VERSION ""

NS_ :

BS_:

BU_: ECM

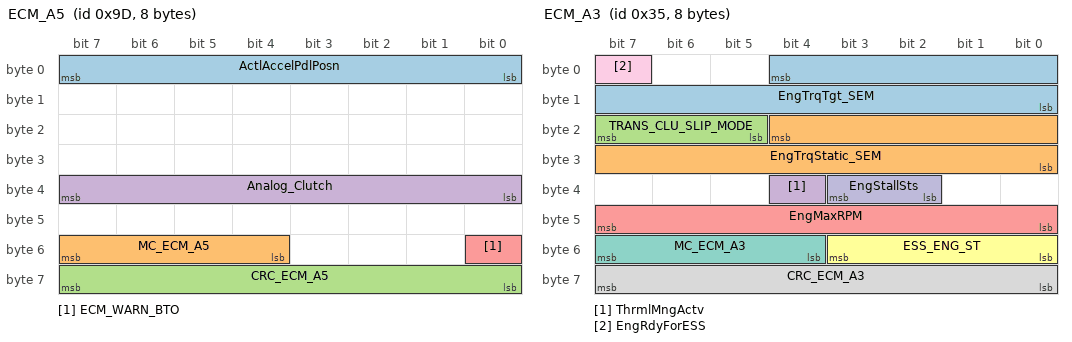
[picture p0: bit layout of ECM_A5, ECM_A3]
BO_ 157 ECM_A5: 8 ECM
 SG_ ActlAccelPdlPosn : 0|8@1+ (0.4,0) [0|100] "%"  Vector__XXX
 SG_ MC_ECM_A5 : 52|4@1+ (1,0) [0|15] "" Vector__XXX
 SG_ CRC_ECM_A5 : 56|8@1+ (1,0) [0|0] "" Vector__XXX
 SG_ Analog_Clutch : 32|8@1+ (0.4,0) [0|100] "%"  Vector__XXX
 SG_ ECM_WARN_BTO : 48|1@1+ (1,0) [0|0] "" Vector__XXX

BO_ 53 ECM_A3: 8 ECM
 SG_ EngTrqTgt_SEM : 4|13@0+ (0.25,-500) [-500|1547.5] "Nm"  Vector__XXX
 SG_ EngTrqStatic_SEM : 20|13@0+ (0.25,-500) [-500|1547.5] "Nm"  Vector__XXX
 SG_ TRANS_CLU_SLIP_MODE : 21|3@1+ (1,0) [0|0] "" Vector__XXX
 SG_ ThrmlMngActv : 36|1@1+ (1,0) [0|0] "" Vector__XXX
 SG_ EngMaxRPM : 40|8@1+ (50,0) [0|12700] "rpm"  Vector__XXX
 SG_ ESS_ENG_ST : 48|4@1+ (1,0) [0|0] "" Vector__XXX
 SG_ MC_ECM_A3 : 52|4@1+ (1,0) [0|15] "" Vector__XXX
 SG_ CRC_ECM_A3 : 56|8@1+ (1,0) [0|0] "" Vector__XXX
 SG_ EngRdyForESS : 7|1@1+ (1,0) [0|0] "" Vector__XXX
 SG_ EngStallSts : 34|2@1+ (1,0) [0|0] "" Vector__XXX

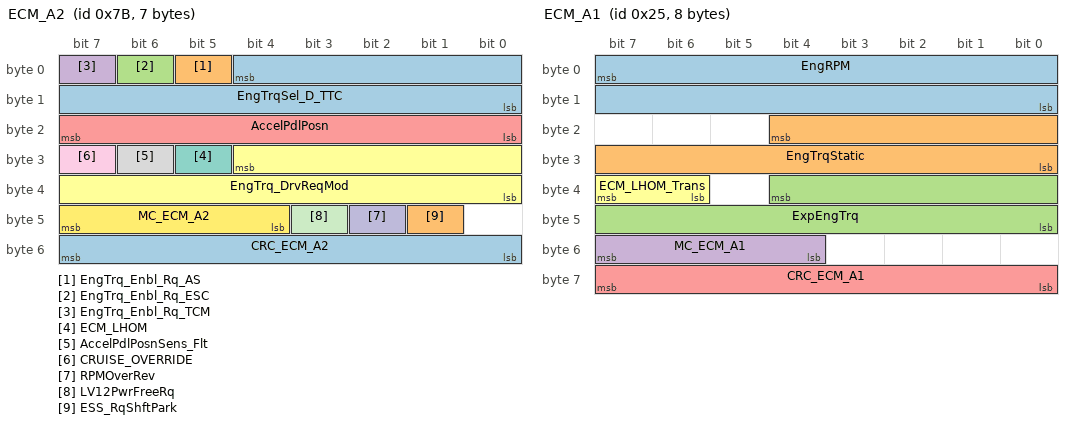
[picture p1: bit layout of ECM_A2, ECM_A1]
BO_ 123 ECM_A2: 7 ECM
 SG_ EngTrqSel_D_TTC : 4|13@0+ (0.25,-500) [-500|1547.5] "Nm"  Vector__XXX
 SG_ EngTrq_Enbl_Rq_AS : 5|1@1+ (1,0) [0|0] "" Vector__XXX
 SG_ EngTrq_Enbl_Rq_ESC : 6|1@1+ (1,0) [0|0] "" Vector__XXX
 SG_ EngTrq_Enbl_Rq_TCM : 7|1@1+ (1,0) [0|0] "" Vector__XXX
 SG_ AccelPdlPosn : 16|8@1+ (0.4,0) [0|100] "%"  Vector__XXX
 SG_ EngTrq_DrvReqMod : 28|13@0+ (0.25,-500) [-500|1547.5] "Nm"  Vector__XXX
 SG_ ECM_LHOM : 29|1@1+ (1,0) [0|0] "" Vector__XXX
 SG_ AccelPdlPosnSens_Flt : 30|1@1+ (1,0) [0|0] "" Vector__XXX
 SG_ CRUISE_OVERRIDE : 31|1@1+ (1,0) [0|0] "" Vector__XXX
 SG_ RPMOverRev : 42|1@1+ (1,0) [0|0] "" Vector__XXX
 SG_ LV12PwrFreeRq : 43|1@1+ (1,0) [0|0] "" Vector__XXX
 SG_ MC_ECM_A2 : 44|4@1+ (1,0) [0|15] "" Vector__XXX
 SG_ CRC_ECM_A2 : 48|8@1+ (1,0) [0|0] "" Vector__XXX
 SG_ ESS_RqShftPark : 41|1@1+ (1,0) [0|0] "" Vector__XXX

BO_ 37 ECM_A1: 8 ECM
 SG_ EngRPM : 7|16@0+ (1,0) [0|65534] "rpm"  Vector__XXX
 SG_ EngTrqStatic : 20|13@0+ (0.25,-500) [-500|1547.5] "Nm"  Vector__XXX
 SG_ ExpEngTrq : 36|13@0+ (0.25,-500) [-500|1547.5] "Nm"  Vector__XXX
 SG_ MC_ECM_A1 : 52|4@1+ (1,0) [0|15] "" Vector__XXX
 SG_ CRC_ECM_A1 : 56|8@1+ (1,0) [0|0] "" Vector__XXX
 SG_ ECM_LHOM_Trans : 38|2@1+ (1,0) [0|0] "" Vector__XXX

BO_ 631 DTCM_B1: 8 Vector__XXX
 SG_ TCASE_FAIL : 0|1@1+ (1,0) [0|0] "" ECM

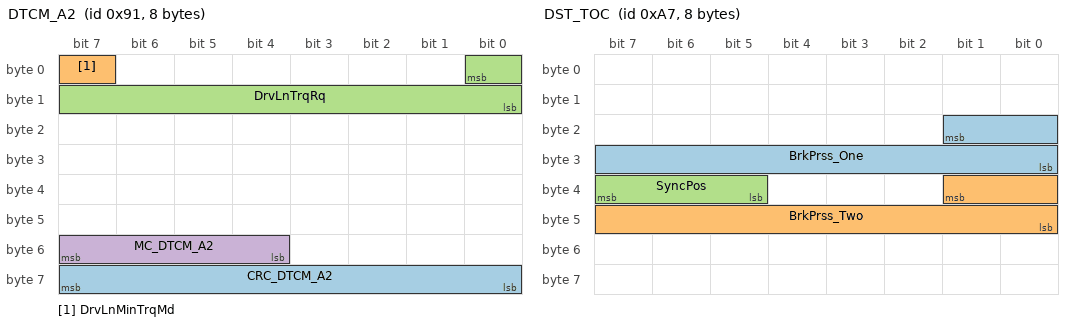
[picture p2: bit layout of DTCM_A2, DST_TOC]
BO_ 145 DTCM_A2: 8 Vector__XXX
 SG_ CRC_DTCM_A2 : 56|8@1+ (1,0) [0|0] "" ECM
 SG_ DrvLnMinTrqMd : 7|1@1+ (1,0) [0|0] "" ECM
 SG_ DrvLnTrqRq : 0|9@0+ (2,0) [0|1020] "Nm"  ECM
 SG_ MC_DTCM_A2 : 52|4@1+ (1,0) [0|15] "" ECM

BO_ 141 DTCM_A1: 8 Vector__XXX
 SG_ TCASE_STAT : 1|3@1+ (1,0) [0|0] "" ECM
 SG_ TCASERANGESTATUS : 12|2@1+ (1,0) [0|0] "" ECM

BO_ 167 DST_TOC: 8 Vector__XXX
 SG_ BrkPrss_One : 17|10@0+ (0.0048828125,0) [0|4.9951171875] "Volts"  ECM
 SG_ BrkPrss_Two : 33|10@0+ (0.0048828125,0) [0|4.9951171875] "Volts"  ECM
 SG_ SyncPos : 37|3@1+ (1,0) [0|0] "" ECM

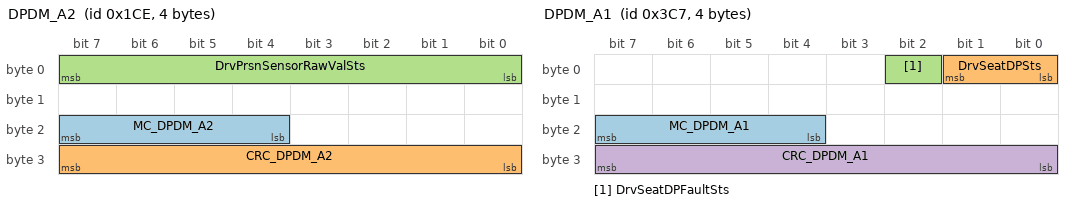
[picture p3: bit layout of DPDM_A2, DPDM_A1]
BO_ 462 DPDM_A2: 4 Vector__XXX
 SG_ MC_DPDM_A2 : 20|4@1+ (1,0) [0|15] "" ECM
 SG_ CRC_DPDM_A2 : 24|8@1+ (1,0) [0|0] "" ECM
 SG_ DrvPrsnSensorRawValSts : 0|8@1+ (1,0) [0|255] "" ECM

BO_ 967 DPDM_A1: 4 Vector__XXX
 SG_ MC_DPDM_A1 : 20|4@1+ (1,0) [0|15] "" ECM
 SG_ DrvSeatDPSts : 0|2@1+ (1,0) [0|0] "" ECM
 SG_ DrvSeatDPFaultSts : 2|1@1+ (1,0) [0|0] "" ECM
 SG_ CRC_DPDM_A1 : 24|8@1+ (1,0) [0|0] "" ECM

BO_ 163 DAS_A5: 8 Vector__XXX
 SG_ DsrSpeed_KPH : 24|8@1+ (1,0) [0|250] "km/h"  ECM

BO_ 232 DAS_A4: 8 Vector__XXX
 SG_ SetSpeed_KPH : 8|8@1+ (1,0) [0|250] "km/h"  ECM
 SG_ ACCOnOff : 36|3@1+ (1,0) [0|0] "" ECM

BO_ 153 DAS_A3: 8 Vector__XXX
 SG_ DAS_ACCEL_Rq : 19|12@0+ (0.004885,-16) [-16|4] "m/s²"  ECM

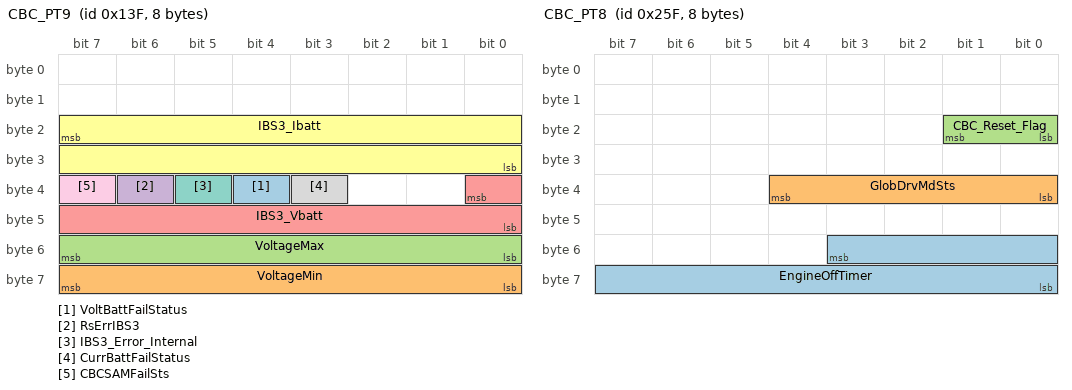
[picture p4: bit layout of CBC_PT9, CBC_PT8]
BO_ 319 CBC_PT9: 8 Vector__XXX
 SG_ VoltBattFailStatus : 36|1@1+ (1,0) [0|0] "" ECM
 SG_ VoltageMin : 56|8@1+ (0.025,10.6) [10.6|16.975] "Volts"  ECM
 SG_ VoltageMax : 48|8@1+ (0.025,10.6) [10.6|16.975] "Volts"  ECM
 SG_ RsErrIBS3 : 38|1@1+ (1,0) [0|0] "" ECM
 SG_ IBS3_Vbatt : 32|9@0+ (0.025,5) [5|17.75] "V"  ECM
 SG_ IBS3_Ibatt : 23|16@0+ (0.02,-1000) [-1000|310.68] "A"  ECM
 SG_ IBS3_Error_Internal : 37|1@1+ (1,0) [0|0] "" ECM
 SG_ CurrBattFailStatus : 35|1@1+ (1,0) [0|0] "" ECM
 SG_ CBCSAMFailSts : 39|1@1+ (1,0) [0|0] "" ECM

BO_ 607 CBC_PT8: 8 Vector__XXX
 SG_ EngineOffTimer : 51|12@0+ (1,0) [0|4080] "min"  ECM
 SG_ GlobDrvMdSts : 32|5@1+ (1,0) [0|0] "" ECM
 SG_ CBC_Reset_Flag : 16|2@1+ (1,0) [0|0] "" ECM

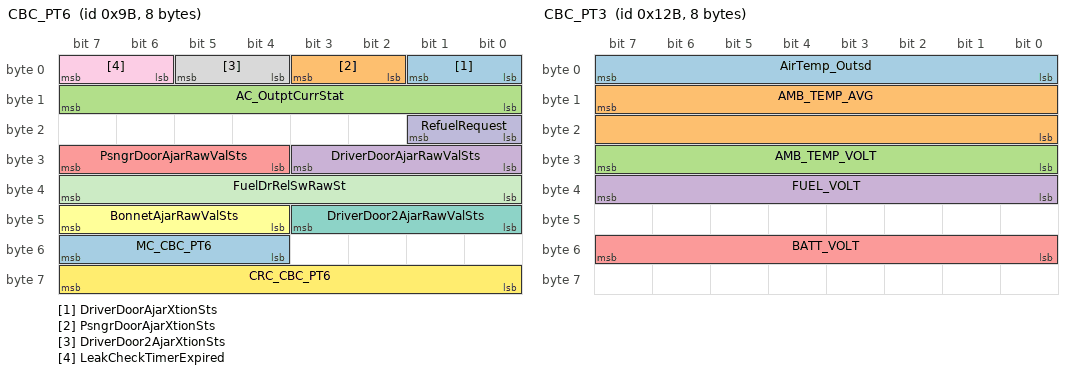
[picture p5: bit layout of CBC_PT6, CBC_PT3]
BO_ 155 CBC_PT6: 8 Vector__XXX
 SG_ DriverDoorAjarXtionSts : 0|2@1+ (1,0) [0|0] "" ECM
 SG_ PsngrDoorAjarXtionSts : 2|2@1+ (1,0) [0|0] "" ECM
 SG_ AC_OutptCurrStat : 8|8@1+ (0.008,0) [0|2] "Amp"  ECM
 SG_ DriverDoorAjarRawValSts : 24|4@1+ (1,0) [0|0] "" ECM
 SG_ PsngrDoorAjarRawValSts : 28|4@1+ (1,0) [0|0] "" ECM
 SG_ BonnetAjarRawValSts : 44|4@1+ (1,0) [0|0] "" ECM
 SG_ DriverDoor2AjarRawValSts : 40|4@1+ (1,0) [0|0] "" ECM
 SG_ DriverDoor2AjarXtionSts : 4|2@1+ (1,0) [0|0] "" ECM
 SG_ LeakCheckTimerExpired : 6|2@1+ (1,0) [0|0] "" ECM
 SG_ RefuelRequest : 16|2@1+ (1,0) [0|0] "" ECM
 SG_ FuelDrRelSwRawSt : 32|8@1+ (0.019607843,0) [0|4.98] "Volts"  ECM
 SG_ CRC_CBC_PT6 : 56|8@1+ (1,0) [0|0] "" ECM
 SG_ MC_CBC_PT6 : 52|4@1+ (1,0) [0|15] "" ECM

BO_ 299 CBC_PT3: 8 Vector__XXX
 SG_ AirTemp_Outsd : 0|8@1+ (0.5,-40) [-40|85] "°C"  ECM
 SG_ AMB_TEMP_AVG : 15|16@0+ (0.01,-40) [-40|85] "°C"  ECM
 SG_ AMB_TEMP_VOLT : 24|8@1+ (0.019607843,0) [0|4.98] "Volts"  ECM
 SG_ FUEL_VOLT : 32|8@1+ (0.019607843,0) [0|4.98] "Volts"  ECM
 SG_ BATT_VOLT : 48|8@1+ (0.1,0) [5|18] "Volts"  ECM

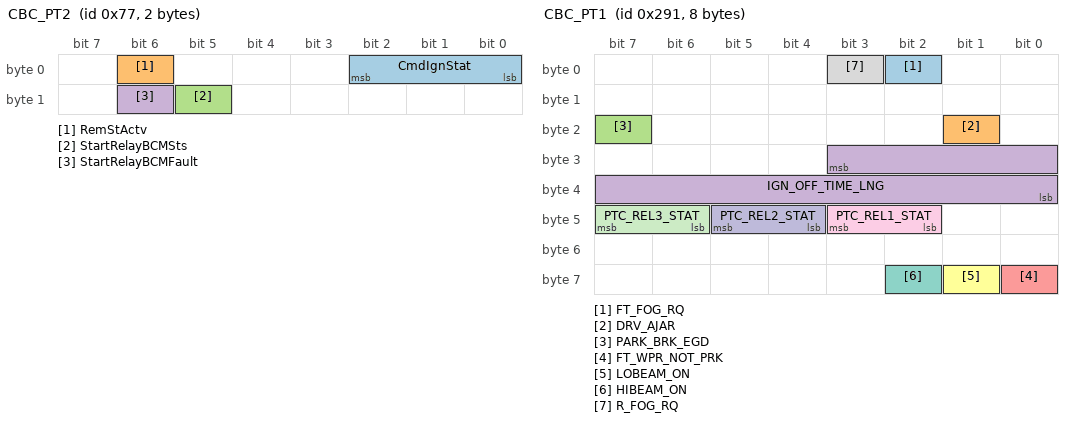
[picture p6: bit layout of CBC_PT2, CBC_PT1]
BO_ 119 CBC_PT2: 2 Vector__XXX
 SG_ CmdIgnStat : 0|3@1+ (1,0) [0|0] "" ECM
 SG_ RemStActv : 6|1@1+ (1,0) [0|0] "" ECM
 SG_ StartRelayBCMSts : 13|1@1+ (1,0) [0|0] "" ECM
 SG_ StartRelayBCMFault : 14|1@1+ (1,0) [0|0] "" ECM

BO_ 657 CBC_PT1: 8 Vector__XXX
 SG_ FT_FOG_RQ : 2|1@1+ (1,0) [0|0] "" ECM
 SG_ DRV_AJAR : 17|1@1+ (1,0) [0|0] "" ECM
 SG_ PARK_BRK_EGD : 23|1@1+ (1,0) [0|0] "" ECM
 SG_ IGN_OFF_TIME_LNG : 27|12@0+ (1,0) [0|4080] "min"  ECM
 SG_ FT_WPR_NOT_PRK : 56|1@1+ (1,0) [0|0] "" ECM
 SG_ LOBEAM_ON : 57|1@1+ (1,0) [0|0] "" ECM
 SG_ HIBEAM_ON : 58|1@1+ (1,0) [0|0] "" ECM
 SG_ R_FOG_RQ : 3|1@1+ (1,0) [0|0] "" ECM
 SG_ PTC_REL1_STAT : 42|2@1+ (1,0) [0|0] "" ECM
 SG_ PTC_REL2_STAT : 44|2@1+ (1,0) [0|0] "" ECM
 SG_ PTC_REL3_STAT : 46|2@1+ (1,0) [0|0] "" ECM

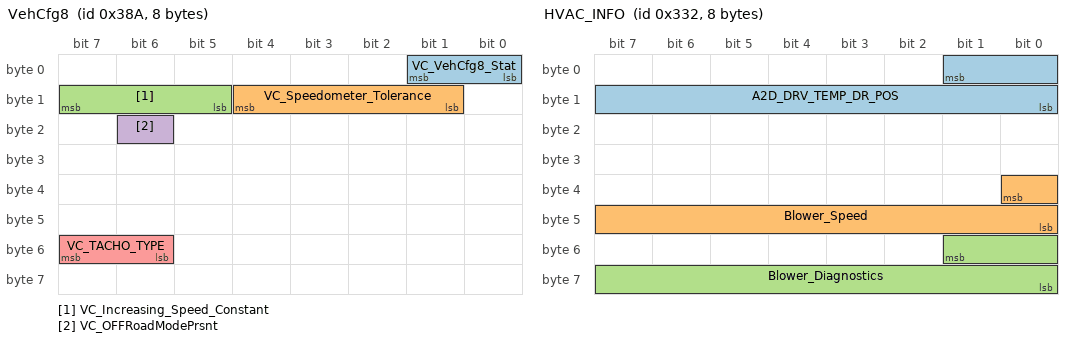
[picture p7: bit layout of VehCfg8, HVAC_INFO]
BO_ 906 VehCfg8: 8 Vector__XXX
 SG_ VC_VehCfg8_Stat : 0|2@1+ (1,0) [0|0] "" ECM
 SG_ VC_Speedometer_Tolerance : 9|4@1+ (1,0) [0|0] "" ECM
 SG_ VC_Increasing_Speed_Constant : 13|3@1+ (1,0) [0|0] "" ECM
 SG_ VC_OFFRoadModePrsnt : 22|1@1+ (1,0) [0|0] "" ECM
 SG_ VC_TACHO_TYPE : 54|2@1+ (1,0) [0|0] "" ECM

BO_ 738 ESP_B4: 8 Vector__XXX
 SG_ REPRGD_PFC_CLR_ESC : 22|1@1+ (1,0) [0|0] "" ECM

BO_ 818 HVAC_INFO: 8 Vector__XXX
 SG_ A2D_DRV_TEMP_DR_POS : 1|10@0+ (0.00489237,0) [0|5] "V"  ECM
 SG_ Blower_Speed : 32|9@0+ (1,0) [0|350] "Hz"  ECM
 SG_ Blower_Diagnostics : 49|10@0+ (0.1,0) [0|100] "%"  ECM

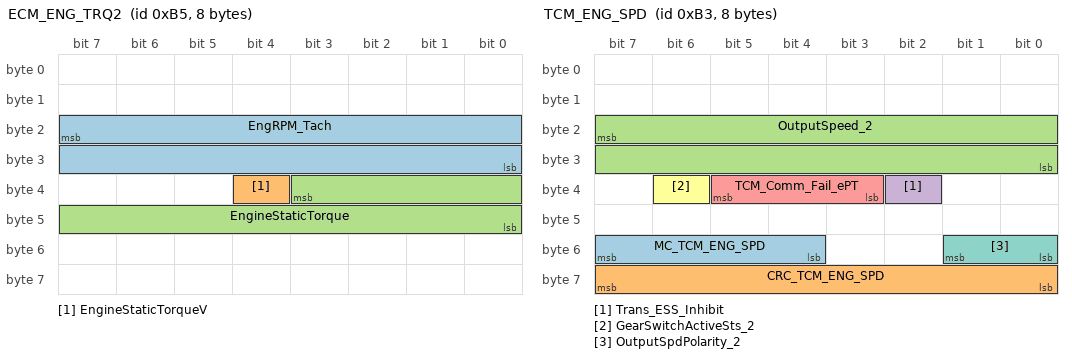
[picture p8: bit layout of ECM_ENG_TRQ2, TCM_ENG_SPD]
BO_ 181 ECM_ENG_TRQ2: 8 ECM
 SG_ EngRPM_Tach : 23|16@0+ (1,0) [0|65534] "RPM"  Vector__XXX
 SG_ EngineStaticTorqueV : 36|1@1+ (1,0) [0|0] "" Vector__XXX
 SG_ EngineStaticTorque : 35|12@0+ (0.32,-300.16) [-300.16|1008] "Nm"  Vector__XXX

BO_ 833 GPF_DATA_1: 8 Vector__XXX
 SG_ GPF_T1_Status : 48|5@1+ (1,0) [0|0] "" ECM
 SG_ GPF_T1_TEMP : 7|16@0+ (0.03125,-273) [-273|1774.97] "deg"  ECM

BO_ 179 TCM_ENG_SPD: 8 Vector__XXX
 SG_ MC_TCM_ENG_SPD : 52|4@1+ (1,0) [0|15] "" ECM
 SG_ CRC_TCM_ENG_SPD : 56|8@1+ (1,0) [0|0] "" ECM
 SG_ OutputSpeed_2 : 23|16@0+ (1,0) [0|65534] "rpm"  ECM
 SG_ Trans_ESS_Inhibit : 34|1@1+ (1,0) [0|0] "" ECM
 SG_ TCM_Comm_Fail_ePT : 35|3@1+ (1,0) [0|0] "" ECM
 SG_ GearSwitchActiveSts_2 : 38|1@1+ (1,0) [0|0] "" ECM
 SG_ OutputSpdPolarity_2 : 48|2@1+ (1,0) [0|0] "" ECM

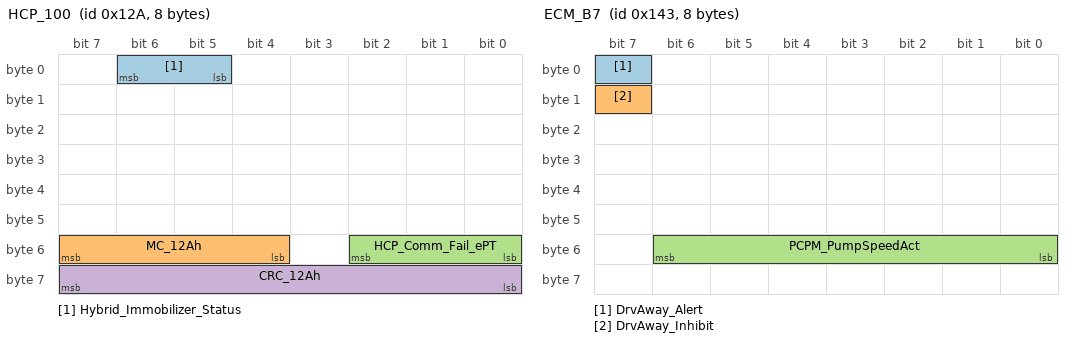
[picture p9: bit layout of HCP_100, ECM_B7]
BO_ 298 HCP_100: 8 Vector__XXX
 SG_ Hybrid_Immobilizer_Status : 5|2@1+ (1,0) [0|0] "" ECM
 SG_ MC_12Ah : 52|4@1+ (1,0) [0|15] "" ECM
 SG_ HCP_Comm_Fail_ePT : 48|3@1+ (1,0) [0|0] "" ECM
 SG_ CRC_12Ah : 56|8@1+ (1,0) [0|0] "" ECM

BO_ 307 CBC_PT7: 8 Vector__XXX
 SG_ AM_ECM_Trace : 22|2@1+ (1,0) [0|0] "" ECM

BO_ 323 ECM_B7: 8 ECM
 SG_ DrvAway_Alert : 7|1@1+ (1,0) [0|0] "" Vector__XXX
 SG_ DrvAway_Inhibit : 15|1@1+ (1,0) [0|0] "" Vector__XXX
 SG_ PCPM_PumpSpeedAct : 48|7@1+ (1,0) [0|100] "%"  Vector__XXX

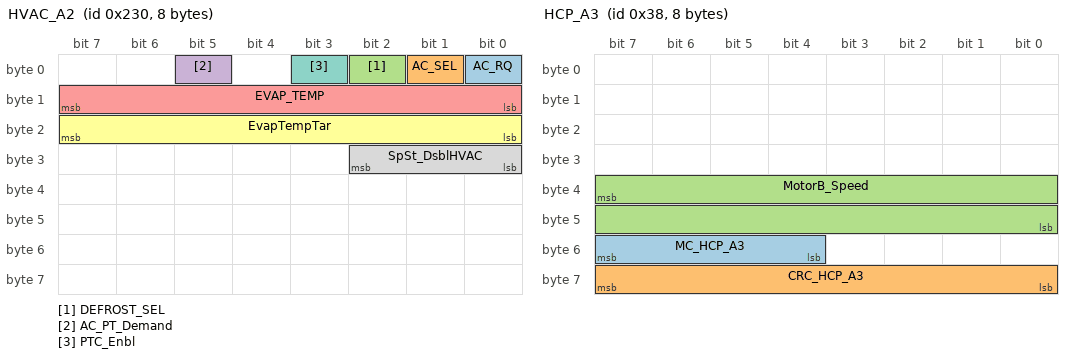
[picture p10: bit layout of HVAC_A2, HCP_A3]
BO_ 560 HVAC_A2: 8 Vector__XXX
 SG_ AC_RQ : 0|1@1+ (1,0) [0|0] "" ECM
 SG_ AC_SEL : 1|1@1+ (1,0) [0|0] "" ECM
 SG_ DEFROST_SEL : 2|1@1+ (1,0) [0|0] "" ECM
 SG_ AC_PT_Demand : 5|1@1+ (1,0) [0|0] "" ECM
 SG_ EVAP_TEMP : 8|8@1+ (0.5,-20) [-20|107] "°C"  ECM
 SG_ EvapTempTar : 16|8@1+ (0.5,-20) [-20|107] "°C"  ECM
 SG_ PTC_Enbl : 3|1@1+ (1,0) [0|0] "" ECM
 SG_ SpSt_DsblHVAC : 24|3@1+ (1,0) [0|0] "" ECM

BO_ 56 HCP_A3: 8 Vector__XXX
 SG_ MC_HCP_A3 : 52|4@1+ (1,0) [0|15] "" ECM
 SG_ CRC_HCP_A3 : 56|8@1+ (1,0) [0|0] "" ECM
 SG_ MotorB_Speed : 39|16@0+ (1,-16382) [-16382|49151] "rpm"  ECM

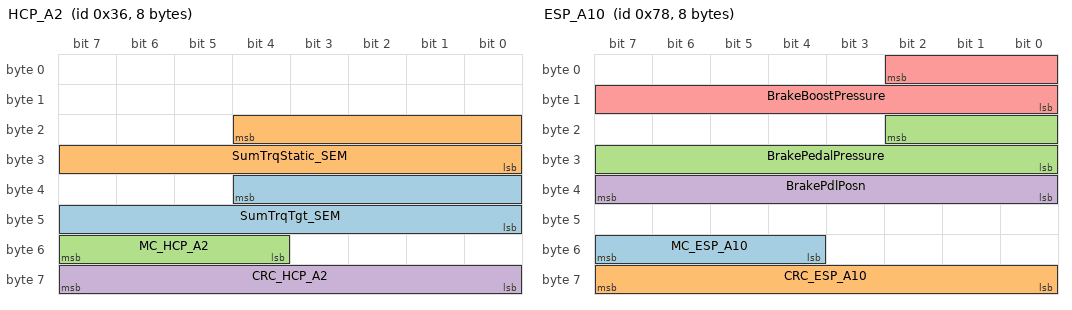
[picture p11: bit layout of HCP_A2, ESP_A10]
BO_ 54 HCP_A2: 8 Vector__XXX
 SG_ SumTrqTgt_SEM : 36|13@0+ (0.25,-500) [-500|1547.5] "Nm"  ECM
 SG_ SumTrqStatic_SEM : 20|13@0+ (0.25,-500) [-500|1547.5] "Nm"  ECM
 SG_ MC_HCP_A2 : 52|4@1+ (1,0) [0|15] "" ECM
 SG_ CRC_HCP_A2 : 56|8@1+ (1,0) [0|0] "" ECM

BO_ 40 HCP_A1: 8 Vector__XXX
 SG_ MC_HCP_A1 : 52|4@1+ (1,0) [0|15] "" ECM
 SG_ CRC_HCP_A1 : 56|8@1+ (1,0) [0|0] "" ECM

BO_ 120 ESP_A10: 8 Vector__XXX
 SG_ MC_ESP_A10 : 52|4@1+ (1,0) [0|15] "" ECM
 SG_ CRC_ESP_A10 : 56|8@1+ (1,0) [0|0] "" ECM
 SG_ BrakePedalPressure : 18|11@0+ (0.1,0) [0|200] "bar"  ECM
 SG_ BrakePdlPosn : 32|8@1+ (0.4,0) [0|100] "%"  ECM
 SG_ BrakeBoostPressure : 2|11@0+ (0.1,0) [0|200] "bar"  ECM

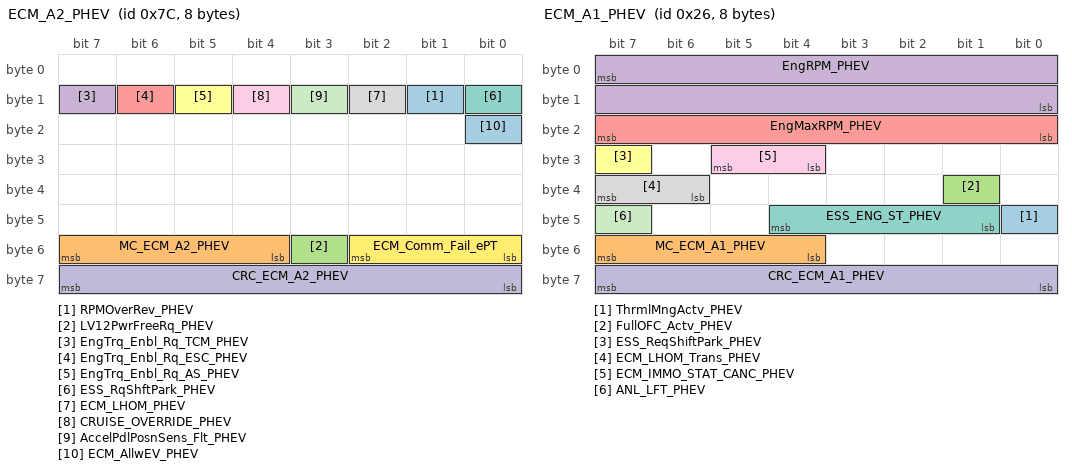
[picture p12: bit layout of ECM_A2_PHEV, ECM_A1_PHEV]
BO_ 124 ECM_A2_PHEV: 8 ECM
 SG_ RPMOverRev_PHEV : 9|1@1+ (1,0) [0|0] "" Vector__XXX
 SG_ MC_ECM_A2_PHEV : 52|4@1+ (1,0) [0|15] "" Vector__XXX
 SG_ LV12PwrFreeRq_PHEV : 51|1@1+ (1,0) [0|0] "" Vector__XXX
 SG_ EngTrq_Enbl_Rq_TCM_PHEV : 15|1@1+ (1,0) [0|0] "" Vector__XXX
 SG_ EngTrq_Enbl_Rq_ESC_PHEV : 14|1@1+ (1,0) [0|0] "" Vector__XXX
 SG_ EngTrq_Enbl_Rq_AS_PHEV : 13|1@1+ (1,0) [0|0] "" Vector__XXX
 SG_ ESS_RqShftPark_PHEV : 8|1@1+ (1,0) [0|0] "" Vector__XXX
 SG_ ECM_LHOM_PHEV : 10|1@1+ (1,0) [0|0] "" Vector__XXX
 SG_ CRUISE_OVERRIDE_PHEV : 12|1@1+ (1,0) [0|0] "" Vector__XXX
 SG_ CRC_ECM_A2_PHEV : 56|8@1+ (1,0) [0|0] "" Vector__XXX
 SG_ AccelPdlPosnSens_Flt_PHEV : 11|1@1+ (1,0) [0|0] "" Vector__XXX
 SG_ ECM_Comm_Fail_ePT : 48|3@1+ (1,0) [0|0] "" Vector__XXX
 SG_ ECM_AllwEV_PHEV : 16|1@1+ (1,0) [0|0] "" Vector__XXX

BO_ 38 ECM_A1_PHEV: 8 ECM
 SG_ ThrmlMngActv_PHEV : 40|1@1+ (1,0) [0|0] "" Vector__XXX
 SG_ MC_ECM_A1_PHEV : 52|4@1+ (1,0) [0|15] "" Vector__XXX
 SG_ FullOFC_Actv_PHEV : 33|1@1+ (1,0) [0|0] "" Vector__XXX
 SG_ EngRPM_PHEV : 7|16@0+ (1,0) [0|65534] "rpm"  Vector__XXX
 SG_ EngMaxRPM_PHEV : 16|8@1+ (50,0) [0|12700] "rpm"  Vector__XXX
 SG_ ESS_ReqShiftPark_PHEV : 31|1@1+ (1,0) [0|0] "" Vector__XXX
 SG_ ESS_ENG_ST_PHEV : 41|4@1+ (1,0) [0|0] "" Vector__XXX
 SG_ ECM_LHOM_Trans_PHEV : 38|2@1+ (1,0) [0|0] "" Vector__XXX
 SG_ ECM_IMMO_STAT_CANC_PHEV : 28|2@1+ (1,0) [0|0] "" Vector__XXX
 SG_ CRC_ECM_A1_PHEV : 56|8@1+ (1,0) [0|0] "" Vector__XXX
 SG_ ANL_LFT_PHEV : 47|1@1+ (1,0) [0|0] "" Vector__XXX

BO_ 117 ESP_A9: 8 Vector__XXX
 SG_ MC_10Eh : 52|4@1+ (1,0) [0|15] "" ECM
 SG_ CRC_10Eh : 56|8@1+ (1,0) [0|255] "" ECM

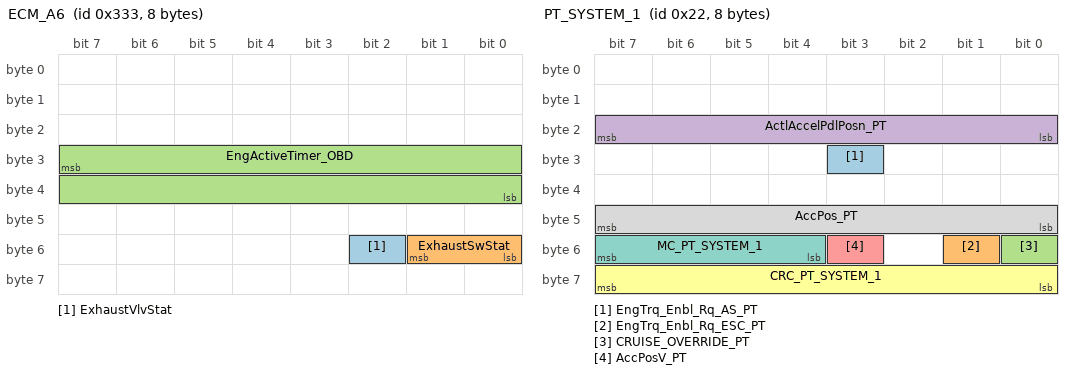
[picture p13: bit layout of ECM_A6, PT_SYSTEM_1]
BO_ 819 ECM_A6: 8 ECM
 SG_ ExhaustVlvStat : 50|1@1+ (1,0) [0|0] "" Vector__XXX
 SG_ ExhaustSwStat : 48|2@1+ (1,0) [0|0] "" Vector__XXX
 SG_ EngActiveTimer_OBD : 31|16@0+ (1,0) [0|0] "seconds"  Vector__XXX

BO_ 834 GLIWA_T1_TX: 8 ECM
 SG_ N_PDU_342 : 7|64@0+ (1,0) [0|0] "" Vector__XXX

BO_ 835 GLIWA_T1_RX: 8 Vector__XXX
 SG_ N_PDU_343 : 7|64@0+ (1,0) [0|0] "" ECM

BO_ 34 PT_SYSTEM_1: 8 Vector__XXX
 SG_ EngTrq_Enbl_Rq_AS_PT : 27|1@1+ (1,0) [0|0] "" ECM
 SG_ EngTrq_Enbl_Rq_ESC_PT : 49|1@1+ (1,0) [0|0] "" ECM
 SG_ CRUISE_OVERRIDE_PT : 48|1@1+ (1,0) [0|0] "" ECM
 SG_ ActlAccelPdlPosn_PT : 16|8@1+ (0.4,0) [0|102] "%"  ECM
 SG_ AccPosV_PT : 51|1@1+ (1,0) [0|0] "" ECM
 SG_ CRC_PT_SYSTEM_1 : 56|8@1+ (1,0) [0|0] "" ECM
 SG_ MC_PT_SYSTEM_1 : 52|4@1+ (1,0) [0|15] "" ECM
 SG_ AccPos_PT : 40|8@1+ (0.392157,0) [0|99.607878] "%"  ECM

CM_ SG_ 967 CRC_DPDM_A1 "CRC-checksum byte 1 to 5 according to SAE J1850";
CM_ SG_ 967 DrvSeatDPFaultSts "Driver Detection Fault Status";
CM_ SG_ 967 DrvSeatDPSts "Driver Presence Status";
CM_ SG_ 967 MC_DPDM_A1 "Message counter";
CM_ SG_ 906 VC_TACHO_TYPE "CBC VC Config of Tachometer Type";
CM_ SG_ 906 VC_OFFRoadModePrsnt "OFF ROAD MODE Present, Present = 1";
CM_ SG_ 906 VC_Increasing_Speed_Constant "Increasing Speed Constant (Offset for Speedometer Biasing)";
CM_ SG_ 906 VC_Speedometer_Tolerance "Speedometer Tolerance Percentage (Gain for Speedometer Biasing)";
CM_ SG_ 906 VC_VehCfg8_Stat "Configuration messages status 8";
CM_ SG_ 835 N_PDU_343 "N_PDU";
CM_ SG_ 833 GPF_T1_TEMP "PRE GPF Temperature Sensor";
CM_ SG_ 833 GPF_T1_Status "PRE GPF Temperature Sensor Status";
CM_ SG_ 818 Blower_Diagnostics "Duty cycle Feedback received from the Blower";
CM_ SG_ 818 Blower_Speed "Frequency Feedback received from the Blower";
CM_ SG_ 818 A2D_DRV_TEMP_DR_POS "Transmit raw A/D driver temp door position to ECM to make OBD model more robust";
CM_ SG_ 738 REPRGD_PFC_CLR_ESC "Set readiness to 'incomplete'; 0 = Do nothing; 1= Set incomplete";
CM_ SG_ 657 PTC_REL1_STAT "PTC Relay # 1 Status";
CM_ SG_ 657 R_FOG_RQ "Rear fog request; [0] = off, [1] = on";
CM_ SG_ 657 HIBEAM_ON "High beam is on; off=[0], on=[1]";
CM_ SG_ 657 PTC_REL3_STAT "PTC Relay # 3 Status";
CM_ SG_ 657 PTC_REL2_STAT "PTC Relay # 2 Status";
CM_ SG_ 657 LOBEAM_ON "Low beam is on; off=[0], on=[1]";
CM_ SG_ 657 FT_WPR_NOT_PRK "Front wiper outside park position";
CM_ SG_ 657 IGN_OFF_TIME_LNG "Time since last ignition on (long)";
CM_ SG_ 657 PARK_BRK_EGD "Park brake switch engaged";
CM_ SG_ 657 DRV_AJAR "Driver door ajar (1 = Door Ajar)";
CM_ SG_ 657 FT_FOG_RQ "Front fog request; off=[0], on=[1]";
CM_ SG_ 631 TCASE_FAIL "T Case System Fault (Limp in)";
CM_ SG_ 607 GlobDrvMdSts "Global drive mode status";
CM_ SG_ 607 CBC_Reset_Flag "CBC reset flag";
CM_ SG_ 607 EngineOffTimer "Engine off timer - engine off ignition NOT lock.";
CM_ SG_ 560 SpSt_DsblHVAC "Stop start disable from HVAC";
CM_ SG_ 560 PTC_Enbl "PTC heater enable; [1] = enable";
CM_ SG_ 560 EvapTempTar "Evaporator temperature target";
CM_ SG_ 560 EVAP_TEMP "AC evaporator temperature";
CM_ SG_ 560 AC_PT_Demand "Maximum A/C demand to powertrain";
CM_ SG_ 560 DEFROST_SEL "Defrost select switch";
CM_ SG_ 560 AC_SEL "Customer has selected A/C; [1] = A/C selected; 0 = A/C not selected";
CM_ SG_ 560 AC_RQ "A/C clutch request; [1] = A/C Clutch requested; 0 = A/C Clutch not requested";
CM_ SG_ 462 DrvPrsnSensorRawValSts "Pressure sensor raw value status";
CM_ SG_ 462 CRC_DPDM_A2 "CRC-checksum byte 1 to 5 according to SAE J1850";
CM_ SG_ 462 MC_DPDM_A2 "Message counter";
CM_ SG_ 319 CBCSAMFailSts "Fault present in BCM related to the SAM strategy";
CM_ SG_ 319 CurrBattFailStatus "Failure Status of Current meas. (internal defect)";
CM_ SG_ 319 IBS3_Error_Internal "Error in IBS calibration data; No Error = [0], Error = [1]";
CM_ SG_ 319 IBS3_Ibatt "Battery current";
CM_ SG_ 319 IBS3_Vbatt "Battery voltage measured at the terminals";
CM_ SG_ 319 RsErrIBS3 "Response Error IBS; Error=[1]";
CM_ SG_ 319 VoltageMax "Maximum regulation voltage permitted by CBC in the SAM strategy";
CM_ SG_ 319 VoltageMin "Minimum regulation voltage permitted by CBC in the SAM strategy";
CM_ SG_ 319 VoltBattFailStatus "Failure Status of Voltage meas. (internal defect)";
CM_ SG_ 307 AM_ECM_Trace "Aftermarket ECM trace";
CM_ SG_ 299 BATT_VOLT "System voltage";
CM_ SG_ 299 FUEL_VOLT "Fuel level A/D Voltage (Single tank OR Primary on Saddle/Dual Tank)";
CM_ SG_ 299 AMB_TEMP_VOLT "Ambient Temp Sensor A/D Voltage";
CM_ SG_ 299 AMB_TEMP_AVG "Averaged ambient temperature";
CM_ SG_ 299 AirTemp_Outsd "Outside air temperature";
CM_ SG_ 298 CRC_12Ah "CRC-checksum byte 1 to 7 according to SAE J1850";
CM_ SG_ 298 HCP_Comm_Fail_ePT "HCP_Comm_Fail_ePT";
CM_ SG_ 298 MC_12Ah "Message counter";
CM_ SG_ 298 Hybrid_Immobilizer_Status "System shutdown command from HCP";
CM_ SG_ 232 ACCOnOff "ACC on off status";
CM_ SG_ 232 SetSpeed_KPH "Desired set speed in kilometers per hour";
CM_ SG_ 179 Trans_ESS_Inhibit "Trans_ESS_Inhibit";
CM_ SG_ 179 OutputSpeed_2 "Output Shaft Speed from 0 - 65534 RPM with 1 RPM resolution.";
CM_ SG_ 179 CRC_TCM_ENG_SPD "CRC-checksum byte 1 to 7 according to SAE J1850";
CM_ SG_ 179 MC_TCM_ENG_SPD "Message counter   TCM_ENG_SPD";
CM_ SG_ 179 OutputSpdPolarity_2 "Transmission output speed polarity Direction not determined Direction forward Direction backward Signal not available";
CM_ SG_ 179 GearSwitchActiveSts_2 "Transmission shift in progress; Inactive=0, Active =1";
CM_ SG_ 179 TCM_Comm_Fail_ePT "TCM_Comm_Fail_ePT";
CM_ SG_ 167 SyncPos "Signal P2 sync position";
CM_ SG_ 167 BrkPrss_Two "Brake Pressure Two (P2 if supported)";
CM_ SG_ 167 BrkPrss_One "Brake Pressure One (P1)";
CM_ SG_ 163 DsrSpeed_KPH "Desired speed in kilometers per hour";
CM_ SG_ 155 RefuelRequest "Driver has initiated a refueling event";
CM_ SG_ 155 LeakCheckTimerExpired "Status of leak test timer";
CM_ SG_ 155 DriverDoor2AjarXtionSts "Drivers door switch - 2 ajar transition status";
CM_ SG_ 155 DriverDoor2AjarRawValSts "Drivers door switch - 2 ajar status";
CM_ SG_ 155 MC_CBC_PT6 "Message Counter";
CM_ SG_ 155 CRC_CBC_PT6 "CRC-Checksum Byte 1 - 7 according to SAE J1850";
CM_ SG_ 155 FuelDrRelSwRawSt "Raw voltage of fuel door release switch in the cabin";
CM_ SG_ 155 BonnetAjarRawValSts "Hood ajar status";
CM_ SG_ 155 PsngrDoorAjarRawValSts "Passengers door ajar status";
CM_ SG_ 155 DriverDoorAjarRawValSts "Drivers door ajar status";
CM_ SG_ 155 AC_OutptCurrStat "AC output current status";
CM_ SG_ 155 PsngrDoorAjarXtionSts "Front passenger door ajar transition status";
CM_ SG_ 155 DriverDoorAjarXtionSts "Drivers door ajar transition status";
CM_ SG_ 153 DAS_ACCEL_Rq "DASM acceleration request";
CM_ SG_ 145 MC_DTCM_A2 "Message counter";
CM_ SG_ 145 DrvLnTrqRq "Drive line requested engine torque";
CM_ SG_ 145 DrvLnMinTrqMd "Drive line engine torque request: min.-mode";
CM_ SG_ 145 CRC_DTCM_A2 "CRC-checksum byte 1 to 7 according to SAE J1850";
CM_ SG_ 141 TCASERANGESTATUS "This signal is used for update the Transfer case Range status";
CM_ SG_ 141 TCASE_STAT "Transfer Case Status";
CM_ SG_ 120 BrakeBoostPressure "Pressure Information from Brake Booster Pedal Pressure Sensor";
CM_ SG_ 120 BrakePdlPosn "Brake pedal travel sensor 0-100% (0 = upstop)";
CM_ SG_ 120 BrakePedalPressure "Pressure Information from Brake Pedal Simulator Pressure Sensor";
CM_ SG_ 120 CRC_ESP_A10 "CRC-checksum byte 1 to 7 according to SAE J1850";
CM_ SG_ 120 MC_ESP_A10 "Message counter";
CM_ SG_ 119 StartRelayBCMFault "CBC starter relay fault detected";
CM_ SG_ 119 StartRelayBCMSts "CBC starter relay status; [1] = ON";
CM_ SG_ 119 RemStActv "Ignition run active for remote start (0=not active, 1=active)";
CM_ SG_ 119 CmdIgnStat "Commanded ignition switch status";
CM_ SG_ 117 CRC_10Eh "CRC-checksum byte 1 to 7 according to SAE J1850";
CM_ SG_ 117 MC_10Eh "Message counter";
CM_ SG_ 56 MotorB_Speed "Electric Motor Revolutions Per Minute, Initialization = 0xFFFE";
CM_ SG_ 56 CRC_HCP_A3 "CRC-checksum byte 1 to 6 according to SAE J1850";
CM_ SG_ 56 MC_HCP_A3 "Message counter";
CM_ SG_ 54 CRC_HCP_A2 "CRC-checksum byte 1 to 7 according to SAE J1850";
CM_ SG_ 54 MC_HCP_A2 "Message counter";
CM_ SG_ 54 SumTrqStatic_SEM "Static Sum Torque - Transmission Torque Request";
CM_ SG_ 54 SumTrqTgt_SEM "Target Torque  - Transmission Torque Request";
CM_ SG_ 40 CRC_HCP_A1 "CRC-checksum byte 1 to 7 according to SAE J1850";
CM_ SG_ 40 MC_HCP_A1 "Message counter";
CM_ SG_ 34 AccPos_PT "Accelerator Effective Position";
CM_ SG_ 34 MC_PT_SYSTEM_1 "Message counter";
CM_ SG_ 34 CRC_PT_SYSTEM_1 "CRC-checksum byte 1 to 7 according to SAE J1850";
CM_ SG_ 34 AccPosV_PT "Accelerator effective position validity";
CM_ SG_ 34 ActlAccelPdlPosn_PT "Accelerator Pedal Position (actual)";
CM_ SG_ 34 CRUISE_OVERRIDE_PT "Driver is over-riding cruise set speed";
CM_ SG_ 34 EngTrq_Enbl_Rq_ESC_PT "Allow ESC torque request";
CM_ SG_ 34 EngTrq_Enbl_Rq_AS_PT "Allow LCM torque requests";
CM_ SG_ 834 N_PDU_342 "N_PDU";
CM_ SG_ 819 ExhaustVlvStat "Exhaust Vlv Stat; [0] = Closed  [1] = Open";
CM_ SG_ 819 EngActiveTimer_OBD "Time since Engine start for OBD functionality";
CM_ SG_ 819 ExhaustSwStat "Exhaust switch status for button LED";
CM_ SG_ 38 ECM_LHOM_Trans_PHEV "Torque Accuracy Information for Transmission";
CM_ SG_ 38 ESS_ENG_ST_PHEV "ESS Engine State";
CM_ SG_ 38 ESS_ReqShiftPark_PHEV "ESS Request shift to Park.  1 = True, 0 = False";
CM_ SG_ 38 EngMaxRPM_PHEV "Engine maximum RPM";
CM_ SG_ 38 EngRPM_PHEV "Engine revolutions per minute";
CM_ SG_ 38 FullOFC_Actv_PHEV "Cylinder cut-out";
CM_ SG_ 38 ANL_LFT_PHEV "Starter motor running (Cranking)";
CM_ SG_ 38 CRC_ECM_A1_PHEV "CRC-checksum byte 1 to 7 according to SAE J1850";
CM_ SG_ 38 ECM_IMMO_STAT_CANC_PHEV "ECM immobilizer status";
CM_ SG_ 38 MC_ECM_A1_PHEV "Message counter";
CM_ SG_ 38 ThrmlMngActv_PHEV "Indicates ECM RPM Limitation Status, Active = 1";
CM_ SG_ 124 AccelPdlPosnSens_Flt_PHEV "Accelerator pedal position sensor fault";
CM_ SG_ 124 CRC_ECM_A2_PHEV "CRC-checksum byte 1 to 6 according to SAE J1850";
CM_ SG_ 124 CRUISE_OVERRIDE_PHEV "Driver is over-riding cruise set speed";
CM_ SG_ 124 ECM_LHOM_PHEV "Engine in limp home mode";
CM_ SG_ 124 ESS_RqShftPark_PHEV "ESS Request shift to Park.  1 = True, 0 = False";
CM_ SG_ 124 ECM_AllwEV_PHEV "ECM allow EV mode; 0 EV_not_allowed 1 EV_allowed";
CM_ SG_ 124 ECM_Comm_Fail_ePT "ECM_Comm_Fail_ePT";
CM_ SG_ 124 EngTrq_Enbl_Rq_AS_PHEV "Allow LCM torque requests";
CM_ SG_ 124 EngTrq_Enbl_Rq_ESC_PHEV "Allow ESC torque request";
CM_ SG_ 124 EngTrq_Enbl_Rq_TCM_PHEV "Allow TRANS torque request";
CM_ SG_ 124 LV12PwrFreeRq_PHEV "Level 1 or 2 power free request - engine controller has depowered the throttle body";
CM_ SG_ 124 MC_ECM_A2_PHEV "Message counter";
CM_ SG_ 124 RPMOverRev_PHEV "RPM Overrev condition has occurred";
CM_ SG_ 323 PCPM_PumpSpeedAct "Primary Coolant pump actual speed  in percentage";
CM_ SG_ 323 DrvAway_Inhibit "Drive Away Inhibit; True = [1]";
CM_ SG_ 323 DrvAway_Alert "Drive Away Alert; True = [1]";
CM_ SG_ 181 EngRPM_Tach "Engine revolutions per minute for indication";
CM_ SG_ 181 EngineStaticTorque "Engine Actual Steady State Torque";
CM_ SG_ 181 EngineStaticTorqueV "Engine Actual Steady State Torque Validity";
CM_ SG_ 37 ECM_LHOM_Trans "Torque Accuracy Information for Transmission";
CM_ SG_ 37 CRC_ECM_A1 "CRC-checksum byte 1 to 7 according to SAE J1850";
CM_ SG_ 37 MC_ECM_A1 "Message counter";
CM_ SG_ 37 ExpEngTrq "Expected Engine Torque based on target engine speed";
CM_ SG_ 37 EngTrqStatic "Static engine torque / Effective engine torque";
CM_ SG_ 37 EngRPM "Engine revolutions per minute";
CM_ SG_ 123 MC_ECM_A2 "Message counter";
CM_ SG_ 123 LV12PwrFreeRq "Level 1 or 2 power free request - engine controller has depowered the throttle body";
CM_ SG_ 123 RPMOverRev "RPM Overrev condition has occurred";
CM_ SG_ 123 CRUISE_OVERRIDE "Driver is over-riding cruise set speed";
CM_ SG_ 123 AccelPdlPosnSens_Flt "Accelerator pedal position sensor fault";
CM_ SG_ 123 ECM_LHOM "Engine in limp home mode";
CM_ SG_ 123 ESS_RqShftPark "ESS Request shift to Park.  1 = True, 0 = False";
CM_ SG_ 123 CRC_ECM_A2 "CRC-checksum byte 1 to 6 according to SAE J1850";
CM_ SG_ 123 EngTrq_DrvReqMod "Driver requested engine torque modifed";
CM_ SG_ 123 AccelPdlPosn "Throttle Pedal Position (Calculated)";
CM_ SG_ 123 EngTrq_Enbl_Rq_TCM "Allow TRANS torque request";
CM_ SG_ 123 EngTrq_Enbl_Rq_ESC "Allow ESC torque request";
CM_ SG_ 123 EngTrq_Enbl_Rq_AS "Allow LCM torque requests";
CM_ SG_ 123 EngTrqSel_D_TTC "Corrected (substitute) driver torque demand";
CM_ SG_ 53 EngRdyForESS "Engine is ready for ESS action (1 = ready)";
CM_ SG_ 53 EngStallSts "Engine stall status message";
CM_ SG_ 53 CRC_ECM_A3 "CRC-checksum byte 1 to 7 according to SAE J1850";
CM_ SG_ 53 MC_ECM_A3 "Message counter";
CM_ SG_ 53 ESS_ENG_ST "ESS Engine State";
CM_ SG_ 53 EngMaxRPM "Engine maximum RPM";
CM_ SG_ 53 ThrmlMngActv "Indicates ECM RPM Limitation Status, Active = 1";
CM_ SG_ 53 TRANS_CLU_SLIP_MODE "Clutch Slip Request Mode";
CM_ SG_ 53 EngTrqStatic_SEM "Static engine torque - trans trq request";
CM_ SG_ 53 EngTrqTgt_SEM "Target Torque  - trans trq. request";
CM_ SG_ 157 ECM_WARN_BTO "Status of the BTO failure is transmitted from ECM to cluster, appropriate EVIC message will be displayed by cluster";
CM_ SG_ 157 Analog_Clutch "Analog clutch pedal signal";
CM_ SG_ 157 CRC_ECM_A5 "CRC-checksum byte 1 to 7 according to SAE J1850";
CM_ SG_ 157 MC_ECM_A5 "Message counter";
CM_ SG_ 157 ActlAccelPdlPosn "Throttle Pedal Position (actual)";
BA_DEF_ SG_ "RID" STRING ;
BA_DEF_ SG_ "GenSigTimeout_TCM" INT 0 65535;
BA_DEF_ SG_ "GenSigTimeout_TBM" INT 0 65535;
BA_DEF_ SG_ "GenSigTimeout_SCCM" INT 0 65535;
BA_DEF_ SG_ "GenSigTimeout_RF_HUB" INT 0 65535;
BA_DEF_ SG_ "GenSigTimeout_PTS" INT 0 65535;
BA_DEF_ SG_ "GenSigTimeout_ORC" INT 0 65535;
BA_DEF_ SG_ "GenSigTimeout_OCM" INT 0 65535;
BA_DEF_ SG_ "GenSigTimeout_IC" INT 0 65535;
BA_DEF_ SG_ "GenSigTimeout_ETM" INT 0 65535;
BA_DEF_ SG_ "GenSigTimeout_ESM" INT 0 65535;
BA_DEF_ SG_ "GenSigTimeout_ESL" INT 0 65535;
BA_DEF_ SG_ "GenSigTimeout_ESC" INT 0 65535;
BA_DEF_ SG_ "GenSigTimeout_EHPS" INT 0 65535;
BA_DEF_ SG_ "GenSigTimeout_DTCM" INT 0 65535;
BA_DEF_ SG_ "GenSigTimeout_DPDM" INT 0 65535;
BA_DEF_ SG_ "GenSigTimeout_CBC" INT 0 65535;
BA_DEF_ SG_ "GenSigTimeout_ASBS" INT 0 65535;
BA_DEF_ SG_ "GenSigTimeout_AHLM" INT 0 65535;
BA_DEF_ SG_ "GenSigStartValue" HEX 0 2147483648;
BA_DEF_ SG_ "GenSigSNA" STRING ;
BA_DEF_ SG_ "GenSigSendType" ENUM "cyclicX","spontanX","cyclicIfActiveX","spontanWithDelay","cyclicAndSpontanX","cyclicAndSpontanWithDelay","spontanWithRepitition","cyclicIfActiveAndSpontanWD","cyclicIfActiveFast","cyclicWithRepeatOnDemand","none";
BA_DEF_ SG_ "GenSigCycleTimeActive" INT 0 65535;
BA_DEF_ SG_ "GenSigCycleTime" INT 0 65535;
BA_DEF_ SG_ "FlexKomSigStartValue" STRING ;
BA_DEF_ SG_ "FlexKomSigStartPos" INT 0 63;
BA_DEF_ SG_ "FlexKomSigName" STRING ;
BA_DEF_ SG_ "FlexKomSigLaenge" INT 0 64;
BA_DEF_ SG_ "FlexKomSID" INT 0 2147483647;
BA_DEF_ SG_ "FlexKomIsMotorola" ENUM "nein","ja";
BA_DEF_ SG_ "FlexKomComment" STRING ;
BA_DEF_ BO_ "TpTxIndex" INT 0 99;
BA_DEF_ BO_ "NWM-Botschaft" ENUM "nein","ja";
BA_DEF_ BO_ "GenMsgStartValue" STRING ;
BA_DEF_ BO_ "GenMsgStartDelayTime" INT 0 65535;
BA_DEF_ BO_ "GenMsgSendType" ENUM "cyclicX","spontanX","cyclicIfActiveX","spontanWithDelay","cyclicAndSpontanX","cyclicAndSpontanWithDelay","spontanWithRepitition","cyclicIfActiveAndSpontanWD","cyclicIfActiveFast","cyclicWithRepeatOnDemand","none";
BA_DEF_ BO_ "GenMsgNrOfRepetitions" INT 0 65535;
BA_DEF_ BO_ "GenMsgDelayTime" INT 0 65535;
BA_DEF_ BO_ "GenMsgCycleTimeActive" INT 0 65535;
BA_DEF_ BO_ "GenMsgCycleTime" INT 0 65535;
BA_DEF_ BO_ "DiagState" ENUM "nein","ja";
BA_DEF_ BO_ "DiagResponse" ENUM "nein","ja";
BA_DEF_ BO_ "DiagRequest" ENUM "nein","ja";
BA_DEF_ BO_ "CanMsgMinLen" INT 0 8;
BA_DEF_ BO_ "App-Botschaft" ENUM "nein","ja";
BA_DEF_DEF_ "RID" "";
BA_DEF_DEF_ "GenSigTimeout_TCM" 0;
BA_DEF_DEF_ "GenSigTimeout_TBM" 0;
BA_DEF_DEF_ "GenSigTimeout_SCCM" 0;
BA_DEF_DEF_ "GenSigTimeout_RF_HUB" 0;
BA_DEF_DEF_ "GenSigTimeout_PTS" 0;
BA_DEF_DEF_ "GenSigTimeout_ORC" 0;
BA_DEF_DEF_ "GenSigTimeout_OCM" 0;
BA_DEF_DEF_ "GenSigTimeout_IC" 0;
BA_DEF_DEF_ "GenSigTimeout_ETM" 0;
BA_DEF_DEF_ "GenSigTimeout_ESM" 0;
BA_DEF_DEF_ "GenSigTimeout_ESL" 0;
BA_DEF_DEF_ "GenSigTimeout_ESC" 0;
BA_DEF_DEF_ "GenSigTimeout_EHPS" 0;
BA_DEF_DEF_ "GenSigTimeout_DTCM" 0;
BA_DEF_DEF_ "GenSigTimeout_DPDM" 0;
BA_DEF_DEF_ "GenSigTimeout_CBC" 0;
BA_DEF_DEF_ "GenSigTimeout_ASBS" 0;
BA_DEF_DEF_ "GenSigTimeout_AHLM" 0;
BA_DEF_DEF_ "GenSigStartValue" 0;
BA_DEF_DEF_ "GenSigSNA" "";
BA_DEF_DEF_ "GenSigSendType" "cyclicX";
BA_DEF_DEF_ "GenSigCycleTimeActive" 0;
BA_DEF_DEF_ "GenSigCycleTime" 0;
BA_DEF_DEF_ "FlexKomSigStartValue" "";
BA_DEF_DEF_ "FlexKomSigStartPos" 0;
BA_DEF_DEF_ "FlexKomSigName" "";
BA_DEF_DEF_ "FlexKomSigLaenge" 0;
BA_DEF_DEF_ "FlexKomSID" 0;
BA_DEF_DEF_ "FlexKomIsMotorola" "nein";
BA_DEF_DEF_ "FlexKomComment" "";
BA_DEF_DEF_ "TpTxIndex" 0;
BA_DEF_DEF_ "NWM-Botschaft" "nein";
BA_DEF_DEF_ "GenMsgStartValue" "";
BA_DEF_DEF_ "GenMsgStartDelayTime" 0;
BA_DEF_DEF_ "GenMsgSendType" "cyclicX";
BA_DEF_DEF_ "GenMsgNrOfRepetitions" 0;
BA_DEF_DEF_ "GenMsgDelayTime" 0;
BA_DEF_DEF_ "GenMsgCycleTimeActive" 0;
BA_DEF_DEF_ "GenMsgCycleTime" 0;
BA_DEF_DEF_ "DiagState" "nein";
BA_DEF_DEF_ "DiagResponse" "nein";
BA_DEF_DEF_ "DiagRequest" "nein";
BA_DEF_DEF_ "CanMsgMinLen" 0;
BA_DEF_DEF_ "App-Botschaft" "nein";
BA_ "GenMsgNrOfRepetitions" BO_ 157 2;
BA_ "GenMsgDelayTime" BO_ 157 20;
BA_ "GenMsgCycleTime" BO_ 157 20;
BA_ "GenMsgStartValue" BO_ 157 "FFFFFFFF00000CFFh";
BA_ "GenMsgStartValue" BO_ 53 "5FFF1FFF00FF0FFFh";
BA_ "GenMsgNrOfRepetitions" BO_ 53 2;
BA_ "GenMsgDelayTime" BO_ 53 20;
BA_ "GenMsgCycleTime" BO_ 53 10;
BA_ "GenMsgNrOfRepetitions" BO_ 123 2;
BA_ "GenMsgDelayTime" BO_ 123 20;
BA_ "GenMsgCycleTime" BO_ 123 20;
BA_ "GenMsgStartValue" BO_ 123 "1FFFFF1FFF00FFh";
BA_ "GenMsgStartValue" BO_ 37 "FFFF1FFF1FFF00FFh";
BA_ "GenMsgNrOfRepetitions" BO_ 37 2;
BA_ "GenMsgDelayTime" BO_ 37 20;
BA_ "GenMsgCycleTime" BO_ 37 10;
BA_ "GenMsgSendType" BO_ 631 5;
BA_ "GenMsgNrOfRepetitions" BO_ 631 2;
BA_ "GenMsgDelayTime" BO_ 631 20;
BA_ "GenMsgCycleTime" BO_ 631 1000;
BA_ "GenMsgStartValue" BO_ 631 "0000000000000000h";
BA_ "GenMsgCycleTime" BO_ 145 20;
BA_ "GenMsgStartValue" BO_ 145 "01FF7F00000000FFh";
BA_ "GenMsgNrOfRepetitions" BO_ 145 2;
BA_ "GenMsgDelayTime" BO_ 145 20;
BA_ "GenMsgStartValue" BO_ 141 "CEC0FFFFFFFFFFFFh";
BA_ "GenMsgNrOfRepetitions" BO_ 141 2;
BA_ "GenMsgDelayTime" BO_ 141 20;
BA_ "GenMsgCycleTime" BO_ 141 20;
BA_ "GenMsgStartValue" BO_ 167 "04000000C00000FFh";
BA_ "GenMsgNrOfRepetitions" BO_ 167 2;
BA_ "GenMsgDelayTime" BO_ 167 20;
BA_ "GenMsgCycleTime" BO_ 167 20;
BA_ "GenMsgStartValue" BO_ 462 "FF0000FFh";
BA_ "GenMsgNrOfRepetitions" BO_ 462 2;
BA_ "GenMsgDelayTime" BO_ 462 20;
BA_ "GenMsgCycleTime" BO_ 462 50;
BA_ "GenMsgDelayTime" BO_ 967 20;
BA_ "GenMsgCycleTime" BO_ 967 200;
BA_ "GenMsgStartValue" BO_ 967 "000000FFh";
BA_ "GenMsgSendType" BO_ 967 5;
BA_ "GenMsgNrOfRepetitions" BO_ 967 2;
BA_ "GenMsgStartValue" BO_ 163 "000000FF000000FFh";
BA_ "GenMsgNrOfRepetitions" BO_ 163 2;
BA_ "GenMsgDelayTime" BO_ 163 20;
BA_ "GenMsgCycleTime" BO_ 163 20;
BA_ "GenMsgStartValue" BO_ 232 "00FFFF00000000FFh";
BA_ "GenMsgNrOfRepetitions" BO_ 232 2;
BA_ "GenMsgDelayTime" BO_ 232 20;
BA_ "GenMsgCycleTime" BO_ 232 60;
BA_ "GenMsgStartValue" BO_ 153 "1FFF0CCB000000FFh";
BA_ "GenMsgNrOfRepetitions" BO_ 153 2;
BA_ "GenMsgDelayTime" BO_ 153 20;
BA_ "GenMsgCycleTime" BO_ 153 20;
BA_ "GenMsgStartValue" BO_ 319 "5A5AFFFF01FF0000h";
BA_ "GenMsgStartDelayTime" BO_ 319 30;
BA_ "GenMsgNrOfRepetitions" BO_ 319 2;
BA_ "GenMsgDelayTime" BO_ 319 20;
BA_ "GenMsgCycleTime" BO_ 319 100;
BA_ "GenMsgSendType" BO_ 607 5;
BA_ "GenMsgNrOfRepetitions" BO_ 607 2;
BA_ "GenMsgDelayTime" BO_ 607 20;
BA_ "GenMsgCycleTime" BO_ 607 1000;
BA_ "GenMsgStartValue" BO_ 607 "0000000000000FFFh";
BA_ "GenMsgStartDelayTime" BO_ 607 40;
BA_ "GenMsgDelayTime" BO_ 155 20;
BA_ "GenMsgCycleTime" BO_ 155 20;
BA_ "GenMsgStartValue" BO_ 155 "3FFF0C00000000FFh";
BA_ "GenMsgStartDelayTime" BO_ 155 10;
BA_ "GenMsgNrOfRepetitions" BO_ 155 2;
BA_ "GenMsgDelayTime" BO_ 299 20;
BA_ "GenMsgCycleTime" BO_ 299 100;
BA_ "GenMsgStartValue" BO_ 299 "FFFFFFFFFFFFFFFFh";
BA_ "GenMsgNrOfRepetitions" BO_ 299 2;
BA_ "GenMsgStartValue" BO_ 119 "0000h";
BA_ "GenMsgNrOfRepetitions" BO_ 119 2;
BA_ "GenMsgDelayTime" BO_ 119 20;
BA_ "GenMsgCycleTime" BO_ 119 20;
BA_ "GenMsgSendType" BO_ 657 5;
BA_ "GenMsgNrOfRepetitions" BO_ 657 2;
BA_ "GenMsgDelayTime" BO_ 657 20;
BA_ "GenMsgCycleTime" BO_ 657 1000;
BA_ "GenMsgStartValue" BO_ 657 "6000003FFFFC0000h";
BA_ "GenMsgStartDelayTime" BO_ 657 20;
BA_ "GenMsgSendType" BO_ 906 5;
BA_ "GenMsgNrOfRepetitions" BO_ 906 2;
BA_ "GenMsgDelayTime" BO_ 906 20;
BA_ "GenMsgCycleTime" BO_ 906 2000;
BA_ "GenMsgStartValue" BO_ 906 "0300000000000000h";
BA_ "GenMsgStartValue" BO_ 738 "00000000000000FFh";
BA_ "GenMsgNrOfRepetitions" BO_ 738 2;
BA_ "GenMsgDelayTime" BO_ 738 20;
BA_ "GenMsgCycleTime" BO_ 738 100;
BA_ "GenMsgSendType" BO_ 818 5;
BA_ "GenMsgNrOfRepetitions" BO_ 818 2;
BA_ "GenMsgDelayTime" BO_ 818 20;
BA_ "GenMsgCycleTime" BO_ 818 1000;
BA_ "GenMsgStartValue" BO_ 818 "03FF03FF00000000h";
BA_ "GenMsgDelayTime" BO_ 181 20;
BA_ "GenMsgCycleTime" BO_ 181 20;
BA_ "GenMsgStartValue" BO_ 181 "0000FFFF03AA00FFh";
BA_ "GenMsgNrOfRepetitions" BO_ 181 2;
BA_ "GenMsgNrOfRepetitions" BO_ 833 2;
BA_ "GenMsgDelayTime" BO_ 833 20;
BA_ "GenMsgCycleTime" BO_ 833 500;
BA_ "GenMsgStartValue" BO_ 833 "0019001900000000h";
BA_ "GenMsgCycleTime" BO_ 179 20;
BA_ "GenMsgStartValue" BO_ 179 "0000FFFF000000FFh";
BA_ "GenMsgNrOfRepetitions" BO_ 179 2;
BA_ "GenMsgDelayTime" BO_ 179 20;
BA_ "GenMsgSendType" BO_ 298 5;
BA_ "GenMsgNrOfRepetitions" BO_ 298 2;
BA_ "GenMsgDelayTime" BO_ 298 20;
BA_ "GenMsgCycleTime" BO_ 298 100;
BA_ "GenMsgStartValue" BO_ 298 "01FF0000000000FFh";
BA_ "GenMsgStartValue" BO_ 307 "FF030CFFh";
BA_ "GenMsgStartDelayTime" BO_ 307 10;
BA_ "GenMsgNrOfRepetitions" BO_ 307 2;
BA_ "GenMsgDelayTime" BO_ 307 20;
BA_ "GenMsgCycleTime" BO_ 307 100;
BA_ "GenMsgStartValue" BO_ 323 "7F0FFF0000000000h";
BA_ "GenMsgNrOfRepetitions" BO_ 323 2;
BA_ "GenMsgDelayTime" BO_ 323 20;
BA_ "GenMsgCycleTime" BO_ 323 100;
BA_ "GenMsgSendType" BO_ 560 5;
BA_ "GenMsgNrOfRepetitions" BO_ 560 2;
BA_ "GenMsgDelayTime" BO_ 560 20;
BA_ "GenMsgCycleTime" BO_ 560 500;
BA_ "GenMsgStartValue" BO_ 560 "0800000000000000h";
BA_ "GenMsgStartValue" BO_ 56 "1FFF1FFFFFFE00FFh";
BA_ "GenMsgNrOfRepetitions" BO_ 56 2;
BA_ "GenMsgDelayTime" BO_ 56 20;
BA_ "GenMsgCycleTime" BO_ 56 10;
BA_ "GenMsgStartValue" BO_ 54 "1FFF1FFF1FFF00FFh";
BA_ "GenMsgNrOfRepetitions" BO_ 54 2;
BA_ "GenMsgDelayTime" BO_ 54 20;
BA_ "GenMsgCycleTime" BO_ 54 10;
BA_ "GenMsgStartValue" BO_ 40 "1FFF1FFF1FFF00FFh";
BA_ "GenMsgNrOfRepetitions" BO_ 40 2;
BA_ "GenMsgDelayTime" BO_ 40 20;
BA_ "GenMsgCycleTime" BO_ 40 10;
BA_ "GenMsgStartValue" BO_ 120 "00000000000000FFh";
BA_ "GenMsgNrOfRepetitions" BO_ 120 2;
BA_ "GenMsgDelayTime" BO_ 120 20;
BA_ "GenMsgCycleTime" BO_ 120 20;
BA_ "GenMsgStartValue" BO_ 124 "FF0000001FFF00FFh";
BA_ "GenMsgNrOfRepetitions" BO_ 124 2;
BA_ "GenMsgDelayTime" BO_ 124 20;
BA_ "GenMsgCycleTime" BO_ 124 20;
BA_ "GenMsgDelayTime" BO_ 38 20;
BA_ "GenMsgCycleTime" BO_ 38 10;
BA_ "GenMsgStartValue" BO_ 38 "FFFFFF00201E00FFh";
BA_ "GenMsgNrOfRepetitions" BO_ 38 2;
BA_ "GenMsgNrOfRepetitions" BO_ 117 2;
BA_ "GenMsgDelayTime" BO_ 117 20;
BA_ "GenMsgCycleTime" BO_ 117 20;
BA_ "GenMsgStartValue" BO_ 117 "00000000000000FFh";
BA_ "GenMsgSendType" BO_ 819 5;
BA_ "GenMsgNrOfRepetitions" BO_ 819 2;
BA_ "GenMsgDelayTime" BO_ 819 20;
BA_ "GenMsgCycleTime" BO_ 819 1000;
BA_ "GenMsgStartValue" BO_ 819 "00000000000000FFh";
BA_ "GenMsgStartValue" BO_ 834 "0000000000000000h";
BA_ "GenMsgSendType" BO_ 834 1;
BA_ "GenMsgNrOfRepetitions" BO_ 834 2;
BA_ "GenMsgDelayTime" BO_ 834 20;
BA_ "GenMsgDelayTime" BO_ 835 20;
BA_ "GenMsgStartValue" BO_ 835 "0000000000000000h";
BA_ "GenMsgSendType" BO_ 835 1;
BA_ "GenMsgNrOfRepetitions" BO_ 835 2;
BA_ "GenMsgStartValue" BO_ 34 "00000001F40000FFh";
BA_ "GenMsgNrOfRepetitions" BO_ 34 2;
BA_ "GenMsgDelayTime" BO_ 34 20;
BA_ "GenMsgCycleTime" BO_ 34 10;
BA_ "FlexKomSigName" SG_ 818 A2D_DRV_TEMP_DR_POS "A2D_DRV_TEMP_DR_POS";
BA_ "FlexKomSigLaenge" SG_ 818 A2D_DRV_TEMP_DR_POS 16;
BA_ "FlexKomSID" SG_ 818 A2D_DRV_TEMP_DR_POS 2695;
BA_ "GenSigSNA" SG_ 124 EngTrq_Enbl_Rq_TCM_PHEV "0h";
BA_ "GenSigSNA" SG_ 319 VoltageMax "0h";
BA_ "GenSigCycleTime" SG_ 319 VoltageMax 100;
BA_ "FlexKomSigStartValue" SG_ 319 VoltageMax "0000h";
BA_ "FlexKomSigStartPos" SG_ 319 VoltageMax 55;
BA_ "FlexKomSigName" SG_ 319 VoltageMax "VoltageRange";
BA_ "FlexKomSigLaenge" SG_ 319 VoltageMax 16;
BA_ "FlexKomSID" SG_ 319 VoltageMax 2647;
BA_ "FlexKomIsMotorola" SG_ 319 VoltageMax 1;
BA_ "FlexKomComment" SG_ 319 VoltageMax "Voltage range packet related to SAM strategy";
BA_ "FlexKomIsMotorola" SG_ 818 A2D_DRV_TEMP_DR_POS 1;
BA_ "FlexKomComment" SG_ 818 A2D_DRV_TEMP_DR_POS "Transmit raw A/D driver temp door position to ECM ";
BA_ "RID" SG_ 319 IBS3_Vbatt "5106";
BA_ "GenSigStartValue" SG_ 319 IBS3_Vbatt 511;
BA_ "GenSigSNA" SG_ 319 IBS3_Vbatt "1FFh";
BA_ "GenSigCycleTime" SG_ 319 IBS3_Vbatt 100;
BA_ "FlexKomSigStartValue" SG_ 319 IBS3_Vbatt "01FFh";
BA_ "FlexKomSigStartPos" SG_ 319 IBS3_Vbatt 39;
BA_ "FlexKomSigName" SG_ 319 IBS3_Vbatt "IBS3_Vbatt";
BA_ "FlexKomSigLaenge" SG_ 319 IBS3_Vbatt 16;
BA_ "FlexKomSID" SG_ 319 IBS3_Vbatt 2651;
BA_ "FlexKomIsMotorola" SG_ 319 IBS3_Vbatt 1;
BA_ "FlexKomComment" SG_ 319 IBS3_Vbatt "Battery voltage measured at the terminals";
BA_ "GenSigSNA" SG_ 319 VoltageMin "0h";
BA_ "GenSigCycleTime" SG_ 319 VoltageMin 100;
BA_ "FlexKomSigStartValue" SG_ 319 VoltageMin "0000h";
BA_ "FlexKomSigStartPos" SG_ 319 VoltageMin 55;
BA_ "FlexKomSigName" SG_ 319 VoltageMin "VoltageRange";
BA_ "FlexKomSigLaenge" SG_ 319 VoltageMin 16;
BA_ "FlexKomSID" SG_ 319 VoltageMin 2647;
BA_ "FlexKomIsMotorola" SG_ 319 VoltageMin 1;
BA_ "FlexKomComment" SG_ 319 VoltageMin "Voltage range packet related to SAM strategy";
BA_ "GenSigTimeout_TBM" SG_ 607 EngineOffTimer 10500;
BA_ "GenSigStartValue" SG_ 607 EngineOffTimer 4095;
BA_ "GenSigSNA" SG_ 607 EngineOffTimer "FFFh";
BA_ "GenSigCycleTime" SG_ 607 EngineOffTimer 1000;
BA_ "FlexKomSigStartValue" SG_ 607 EngineOffTimer "0FFFh";
BA_ "FlexKomSigStartPos" SG_ 607 EngineOffTimer 55;
BA_ "FlexKomSigName" SG_ 607 EngineOffTimer "EngineOffTimer";
BA_ "FlexKomSigLaenge" SG_ 607 EngineOffTimer 16;
BA_ "FlexKomSID" SG_ 607 EngineOffTimer 1906;
BA_ "FlexKomIsMotorola" SG_ 607 EngineOffTimer 1;
BA_ "FlexKomComment" SG_ 607 EngineOffTimer "Engine off timer - engine off ignition NOT lock.";
BA_ "FlexKomIsMotorola" SG_ 34 MC_PT_SYSTEM_1 1;
BA_ "FlexKomComment" SG_ 34 MC_PT_SYSTEM_1 "PT_SYSTEM_1_PKT Packet";
BA_ "GenSigSNA" SG_ 34 EngTrq_Enbl_Rq_ESC_PT "0h";
BA_ "GenSigCycleTime" SG_ 34 EngTrq_Enbl_Rq_ESC_PT 10;
BA_ "FlexKomSigStartValue" SG_ 34 EngTrq_Enbl_Rq_ESC_PT "FFFFFF01F40000FFh";
BA_ "FlexKomSigStartPos" SG_ 34 EngTrq_Enbl_Rq_ESC_PT 7;
BA_ "FlexKomSigName" SG_ 34 EngTrq_Enbl_Rq_ESC_PT "PT_SYSTEM_1_PKT";
BA_ "FlexKomSigLaenge" SG_ 34 EngTrq_Enbl_Rq_ESC_PT 64;
BA_ "FlexKomSID" SG_ 34 EngTrq_Enbl_Rq_ESC_PT 3370;
BA_ "FlexKomIsMotorola" SG_ 34 EngTrq_Enbl_Rq_ESC_PT 1;
BA_ "FlexKomComment" SG_ 34 EngTrq_Enbl_Rq_ESC_PT "PT_SYSTEM_1_PKT Packet";
BA_ "GenSigSNA" SG_ 120 MC_ESP_A10 "0h";
BA_ "GenSigCycleTime" SG_ 120 MC_ESP_A10 20;
BA_ "FlexKomSigStartValue" SG_ 120 MC_ESP_A10 "00000000000000FFh";
BA_ "FlexKomSigStartPos" SG_ 120 MC_ESP_A10 7;
BA_ "FlexKomSigName" SG_ 120 MC_ESP_A10 "ESP_A10_Pkt";
BA_ "FlexKomSigLaenge" SG_ 120 MC_ESP_A10 64;
BA_ "FlexKomSID" SG_ 120 MC_ESP_A10 2964;
BA_ "FlexKomIsMotorola" SG_ 120 MC_ESP_A10 1;
BA_ "FlexKomComment" SG_ 120 MC_ESP_A10 "ESP_A10_Pkt";
BA_ "GenSigSNA" SG_ 120 BrakePdlPosn "FFh";
BA_ "GenSigCycleTime" SG_ 120 BrakePdlPosn 20;
BA_ "FlexKomSigStartValue" SG_ 120 BrakePdlPosn "00000000000000FFh";
BA_ "FlexKomSigStartPos" SG_ 120 BrakePdlPosn 7;
BA_ "FlexKomSigName" SG_ 120 BrakePdlPosn "ESP_A10_Pkt";
BA_ "FlexKomSigLaenge" SG_ 120 BrakePdlPosn 64;
BA_ "FlexKomSID" SG_ 120 BrakePdlPosn 2964;
BA_ "FlexKomIsMotorola" SG_ 120 BrakePdlPosn 1;
BA_ "FlexKomComment" SG_ 120 BrakePdlPosn "ESP_A10_Pkt";
BA_ "GenSigSNA" SG_ 124 ECM_Comm_Fail_ePT "0h";
BA_ "GenSigCycleTime" SG_ 124 ECM_Comm_Fail_ePT 20;
BA_ "FlexKomSigStartValue" SG_ 124 ECM_Comm_Fail_ePT "FF0000001FFF00FFh";
BA_ "FlexKomSigStartPos" SG_ 124 ECM_Comm_Fail_ePT 7;
BA_ "FlexKomSigName" SG_ 124 ECM_Comm_Fail_ePT "ECM_A2_PHEV_PKT";
BA_ "FlexKomSigLaenge" SG_ 124 ECM_Comm_Fail_ePT 64;
BA_ "FlexKomSID" SG_ 124 ECM_Comm_Fail_ePT 2991;
BA_ "FlexKomIsMotorola" SG_ 124 ECM_Comm_Fail_ePT 1;
BA_ "FlexKomComment" SG_ 124 ECM_Comm_Fail_ePT "ECM_A2_PHEV_PKT";
BA_ "GenSigSNA" SG_ 124 MC_ECM_A2_PHEV "0h";
BA_ "GenSigCycleTime" SG_ 124 MC_ECM_A2_PHEV 20;
BA_ "FlexKomSigStartValue" SG_ 124 MC_ECM_A2_PHEV "FF0000001FFF00FFh";
BA_ "FlexKomSigStartPos" SG_ 124 MC_ECM_A2_PHEV 7;
BA_ "FlexKomSigName" SG_ 124 MC_ECM_A2_PHEV "ECM_A2_PHEV_PKT";
BA_ "FlexKomSigLaenge" SG_ 124 MC_ECM_A2_PHEV 64;
BA_ "FlexKomSID" SG_ 124 MC_ECM_A2_PHEV 2991;
BA_ "FlexKomIsMotorola" SG_ 124 MC_ECM_A2_PHEV 1;
BA_ "FlexKomComment" SG_ 124 MC_ECM_A2_PHEV "ECM_A2_PHEV_PKT";
BA_ "RID" SG_ 124 AccelPdlPosnSens_Flt_PHEV "6416";
BA_ "GenSigTimeout_DTCM" SG_ 124 AccelPdlPosnSens_Flt_PHEV 210;
BA_ "GenSigSNA" SG_ 124 AccelPdlPosnSens_Flt_PHEV "0h";
BA_ "GenSigCycleTime" SG_ 124 AccelPdlPosnSens_Flt_PHEV 20;
BA_ "FlexKomSigStartValue" SG_ 124 AccelPdlPosnSens_Flt_PHEV "FF0000001FFF00FFh";
BA_ "FlexKomSigStartPos" SG_ 124 AccelPdlPosnSens_Flt_PHEV 7;
BA_ "FlexKomSigName" SG_ 124 AccelPdlPosnSens_Flt_PHEV "ECM_A2_PHEV_PKT";
BA_ "FlexKomSigLaenge" SG_ 124 AccelPdlPosnSens_Flt_PHEV 64;
BA_ "FlexKomSID" SG_ 124 AccelPdlPosnSens_Flt_PHEV 2991;
BA_ "FlexKomIsMotorola" SG_ 124 AccelPdlPosnSens_Flt_PHEV 1;
BA_ "FlexKomComment" SG_ 124 AccelPdlPosnSens_Flt_PHEV "ECM_A2_PHEV_PKT";
BA_ "GenSigSNA" SG_ 38 ECM_IMMO_STAT_CANC_PHEV "3h";
BA_ "GenSigCycleTime" SG_ 38 ECM_IMMO_STAT_CANC_PHEV 10;
BA_ "FlexKomSigStartValue" SG_ 38 ECM_IMMO_STAT_CANC_PHEV "FFFFFF00201E00FFh";
BA_ "FlexKomSigStartPos" SG_ 38 ECM_IMMO_STAT_CANC_PHEV 7;
BA_ "FlexKomSigName" SG_ 38 ECM_IMMO_STAT_CANC_PHEV "ECM_A1_PHEV_PKT";
BA_ "FlexKomSigLaenge" SG_ 38 ECM_IMMO_STAT_CANC_PHEV 64;
BA_ "FlexKomSID" SG_ 38 ECM_IMMO_STAT_CANC_PHEV 2992;
BA_ "FlexKomIsMotorola" SG_ 38 ECM_IMMO_STAT_CANC_PHEV 1;
BA_ "FlexKomComment" SG_ 38 ECM_IMMO_STAT_CANC_PHEV "ECM_A1_PHEV_PKT";
BA_ "RID" SG_ 38 ThrmlMngActv_PHEV "1613";
BA_ "GenSigSNA" SG_ 38 ThrmlMngActv_PHEV "0h";
BA_ "GenSigCycleTime" SG_ 38 ThrmlMngActv_PHEV 10;
BA_ "FlexKomSigStartValue" SG_ 38 ThrmlMngActv_PHEV "FFFFFF00201E00FFh";
BA_ "FlexKomSigStartPos" SG_ 38 ThrmlMngActv_PHEV 7;
BA_ "FlexKomSigName" SG_ 38 ThrmlMngActv_PHEV "ECM_A1_PHEV_PKT";
BA_ "FlexKomSigLaenge" SG_ 38 ThrmlMngActv_PHEV 64;
BA_ "FlexKomSID" SG_ 38 ThrmlMngActv_PHEV 2992;
BA_ "FlexKomIsMotorola" SG_ 38 ThrmlMngActv_PHEV 1;
BA_ "FlexKomComment" SG_ 38 ThrmlMngActv_PHEV "ECM_A1_PHEV_PKT";
BA_ "RID" SG_ 38 EngRPM_PHEV "2185";
BA_ "GenSigTimeout_TCM" SG_ 38 EngRPM_PHEV 105;
BA_ "GenSigTimeout_ORC" SG_ 38 EngRPM_PHEV 35;
BA_ "GenSigTimeout_IC" SG_ 38 EngRPM_PHEV 105;
BA_ "GenSigTimeout_ESM" SG_ 38 EngRPM_PHEV 105;
BA_ "GenSigTimeout_EHPS" SG_ 38 EngRPM_PHEV 105;
BA_ "GenSigTimeout_DTCM" SG_ 38 EngRPM_PHEV 105;
BA_ "GenSigTimeout_CBC" SG_ 38 EngRPM_PHEV 105;
BA_ "GenSigStartValue" SG_ 38 EngRPM_PHEV 65535;
BA_ "GenSigSNA" SG_ 38 EngRPM_PHEV "FFFFh";
BA_ "GenSigCycleTime" SG_ 38 EngRPM_PHEV 10;
BA_ "FlexKomSigStartValue" SG_ 38 EngRPM_PHEV "FFFFFF00201E00FFh";
BA_ "FlexKomSigStartPos" SG_ 38 EngRPM_PHEV 7;
BA_ "FlexKomSigName" SG_ 38 EngRPM_PHEV "ECM_A1_PHEV_PKT";
BA_ "FlexKomSigLaenge" SG_ 38 EngRPM_PHEV 64;
BA_ "FlexKomSID" SG_ 38 EngRPM_PHEV 2992;
BA_ "FlexKomIsMotorola" SG_ 38 EngRPM_PHEV 1;
BA_ "FlexKomComment" SG_ 38 EngRPM_PHEV "ECM_A1_PHEV_PKT";
BA_ "FlexKomSigName" SG_ 298 CRC_12Ah "HCP_100";
BA_ "FlexKomSigLaenge" SG_ 298 CRC_12Ah 64;
BA_ "FlexKomSID" SG_ 298 CRC_12Ah 2820;
BA_ "FlexKomIsMotorola" SG_ 298 CRC_12Ah 1;
BA_ "FlexKomComment" SG_ 298 CRC_12Ah "HCP_100 message packet";
BA_ "GenSigSNA" SG_ 323 PCPM_PumpSpeedAct "7Fh";
BA_ "GenSigCycleTime" SG_ 323 PCPM_PumpSpeedAct 100;
BA_ "FlexKomSigStartValue" SG_ 323 PCPM_PumpSpeedAct "00h";
BA_ "FlexKomSigStartPos" SG_ 323 PCPM_PumpSpeedAct 54;
BA_ "FlexKomSigName" SG_ 323 PCPM_PumpSpeedAct "PCPM_PumpSpeedAct_PKT";
BA_ "FlexKomSigLaenge" SG_ 323 PCPM_PumpSpeedAct 7;
BA_ "FlexKomSID" SG_ 323 PCPM_PumpSpeedAct 3468;
BA_ "FlexKomIsMotorola" SG_ 323 PCPM_PumpSpeedAct 1;
BA_ "FlexKomComment" SG_ 323 PCPM_PumpSpeedAct "PCPM_PumpSpeedAct_PKT";
BA_ "RID" SG_ 560 AC_RQ "1237";
BA_ "GenSigSNA" SG_ 560 AC_RQ "0h";
BA_ "GenSigSendType" SG_ 560 AC_RQ 5;
BA_ "GenSigCycleTime" SG_ 560 AC_RQ 500;
BA_ "FlexKomSigStartValue" SG_ 560 AC_RQ "00h";
BA_ "FlexKomSigName" SG_ 560 AC_RQ "AC_RQ";
BA_ "FlexKomSigLaenge" SG_ 560 AC_RQ 1;
BA_ "FlexKomSID" SG_ 560 AC_RQ 27;
BA_ "FlexKomIsMotorola" SG_ 560 AC_RQ 1;
BA_ "FlexKomComment" SG_ 560 AC_RQ "A/C clutch request; [1] = A/C Clutch requested; 0 ";
BA_ "RID" SG_ 560 AC_PT_Demand "1916";
BA_ "GenSigSNA" SG_ 560 AC_PT_Demand "0h";
BA_ "GenSigSendType" SG_ 560 AC_PT_Demand 5;
BA_ "GenSigCycleTime" SG_ 560 AC_PT_Demand 500;
BA_ "FlexKomSigStartValue" SG_ 560 AC_PT_Demand "00h";
BA_ "FlexKomSigStartPos" SG_ 560 AC_PT_Demand 5;
BA_ "FlexKomSigName" SG_ 560 AC_PT_Demand "AC_PT_Demand";
BA_ "FlexKomSigLaenge" SG_ 560 AC_PT_Demand 1;
BA_ "FlexKomSID" SG_ 560 AC_PT_Demand 1945;
BA_ "FlexKomIsMotorola" SG_ 560 AC_PT_Demand 1;
BA_ "FlexKomComment" SG_ 560 AC_PT_Demand "Maximum A/C demand to powertrain";
BA_ "RID" SG_ 560 SpSt_DsblHVAC "1127";
BA_ "GenSigSNA" SG_ 560 SpSt_DsblHVAC "7h";
BA_ "GenSigSendType" SG_ 560 SpSt_DsblHVAC 5;
BA_ "GenSigCycleTime" SG_ 560 SpSt_DsblHVAC 500;
BA_ "FlexKomSigStartValue" SG_ 560 SpSt_DsblHVAC "00h";
BA_ "FlexKomSigStartPos" SG_ 560 SpSt_DsblHVAC 26;
BA_ "FlexKomSigName" SG_ 560 SpSt_DsblHVAC "SpSt_DsblHVAC";
BA_ "FlexKomSigLaenge" SG_ 560 SpSt_DsblHVAC 3;
BA_ "FlexKomSID" SG_ 560 SpSt_DsblHVAC 1555;
BA_ "FlexKomIsMotorola" SG_ 560 SpSt_DsblHVAC 1;
BA_ "FlexKomComment" SG_ 560 SpSt_DsblHVAC "Stop start disable from HVAC";
BA_ "GenSigTimeout_IC" SG_ 157 ECM_WARN_BTO 210;
BA_ "GenSigSNA" SG_ 157 ECM_WARN_BTO "0h";
BA_ "GenSigCycleTime" SG_ 157 ECM_WARN_BTO 20;
BA_ "FlexKomSigStartValue" SG_ 157 ECM_WARN_BTO "FFFFFFFF00000CFFh";
BA_ "FlexKomSigStartPos" SG_ 157 ECM_WARN_BTO 7;
BA_ "FlexKomSigName" SG_ 157 ECM_WARN_BTO "ECM_A5_PKT";
BA_ "FlexKomSigLaenge" SG_ 157 ECM_WARN_BTO 64;
BA_ "FlexKomSID" SG_ 157 ECM_WARN_BTO 1821;
BA_ "FlexKomIsMotorola" SG_ 157 ECM_WARN_BTO 1;
BA_ "FlexKomComment" SG_ 157 ECM_WARN_BTO "ECM_A5 Packet";
BA_ "GenSigSNA" SG_ 117 MC_10Eh "0h";
BA_ "GenSigCycleTime" SG_ 117 MC_10Eh 20;
BA_ "FlexKomSigStartValue" SG_ 117 MC_10Eh "00000000000000FFh";
BA_ "FlexKomSigStartPos" SG_ 117 MC_10Eh 7;
BA_ "FlexKomSigName" SG_ 117 MC_10Eh "ESP_A9_Pkt";
BA_ "FlexKomSigStartPos" SG_ 53 EngStallSts 7;
BA_ "FlexKomSigName" SG_ 53 EngStallSts "ECM_A3_PKT";
BA_ "FlexKomSigLaenge" SG_ 53 EngStallSts 64;
BA_ "FlexKomSID" SG_ 53 EngStallSts 1369;
BA_ "FlexKomIsMotorola" SG_ 53 EngStallSts 1;
BA_ "FlexKomComment" SG_ 53 EngStallSts "ECM_A3 message packet";
BA_ "GenSigTimeout_TCM" SG_ 123 EngTrqSel_D_TTC 210;
BA_ "GenSigTimeout_DTCM" SG_ 123 EngTrqSel_D_TTC 210;
BA_ "GenSigStartValue" SG_ 123 EngTrqSel_D_TTC 8191;
BA_ "GenSigSNA" SG_ 123 EngTrqSel_D_TTC "1FFFh";
BA_ "GenSigCycleTime" SG_ 123 EngTrqSel_D_TTC 20;
BA_ "FlexKomSigStartValue" SG_ 123 EngTrqSel_D_TTC "1FFFFF1FFF00FFh";
BA_ "FlexKomSigStartPos" SG_ 123 EngTrqSel_D_TTC 7;
BA_ "FlexKomSigName" SG_ 123 EngTrqSel_D_TTC "ECM_A2_PKT";
BA_ "FlexKomSigLaenge" SG_ 123 EngTrqSel_D_TTC 56;
BA_ "FlexKomSID" SG_ 123 EngTrqSel_D_TTC 455;
BA_ "FlexKomIsMotorola" SG_ 123 EngTrqSel_D_TTC 1;
BA_ "FlexKomComment" SG_ 123 EngTrqSel_D_TTC "ECM_A2 Packet";
BA_ "GenSigTimeout_TCM" SG_ 123 EngTrq_Enbl_Rq_TCM 210;
BA_ "GenSigSNA" SG_ 123 EngTrq_Enbl_Rq_TCM "0h";
BA_ "GenSigCycleTime" SG_ 123 EngTrq_Enbl_Rq_TCM 20;
BA_ "FlexKomSigStartValue" SG_ 123 EngTrq_Enbl_Rq_TCM "1FFFFF1FFF00FFh";
BA_ "FlexKomSigStartPos" SG_ 123 EngTrq_Enbl_Rq_TCM 7;
BA_ "FlexKomSigName" SG_ 123 EngTrq_Enbl_Rq_TCM "ECM_A2_PKT";
BA_ "FlexKomSigLaenge" SG_ 123 EngTrq_Enbl_Rq_TCM 56;
BA_ "FlexKomSID" SG_ 123 EngTrq_Enbl_Rq_TCM 455;
BA_ "FlexKomIsMotorola" SG_ 123 EngTrq_Enbl_Rq_TCM 1;
BA_ "FlexKomComment" SG_ 123 EngTrq_Enbl_Rq_TCM "ECM_A2 Packet";
BA_ "GenSigSNA" SG_ 123 ESS_RqShftPark "0h";
BA_ "GenSigCycleTime" SG_ 123 ESS_RqShftPark 20;
BA_ "FlexKomSigStartValue" SG_ 123 ESS_RqShftPark "1FFFFF1FFF00FFh";
BA_ "FlexKomSigStartPos" SG_ 123 ESS_RqShftPark 7;
BA_ "FlexKomSigName" SG_ 123 ESS_RqShftPark "ECM_A2_PKT";
BA_ "FlexKomSigLaenge" SG_ 123 ESS_RqShftPark 56;
BA_ "FlexKomSID" SG_ 123 ESS_RqShftPark 455;
BA_ "FlexKomIsMotorola" SG_ 123 ESS_RqShftPark 1;
BA_ "FlexKomComment" SG_ 123 ESS_RqShftPark "ECM_A2 Packet";
BA_ "RID" SG_ 123 AccelPdlPosnSens_Flt "5031";
BA_ "GenSigTimeout_DTCM" SG_ 123 AccelPdlPosnSens_Flt 210;
BA_ "GenSigSNA" SG_ 123 AccelPdlPosnSens_Flt "0h";
BA_ "GenSigCycleTime" SG_ 123 AccelPdlPosnSens_Flt 20;
BA_ "FlexKomSigStartValue" SG_ 123 AccelPdlPosnSens_Flt "1FFFFF1FFF00FFh";
BA_ "FlexKomSigStartPos" SG_ 123 AccelPdlPosnSens_Flt 7;
BA_ "FlexKomSigName" SG_ 123 AccelPdlPosnSens_Flt "ECM_A2_PKT";
BA_ "FlexKomSigLaenge" SG_ 123 AccelPdlPosnSens_Flt 56;
BA_ "FlexKomSID" SG_ 123 AccelPdlPosnSens_Flt 455;
BA_ "FlexKomIsMotorola" SG_ 123 AccelPdlPosnSens_Flt 1;
BA_ "FlexKomComment" SG_ 123 AccelPdlPosnSens_Flt "ECM_A2 Packet";
BA_ "GenSigSNA" SG_ 123 LV12PwrFreeRq "0h";
BA_ "GenSigCycleTime" SG_ 123 LV12PwrFreeRq 20;
BA_ "FlexKomSigStartValue" SG_ 123 LV12PwrFreeRq "1FFFFF1FFF00FFh";
BA_ "FlexKomSigStartPos" SG_ 123 LV12PwrFreeRq 7;
BA_ "FlexKomSigName" SG_ 123 LV12PwrFreeRq "ECM_A2_PKT";
BA_ "FlexKomSigLaenge" SG_ 123 LV12PwrFreeRq 56;
BA_ "FlexKomSID" SG_ 123 LV12PwrFreeRq 455;
BA_ "FlexKomIsMotorola" SG_ 123 LV12PwrFreeRq 1;
BA_ "FlexKomComment" SG_ 123 LV12PwrFreeRq "ECM_A2 Packet";
BA_ "RID" SG_ 37 EngRPM "2185";
BA_ "GenSigTimeout_TCM" SG_ 37 EngRPM 105;
BA_ "GenSigTimeout_ORC" SG_ 37 EngRPM 35;
BA_ "GenSigTimeout_IC" SG_ 37 EngRPM 105;
BA_ "GenSigTimeout_ESM" SG_ 37 EngRPM 105;
BA_ "GenSigTimeout_EHPS" SG_ 37 EngRPM 105;
BA_ "GenSigTimeout_DTCM" SG_ 37 EngRPM 105;
BA_ "GenSigTimeout_CBC" SG_ 37 EngRPM 105;
BA_ "GenSigStartValue" SG_ 37 EngRPM 65535;
BA_ "GenSigSNA" SG_ 37 EngRPM "FFFFh";
BA_ "GenSigCycleTime" SG_ 37 EngRPM 10;
BA_ "FlexKomSigStartValue" SG_ 37 EngRPM "FFFF1FFF1FFF00FFh";
BA_ "FlexKomSigStartPos" SG_ 37 EngRPM 7;
BA_ "FlexKomSigName" SG_ 37 EngRPM "ECM_A1_PKT";
BA_ "FlexKomSigLaenge" SG_ 37 EngRPM 64;
BA_ "FlexKomSID" SG_ 37 EngRPM 446;
BA_ "FlexKomIsMotorola" SG_ 37 EngRPM 1;
BA_ "FlexKomComment" SG_ 37 EngRPM "ECM_A1 Packet";
BA_ "GenSigSNA" SG_ 37 MC_ECM_A1 "0h";
BA_ "GenSigCycleTime" SG_ 37 MC_ECM_A1 10;
BA_ "FlexKomSigStartValue" SG_ 37 MC_ECM_A1 "FFFF1FFF1FFF00FFh";
BA_ "FlexKomSigStartPos" SG_ 37 MC_ECM_A1 7;
BA_ "FlexKomSigName" SG_ 37 MC_ECM_A1 "ECM_A1_PKT";
BA_ "FlexKomSigLaenge" SG_ 37 MC_ECM_A1 64;
BA_ "FlexKomSID" SG_ 37 MC_ECM_A1 446;
BA_ "FlexKomIsMotorola" SG_ 37 MC_ECM_A1 1;
BA_ "FlexKomComment" SG_ 37 MC_ECM_A1 "ECM_A1 Packet";
BA_ "GenSigTimeout_IC" SG_ 631 TCASE_FAIL 10500;
BA_ "GenSigTimeout_ETM" SG_ 631 TCASE_FAIL 10500;
BA_ "GenSigSNA" SG_ 631 TCASE_FAIL "0h";
BA_ "GenSigSendType" SG_ 631 TCASE_FAIL 5;
BA_ "GenSigCycleTime" SG_ 631 TCASE_FAIL 1000;
BA_ "FlexKomSigStartValue" SG_ 631 TCASE_FAIL "0000000000000000h";
BA_ "FlexKomSigStartPos" SG_ 631 TCASE_FAIL 7;
BA_ "FlexKomSigName" SG_ 631 TCASE_FAIL "DTCM_B1_PKT";
BA_ "FlexKomSigLaenge" SG_ 631 TCASE_FAIL 64;
BA_ "FlexKomSID" SG_ 631 TCASE_FAIL 808;
BA_ "FlexKomIsMotorola" SG_ 631 TCASE_FAIL 1;
BA_ "FlexKomComment" SG_ 631 TCASE_FAIL "DTCM_B1_PKT";
BA_ "GenSigStartValue" SG_ 657 PTC_REL2_STAT 3;
BA_ "GenSigSNA" SG_ 657 PTC_REL2_STAT "3h";
BA_ "GenSigSendType" SG_ 657 PTC_REL2_STAT 5;
BA_ "GenSigCycleTime" SG_ 657 PTC_REL2_STAT 1000;
BA_ "FlexKomSigStartValue" SG_ 657 PTC_REL2_STAT "3Fh";
BA_ "FlexKomSigStartPos" SG_ 657 PTC_REL2_STAT 47;
BA_ "FlexKomSigName" SG_ 657 PTC_REL2_STAT "PTC_REL_STAT";
BA_ "FlexKomSigLaenge" SG_ 657 PTC_REL2_STAT 6;
BA_ "FlexKomSID" SG_ 657 PTC_REL2_STAT 859;
BA_ "FlexKomIsMotorola" SG_ 657 PTC_REL2_STAT 1;
BA_ "FlexKomComment" SG_ 657 PTC_REL2_STAT "PTC relays status";
BA_ "GenSigTimeout_ORC" SG_ 906 VC_VehCfg8_Stat 7000;
BA_ "GenSigTimeout_IC" SG_ 906 VC_VehCfg8_Stat 21000;
BA_ "GenSigStartValue" SG_ 906 VC_VehCfg8_Stat 3;
BA_ "GenSigSNA" SG_ 906 VC_VehCfg8_Stat "3h";
BA_ "GenSigSendType" SG_ 906 VC_VehCfg8_Stat 5;
BA_ "GenSigCycleTime" SG_ 906 VC_VehCfg8_Stat 2000;
BA_ "FlexKomSigStartValue" SG_ 906 VC_VehCfg8_Stat "0300000000000000h";
BA_ "FlexKomSigStartPos" SG_ 906 VC_VehCfg8_Stat 7;
BA_ "FlexKomSigName" SG_ 906 VC_VehCfg8_Stat "VehCfg8_Pkt";
BA_ "FlexKomSigLaenge" SG_ 906 VC_VehCfg8_Stat 64;
BA_ "FlexKomSID" SG_ 906 VC_VehCfg8_Stat 2722;
BA_ "FlexKomIsMotorola" SG_ 906 VC_VehCfg8_Stat 1;
BA_ "FlexKomComment" SG_ 906 VC_VehCfg8_Stat "Vehicle Configuration 8 Packet";
BA_ "GenSigTimeout_IC" SG_ 181 EngRPM_Tach 210;
BA_ "GenSigStartValue" SG_ 181 EngRPM_Tach 65535;
BA_ "GenSigSNA" SG_ 181 EngRPM_Tach "FFFFh";
BA_ "GenSigCycleTime" SG_ 181 EngRPM_Tach 20;
BA_ "FlexKomSigStartValue" SG_ 181 EngRPM_Tach "0000FFFF03AA00FFh";
BA_ "FlexKomSigStartPos" SG_ 181 EngRPM_Tach 7;
BA_ "FlexKomSigName" SG_ 181 EngRPM_Tach "ECM_ENG_TRQ2_PKT";
BA_ "FlexKomSigLaenge" SG_ 181 EngRPM_Tach 64;
BA_ "FlexKomSID" SG_ 181 EngRPM_Tach 2773;
BA_ "FlexKomIsMotorola" SG_ 181 EngRPM_Tach 1;
BA_ "FlexKomComment" SG_ 181 EngRPM_Tach "ECM_ENG_TRQ2_PKT";
BA_ "GenSigSNA" SG_ 179 OutputSpdPolarity_2 "3h";
BA_ "GenSigCycleTime" SG_ 179 OutputSpdPolarity_2 20;
BA_ "FlexKomSigStartValue" SG_ 179 OutputSpdPolarity_2 "0000FFFF000000FFh";
BA_ "FlexKomSigStartPos" SG_ 179 OutputSpdPolarity_2 7;
BA_ "FlexKomSigName" SG_ 179 OutputSpdPolarity_2 "TCM_ENG_SPD_PKT";
BA_ "FlexKomSigLaenge" SG_ 179 OutputSpdPolarity_2 64;
BA_ "FlexKomSID" SG_ 179 OutputSpdPolarity_2 2772;
BA_ "FlexKomIsMotorola" SG_ 179 OutputSpdPolarity_2 1;
BA_ "FlexKomComment" SG_ 179 OutputSpdPolarity_2 "TCM Engine Speed Packet";
BA_ "GenSigSNA" SG_ 179 TCM_Comm_Fail_ePT "0h";
BA_ "GenSigCycleTime" SG_ 179 TCM_Comm_Fail_ePT 20;
BA_ "FlexKomSigStartValue" SG_ 179 TCM_Comm_Fail_ePT "0000FFFF000000FFh";
BA_ "FlexKomSigStartPos" SG_ 179 TCM_Comm_Fail_ePT 7;
BA_ "FlexKomSigName" SG_ 179 TCM_Comm_Fail_ePT "TCM_ENG_SPD_PKT";
BA_ "FlexKomSigLaenge" SG_ 179 TCM_Comm_Fail_ePT 64;
BA_ "FlexKomSID" SG_ 179 TCM_Comm_Fail_ePT 2772;
BA_ "FlexKomIsMotorola" SG_ 179 TCM_Comm_Fail_ePT 1;
BA_ "FlexKomComment" SG_ 179 TCM_Comm_Fail_ePT "TCM Engine Speed Packet";
BA_ "GenSigStartValue" SG_ 179 CRC_TCM_ENG_SPD 255;
BA_ "GenSigSNA" SG_ 179 CRC_TCM_ENG_SPD "FFh";
BA_ "GenSigCycleTime" SG_ 179 CRC_TCM_ENG_SPD 20;
BA_ "FlexKomSigStartValue" SG_ 179 CRC_TCM_ENG_SPD "0000FFFF000000FFh";
BA_ "FlexKomSigStartPos" SG_ 179 CRC_TCM_ENG_SPD 7;
BA_ "FlexKomSigName" SG_ 179 CRC_TCM_ENG_SPD "TCM_ENG_SPD_PKT";
BA_ "FlexKomSigLaenge" SG_ 179 CRC_TCM_ENG_SPD 64;
BA_ "FlexKomSID" SG_ 179 CRC_TCM_ENG_SPD 2772;
BA_ "FlexKomIsMotorola" SG_ 179 CRC_TCM_ENG_SPD 1;
BA_ "FlexKomComment" SG_ 179 CRC_TCM_ENG_SPD "TCM Engine Speed Packet";
BA_ "GenSigSNA" SG_ 657 FT_WPR_NOT_PRK "0h";
BA_ "GenSigSendType" SG_ 657 FT_WPR_NOT_PRK 5;
BA_ "GenSigCycleTime" SG_ 657 FT_WPR_NOT_PRK 1000;
BA_ "FlexKomSigStartValue" SG_ 657 FT_WPR_NOT_PRK "00h";
BA_ "FlexKomSigStartPos" SG_ 657 FT_WPR_NOT_PRK 56;
BA_ "FlexKomSigName" SG_ 657 FT_WPR_NOT_PRK "FT_WPR_NOT_PRK";
BA_ "FlexKomSigLaenge" SG_ 657 FT_WPR_NOT_PRK 1;
BA_ "FlexKomSID" SG_ 657 FT_WPR_NOT_PRK 1046;
BA_ "FlexKomIsMotorola" SG_ 657 FT_WPR_NOT_PRK 1;
BA_ "FlexKomComment" SG_ 657 FT_WPR_NOT_PRK "Front wiper outside park position";
BA_ "GenSigStartValue" SG_ 34 CRC_PT_SYSTEM_1 255;
BA_ "GenSigSNA" SG_ 34 CRC_PT_SYSTEM_1 "FFh";
BA_ "GenSigCycleTime" SG_ 34 CRC_PT_SYSTEM_1 10;
BA_ "FlexKomSigStartValue" SG_ 34 CRC_PT_SYSTEM_1 "FFFFFF01F40000FFh";
BA_ "FlexKomSigStartPos" SG_ 34 CRC_PT_SYSTEM_1 7;
BA_ "FlexKomSigName" SG_ 34 CRC_PT_SYSTEM_1 "PT_SYSTEM_1_PKT";
BA_ "FlexKomSigLaenge" SG_ 34 CRC_PT_SYSTEM_1 64;
BA_ "FlexKomSID" SG_ 34 CRC_PT_SYSTEM_1 3370;
BA_ "FlexKomIsMotorola" SG_ 34 CRC_PT_SYSTEM_1 1;
BA_ "FlexKomComment" SG_ 34 CRC_PT_SYSTEM_1 "PT_SYSTEM_1_PKT Packet";
BA_ "GenSigSNA" SG_ 34 EngTrq_Enbl_Rq_AS_PT "0h";
BA_ "GenSigCycleTime" SG_ 34 EngTrq_Enbl_Rq_AS_PT 10;
BA_ "FlexKomSigStartValue" SG_ 34 EngTrq_Enbl_Rq_AS_PT "FFFFFF01F40000FFh";
BA_ "FlexKomSigStartPos" SG_ 34 EngTrq_Enbl_Rq_AS_PT 7;
BA_ "FlexKomSigName" SG_ 34 EngTrq_Enbl_Rq_AS_PT "PT_SYSTEM_1_PKT";
BA_ "FlexKomSigLaenge" SG_ 34 EngTrq_Enbl_Rq_AS_PT 64;
BA_ "FlexKomSID" SG_ 34 EngTrq_Enbl_Rq_AS_PT 3370;
BA_ "FlexKomIsMotorola" SG_ 34 EngTrq_Enbl_Rq_AS_PT 1;
BA_ "FlexKomComment" SG_ 34 EngTrq_Enbl_Rq_AS_PT "PT_SYSTEM_1_PKT Packet";
BA_ "GenSigSNA" SG_ 120 BrakePedalPressure "7FFh";
BA_ "GenSigCycleTime" SG_ 120 BrakePedalPressure 20;
BA_ "FlexKomSigStartValue" SG_ 120 BrakePedalPressure "00000000000000FFh";
BA_ "FlexKomSigStartPos" SG_ 120 BrakePedalPressure 7;
BA_ "FlexKomSigName" SG_ 120 BrakePedalPressure "ESP_A10_Pkt";
BA_ "FlexKomSigLaenge" SG_ 120 BrakePedalPressure 64;
BA_ "FlexKomSID" SG_ 120 BrakePedalPressure 2964;
BA_ "FlexKomIsMotorola" SG_ 120 BrakePedalPressure 1;
BA_ "FlexKomComment" SG_ 120 BrakePedalPressure "ESP_A10_Pkt";
BA_ "GenSigSNA" SG_ 120 BrakeBoostPressure "7FFh";
BA_ "GenSigCycleTime" SG_ 120 BrakeBoostPressure 20;
BA_ "FlexKomSigStartValue" SG_ 120 BrakeBoostPressure "00000000000000FFh";
BA_ "FlexKomSigStartPos" SG_ 120 BrakeBoostPressure 7;
BA_ "FlexKomSigName" SG_ 120 BrakeBoostPressure "ESP_A10_Pkt";
BA_ "FlexKomSigLaenge" SG_ 120 BrakeBoostPressure 64;
BA_ "FlexKomSID" SG_ 120 BrakeBoostPressure 2964;
BA_ "FlexKomIsMotorola" SG_ 120 BrakeBoostPressure 1;
BA_ "FlexKomComment" SG_ 120 BrakeBoostPressure "ESP_A10_Pkt";
BA_ "GenSigSNA" SG_ 124 RPMOverRev_PHEV "0h";
BA_ "GenSigCycleTime" SG_ 124 RPMOverRev_PHEV 20;
BA_ "FlexKomSigStartValue" SG_ 124 RPMOverRev_PHEV "FF0000001FFF00FFh";
BA_ "FlexKomSigStartPos" SG_ 124 RPMOverRev_PHEV 7;
BA_ "FlexKomSigName" SG_ 124 RPMOverRev_PHEV "ECM_A2_PHEV_PKT";
BA_ "FlexKomSigLaenge" SG_ 124 RPMOverRev_PHEV 64;
BA_ "FlexKomSID" SG_ 124 RPMOverRev_PHEV 2991;
BA_ "FlexKomIsMotorola" SG_ 124 RPMOverRev_PHEV 1;
BA_ "FlexKomComment" SG_ 124 RPMOverRev_PHEV "ECM_A2_PHEV_PKT";
BA_ "GenSigTimeout_TCM" SG_ 124 EngTrq_Enbl_Rq_TCM_PHEV 210;
BA_ "GenSigTimeout_ORC" SG_ 155 PsngrDoorAjarRawValSts 70;
BA_ "GenSigSNA" SG_ 155 PsngrDoorAjarRawValSts "Fh";
BA_ "GenSigCycleTime" SG_ 155 PsngrDoorAjarRawValSts 20;
BA_ "FlexKomSigStartValue" SG_ 155 PsngrDoorAjarRawValSts "3FFF0C00000000FFh";
BA_ "FlexKomSigStartPos" SG_ 155 PsngrDoorAjarRawValSts 7;
BA_ "FlexKomSigName" SG_ 155 PsngrDoorAjarRawValSts "CBC_PT6_Pkt";
BA_ "FlexKomSigLaenge" SG_ 155 PsngrDoorAjarRawValSts 64;
BA_ "FlexKomSID" SG_ 155 PsngrDoorAjarRawValSts 1943;
BA_ "FlexKomIsMotorola" SG_ 155 PsngrDoorAjarRawValSts 1;
BA_ "FlexKomComment" SG_ 155 PsngrDoorAjarRawValSts "CBC_PT6 message packet";
BA_ "GenSigSNA" SG_ 155 LeakCheckTimerExpired "3h";
BA_ "GenSigCycleTime" SG_ 155 LeakCheckTimerExpired 20;
BA_ "FlexKomSigStartValue" SG_ 155 LeakCheckTimerExpired "3FFF0C00000000FFh";
BA_ "FlexKomSigStartPos" SG_ 155 LeakCheckTimerExpired 7;
BA_ "FlexKomSigName" SG_ 155 LeakCheckTimerExpired "CBC_PT6_Pkt";
BA_ "FlexKomSigLaenge" SG_ 155 LeakCheckTimerExpired 64;
BA_ "FlexKomSID" SG_ 155 LeakCheckTimerExpired 1943;
BA_ "FlexKomIsMotorola" SG_ 155 LeakCheckTimerExpired 1;
BA_ "FlexKomComment" SG_ 155 LeakCheckTimerExpired "CBC_PT6 message packet";
BA_ "GenSigTimeout_ORC" SG_ 155 BonnetAjarRawValSts 70;
BA_ "GenSigSNA" SG_ 155 BonnetAjarRawValSts "Fh";
BA_ "GenSigCycleTime" SG_ 155 BonnetAjarRawValSts 20;
BA_ "FlexKomSigStartValue" SG_ 155 BonnetAjarRawValSts "3FFF0C00000000FFh";
BA_ "FlexKomSigStartPos" SG_ 155 BonnetAjarRawValSts 7;
BA_ "FlexKomSigName" SG_ 155 BonnetAjarRawValSts "CBC_PT6_Pkt";
BA_ "FlexKomSigLaenge" SG_ 155 BonnetAjarRawValSts 64;
BA_ "FlexKomSID" SG_ 155 BonnetAjarRawValSts 1943;
BA_ "FlexKomIsMotorola" SG_ 155 BonnetAjarRawValSts 1;
BA_ "FlexKomComment" SG_ 155 BonnetAjarRawValSts "CBC_PT6 message packet";
BA_ "GenSigSNA" SG_ 906 VC_TACHO_TYPE "0h";
BA_ "GenSigSendType" SG_ 906 VC_TACHO_TYPE 5;
BA_ "GenSigCycleTime" SG_ 906 VC_TACHO_TYPE 2000;
BA_ "FlexKomSID" SG_ 117 MC_10Eh 2519;
BA_ "FlexKomIsMotorola" SG_ 117 MC_10Eh 1;
BA_ "FlexKomComment" SG_ 117 MC_10Eh "ESP_A9_Pkt";
BA_ "GenSigTimeout_RF_HUB" SG_ 53 ESS_ENG_ST 105;
BA_ "GenSigTimeout_ORC" SG_ 53 ESS_ENG_ST 35;
BA_ "GenSigTimeout_CBC" SG_ 53 ESS_ENG_ST 105;
BA_ "GenSigStartValue" SG_ 53 ESS_ENG_ST 15;
BA_ "GenSigSNA" SG_ 53 ESS_ENG_ST "Fh";
BA_ "GenSigCycleTime" SG_ 53 ESS_ENG_ST 10;
BA_ "FlexKomSigStartValue" SG_ 53 ESS_ENG_ST "5FFF1FFF00FF0FFFh";
BA_ "FlexKomSigStartPos" SG_ 53 ESS_ENG_ST 7;
BA_ "FlexKomSigName" SG_ 53 ESS_ENG_ST "ECM_A3_PKT";
BA_ "FlexKomSigLaenge" SG_ 53 ESS_ENG_ST 64;
BA_ "FlexKomSID" SG_ 53 ESS_ENG_ST 1369;
BA_ "FlexKomIsMotorola" SG_ 53 ESS_ENG_ST 1;
BA_ "FlexKomComment" SG_ 53 ESS_ENG_ST "ECM_A3 message packet";
BA_ "RID" SG_ 319 CurrBattFailStatus "5107";
BA_ "GenSigSNA" SG_ 319 CurrBattFailStatus "0h";
BA_ "GenSigCycleTime" SG_ 319 CurrBattFailStatus 100;
BA_ "FlexKomSigStartValue" SG_ 319 CurrBattFailStatus "00h";
BA_ "FlexKomSigStartPos" SG_ 319 CurrBattFailStatus 35;
BA_ "FlexKomSigName" SG_ 319 CurrBattFailStatus "CurrBattFailStatus";
BA_ "FlexKomSigLaenge" SG_ 319 CurrBattFailStatus 1;
BA_ "FlexKomSID" SG_ 319 CurrBattFailStatus 2655;
BA_ "FlexKomIsMotorola" SG_ 319 CurrBattFailStatus 1;
BA_ "FlexKomComment" SG_ 319 CurrBattFailStatus "Failure Status of Current meas. (internal defect)";
BA_ "GenSigSNA" SG_ 319 CBCSAMFailSts "0h";
BA_ "GenSigCycleTime" SG_ 319 CBCSAMFailSts 100;
BA_ "FlexKomSigStartValue" SG_ 319 CBCSAMFailSts "00h";
BA_ "FlexKomSigStartPos" SG_ 319 CBCSAMFailSts 39;
BA_ "FlexKomSigName" SG_ 319 CBCSAMFailSts "CBCSAMFailSts";
BA_ "FlexKomSigLaenge" SG_ 319 CBCSAMFailSts 1;
BA_ "FlexKomSID" SG_ 319 CBCSAMFailSts 2648;
BA_ "FlexKomIsMotorola" SG_ 319 CBCSAMFailSts 1;
BA_ "FlexKomComment" SG_ 319 CBCSAMFailSts "Fault present in BCM related to the SAM strategy";
BA_ "GenSigTimeout_RF_HUB" SG_ 657 PARK_BRK_EGD 10500;
BA_ "GenSigTimeout_IC" SG_ 657 PARK_BRK_EGD 10500;
BA_ "GenSigTimeout_DTCM" SG_ 657 PARK_BRK_EGD 10500;
BA_ "GenSigSNA" SG_ 657 PARK_BRK_EGD "0h";
BA_ "GenSigSendType" SG_ 657 PARK_BRK_EGD 5;
BA_ "GenSigCycleTime" SG_ 657 PARK_BRK_EGD 1000;
BA_ "FlexKomSigStartValue" SG_ 657 PARK_BRK_EGD "00h";
BA_ "FlexKomSigStartPos" SG_ 657 PARK_BRK_EGD 23;
BA_ "FlexKomSigName" SG_ 657 PARK_BRK_EGD "PARK_BRK_EGD";
BA_ "FlexKomSigLaenge" SG_ 657 PARK_BRK_EGD 1;
BA_ "FlexKomSID" SG_ 657 PARK_BRK_EGD 805;
BA_ "FlexKomIsMotorola" SG_ 657 PARK_BRK_EGD 1;
BA_ "FlexKomComment" SG_ 657 PARK_BRK_EGD "Park brake switch engaged";
BA_ "GenSigSNA" SG_ 181 EngineStaticTorqueV "0h";
BA_ "GenSigCycleTime" SG_ 181 EngineStaticTorqueV 20;
BA_ "FlexKomSigStartValue" SG_ 181 EngineStaticTorqueV "0000FFFF03AA00FFh";
BA_ "FlexKomSigStartPos" SG_ 181 EngineStaticTorqueV 7;
BA_ "FlexKomSigName" SG_ 181 EngineStaticTorqueV "ECM_ENG_TRQ2_PKT";
BA_ "FlexKomSigLaenge" SG_ 181 EngineStaticTorqueV 64;
BA_ "FlexKomSID" SG_ 181 EngineStaticTorqueV 2773;
BA_ "FlexKomIsMotorola" SG_ 181 EngineStaticTorqueV 1;
BA_ "FlexKomComment" SG_ 181 EngineStaticTorqueV "ECM_ENG_TRQ2_PKT";
BA_ "GenSigStartValue" SG_ 833 GPF_T1_TEMP 25;
BA_ "GenSigSNA" SG_ 833 GPF_T1_TEMP "0h";
BA_ "GenSigCycleTime" SG_ 833 GPF_T1_TEMP 500;
BA_ "FlexKomSigStartValue" SG_ 833 GPF_T1_TEMP "0019001900000000h";
BA_ "FlexKomSigStartPos" SG_ 833 GPF_T1_TEMP 7;
BA_ "FlexKomSigName" SG_ 833 GPF_T1_TEMP "GPF_DATA_1_PKT";
BA_ "FlexKomSigLaenge" SG_ 833 GPF_T1_TEMP 64;
BA_ "FlexKomSID" SG_ 833 GPF_T1_TEMP 2850;
BA_ "FlexKomIsMotorola" SG_ 833 GPF_T1_TEMP 1;
BA_ "FlexKomComment" SG_ 833 GPF_T1_TEMP "GPF_DATA_1 packet";
BA_ "GenSigCycleTime" SG_ 37 CRC_ECM_A1 10;
BA_ "FlexKomSigStartValue" SG_ 37 CRC_ECM_A1 "FFFF1FFF1FFF00FFh";
BA_ "FlexKomSigStartPos" SG_ 37 CRC_ECM_A1 7;
BA_ "FlexKomSigName" SG_ 37 CRC_ECM_A1 "ECM_A1_PKT";
BA_ "FlexKomSigLaenge" SG_ 37 CRC_ECM_A1 64;
BA_ "FlexKomSID" SG_ 37 CRC_ECM_A1 446;
BA_ "FlexKomIsMotorola" SG_ 37 CRC_ECM_A1 1;
BA_ "FlexKomComment" SG_ 37 CRC_ECM_A1 "ECM_A1 Packet";
BA_ "GenSigStartValue" SG_ 157 CRC_ECM_A5 255;
BA_ "GenSigSNA" SG_ 157 CRC_ECM_A5 "FFh";
BA_ "GenSigCycleTime" SG_ 157 CRC_ECM_A5 20;
BA_ "FlexKomSigStartValue" SG_ 157 CRC_ECM_A5 "FFFFFFFF00000CFFh";
BA_ "FlexKomSigStartPos" SG_ 157 CRC_ECM_A5 7;
BA_ "FlexKomSigName" SG_ 157 CRC_ECM_A5 "ECM_A5_PKT";
BA_ "FlexKomSigLaenge" SG_ 157 CRC_ECM_A5 64;
BA_ "FlexKomSID" SG_ 157 CRC_ECM_A5 1821;
BA_ "FlexKomIsMotorola" SG_ 157 CRC_ECM_A5 1;
BA_ "FlexKomComment" SG_ 157 CRC_ECM_A5 "ECM_A5 Packet";
BA_ "GenSigStartValue" SG_ 53 EngTrqTgt_SEM 8191;
BA_ "GenSigSNA" SG_ 53 EngTrqTgt_SEM "1FFFh";
BA_ "GenSigCycleTime" SG_ 53 EngTrqTgt_SEM 10;
BA_ "FlexKomSigStartValue" SG_ 53 EngTrqTgt_SEM "5FFF1FFF00FF0FFFh";
BA_ "FlexKomSigStartPos" SG_ 53 EngTrqTgt_SEM 7;
BA_ "FlexKomSigName" SG_ 53 EngTrqTgt_SEM "ECM_A3_PKT";
BA_ "FlexKomSigLaenge" SG_ 53 EngTrqTgt_SEM 64;
BA_ "FlexKomSID" SG_ 53 EngTrqTgt_SEM 1369;
BA_ "FlexKomIsMotorola" SG_ 53 EngTrqTgt_SEM 1;
BA_ "FlexKomComment" SG_ 53 EngTrqTgt_SEM "ECM_A3 message packet";
BA_ "GenSigStartValue" SG_ 117 CRC_10Eh 255;
BA_ "GenSigSNA" SG_ 117 CRC_10Eh "FFh";
BA_ "GenSigCycleTime" SG_ 117 CRC_10Eh 20;
BA_ "FlexKomSigStartValue" SG_ 117 CRC_10Eh "00000000000000FFh";
BA_ "FlexKomSigStartPos" SG_ 117 CRC_10Eh 7;
BA_ "FlexKomSigName" SG_ 117 CRC_10Eh "ESP_A9_Pkt";
BA_ "FlexKomSigLaenge" SG_ 117 CRC_10Eh 64;
BA_ "FlexKomSID" SG_ 117 CRC_10Eh 2519;
BA_ "FlexKomIsMotorola" SG_ 117 CRC_10Eh 1;
BA_ "FlexKomComment" SG_ 117 CRC_10Eh "ESP_A9_Pkt";
BA_ "GenSigTimeout_IC" SG_ 323 DrvAway_Alert 1050;
BA_ "GenSigSNA" SG_ 323 DrvAway_Alert "0h";
BA_ "GenSigCycleTime" SG_ 323 DrvAway_Alert 100;
BA_ "FlexKomSigStartValue" SG_ 323 DrvAway_Alert "00h";
BA_ "FlexKomSigStartPos" SG_ 323 DrvAway_Alert 7;
BA_ "FlexKomSigName" SG_ 323 DrvAway_Alert "DrvAway_Alert";
BA_ "FlexKomSigLaenge" SG_ 323 DrvAway_Alert 1;
BA_ "FlexKomSID" SG_ 323 DrvAway_Alert 2390;
BA_ "FlexKomIsMotorola" SG_ 323 DrvAway_Alert 1;
BA_ "FlexKomComment" SG_ 323 DrvAway_Alert "Drive Away Alert; True = [1]";
BA_ "GenSigTimeout_IC" SG_ 232 SetSpeed_KPH 630;
BA_ "GenSigStartValue" SG_ 232 SetSpeed_KPH 255;
BA_ "GenSigSNA" SG_ 232 SetSpeed_KPH "FFh";
BA_ "GenSigCycleTime" SG_ 232 SetSpeed_KPH 60;
BA_ "FlexKomSigStartValue" SG_ 232 SetSpeed_KPH "00FFFF00000000FFh";
BA_ "FlexKomSigStartPos" SG_ 232 SetSpeed_KPH 7;
BA_ "FlexKomSigName" SG_ 232 SetSpeed_KPH "DAS_A4_PKT";
BA_ "FlexKomSigLaenge" SG_ 232 SetSpeed_KPH 64;
BA_ "FlexKomSID" SG_ 232 SetSpeed_KPH 1717;
BA_ "FlexKomIsMotorola" SG_ 232 SetSpeed_KPH 1;
BA_ "FlexKomComment" SG_ 232 SetSpeed_KPH "DAS_A4 Packet";
BA_ "GenSigTimeout_ORC" SG_ 232 ACCOnOff 210;
BA_ "GenSigTimeout_IC" SG_ 232 ACCOnOff 630;
BA_ "GenSigSNA" SG_ 232 ACCOnOff "7h";
BA_ "GenSigCycleTime" SG_ 232 ACCOnOff 60;
BA_ "FlexKomSigStartValue" SG_ 232 ACCOnOff "00FFFF00000000FFh";
BA_ "FlexKomSigStartPos" SG_ 232 ACCOnOff 7;
BA_ "FlexKomSigName" SG_ 232 ACCOnOff "DAS_A4_PKT";
BA_ "FlexKomSigLaenge" SG_ 232 ACCOnOff 64;
BA_ "FlexKomSID" SG_ 232 ACCOnOff 1717;
BA_ "FlexKomIsMotorola" SG_ 232 ACCOnOff 1;
BA_ "FlexKomComment" SG_ 232 ACCOnOff "DAS_A4 Packet";
BA_ "GenSigTimeout_RF_HUB" SG_ 299 AMB_TEMP_AVG 1050;
BA_ "GenSigTimeout_ORC" SG_ 299 AMB_TEMP_AVG 350;
BA_ "GenSigTimeout_IC" SG_ 299 AMB_TEMP_AVG 1050;
BA_ "GenSigStartValue" SG_ 299 AMB_TEMP_AVG 65535;
BA_ "GenSigSNA" SG_ 299 AMB_TEMP_AVG "FFFFh";
BA_ "GenSigCycleTime" SG_ 299 AMB_TEMP_AVG 100;
BA_ "FlexKomSigStartValue" SG_ 299 AMB_TEMP_AVG "FFFFh";
BA_ "FlexKomSigStartPos" SG_ 299 AMB_TEMP_AVG 15;
BA_ "FlexKomSigName" SG_ 299 AMB_TEMP_AVG "AMB_TEMP_AVG";
BA_ "FlexKomSigLaenge" SG_ 299 AMB_TEMP_AVG 16;
BA_ "FlexKomSID" SG_ 299 AMB_TEMP_AVG 840;
BA_ "FlexKomIsMotorola" SG_ 299 AMB_TEMP_AVG 1;
BA_ "FlexKomComment" SG_ 299 AMB_TEMP_AVG "Averaged ambient temperature";
BA_ "GenSigTimeout_ORC" SG_ 119 RemStActv 70;
BA_ "GenSigTimeout_IC" SG_ 119 RemStActv 210;
BA_ "GenSigTimeout_ESM" SG_ 119 RemStActv 310;
BA_ "GenSigSNA" SG_ 119 RemStActv "0h";
BA_ "GenSigCycleTime" SG_ 119 RemStActv 20;
BA_ "FlexKomSigStartValue" SG_ 119 RemStActv "0000h";
BA_ "FlexKomSigStartPos" SG_ 119 RemStActv 7;
BA_ "FlexKomSigName" SG_ 119 RemStActv "VehStart_PKT";
BA_ "FlexKomSigLaenge" SG_ 119 RemStActv 16;
BA_ "FlexKomSID" SG_ 119 RemStActv 880;
BA_ "FlexKomIsMotorola" SG_ 119 RemStActv 1;
BA_ "FlexKomComment" SG_ 119 RemStActv "Vehicle start packet";
BA_ "GenSigTimeout_ORC" SG_ 119 StartRelayBCMFault 70;
BA_ "GenSigSNA" SG_ 119 StartRelayBCMFault "0h";
BA_ "GenSigCycleTime" SG_ 119 StartRelayBCMFault 20;
BA_ "FlexKomSigStartValue" SG_ 119 StartRelayBCMFault "00h";
BA_ "FlexKomSigStartPos" SG_ 119 StartRelayBCMFault 14;
BA_ "FlexKomSigName" SG_ 119 StartRelayBCMFault "StartRelayBCMFault";
BA_ "FlexKomSigLaenge" SG_ 119 StartRelayBCMFault 1;
BA_ "FlexKomSID" SG_ 119 StartRelayBCMFault 1573;
BA_ "FlexKomIsMotorola" SG_ 119 StartRelayBCMFault 1;
BA_ "FlexKomComment" SG_ 119 StartRelayBCMFault "CBC starter relay fault detected";
BA_ "GenSigStartValue" SG_ 54 CRC_HCP_A2 255;
BA_ "GenSigSNA" SG_ 54 CRC_HCP_A2 "FFh";
BA_ "GenSigCycleTime" SG_ 54 CRC_HCP_A2 10;
BA_ "FlexKomSigStartValue" SG_ 54 CRC_HCP_A2 "1FFF1FFF1FFF00FFh";
BA_ "FlexKomSigStartPos" SG_ 54 CRC_HCP_A2 7;
BA_ "FlexKomSigName" SG_ 54 CRC_HCP_A2 "HCP_A2_PKT";
BA_ "FlexKomSigLaenge" SG_ 54 CRC_HCP_A2 64;
BA_ "FlexKomSID" SG_ 54 CRC_HCP_A2 2994;
BA_ "FlexKomIsMotorola" SG_ 54 CRC_HCP_A2 1;
BA_ "FlexKomComment" SG_ 54 CRC_HCP_A2 "HCP_A2_PKT";
BA_ "RID" SG_ 157 ActlAccelPdlPosn "5035";
BA_ "GenSigTimeout_CBC" SG_ 157 ActlAccelPdlPosn 210;
BA_ "GenSigStartValue" SG_ 157 ActlAccelPdlPosn 255;
BA_ "GenSigSNA" SG_ 157 ActlAccelPdlPosn "FFh";
BA_ "GenSigCycleTime" SG_ 157 ActlAccelPdlPosn 20;
BA_ "FlexKomSigStartValue" SG_ 157 ActlAccelPdlPosn "FFFFFFFF00000CFFh";
BA_ "FlexKomSigStartPos" SG_ 157 ActlAccelPdlPosn 7;
BA_ "FlexKomSigName" SG_ 157 ActlAccelPdlPosn "ECM_A5_PKT";
BA_ "FlexKomSigLaenge" SG_ 157 ActlAccelPdlPosn 64;
BA_ "FlexKomSID" SG_ 157 ActlAccelPdlPosn 1821;
BA_ "FlexKomIsMotorola" SG_ 157 ActlAccelPdlPosn 1;
BA_ "FlexKomComment" SG_ 157 ActlAccelPdlPosn "ECM_A5 Packet";
BA_ "GenSigSNA" SG_ 157 Analog_Clutch "FFh";
BA_ "GenSigCycleTime" SG_ 157 Analog_Clutch 20;
BA_ "FlexKomSigStartValue" SG_ 157 Analog_Clutch "FFFFFFFF00000CFFh";
BA_ "FlexKomSigStartPos" SG_ 157 Analog_Clutch 7;
BA_ "FlexKomSigName" SG_ 157 Analog_Clutch "ECM_A5_PKT";
BA_ "FlexKomSigLaenge" SG_ 157 Analog_Clutch 64;
BA_ "FlexKomSID" SG_ 157 Analog_Clutch 1821;
BA_ "GenSigSNA" SG_ 53 MC_ECM_A3 "0h";
BA_ "GenSigCycleTime" SG_ 53 MC_ECM_A3 10;
BA_ "FlexKomSigStartValue" SG_ 53 MC_ECM_A3 "5FFF1FFF00FF0FFFh";
BA_ "FlexKomSigStartPos" SG_ 53 MC_ECM_A3 7;
BA_ "FlexKomSigName" SG_ 53 MC_ECM_A3 "ECM_A3_PKT";
BA_ "FlexKomSigLaenge" SG_ 53 MC_ECM_A3 64;
BA_ "FlexKomSID" SG_ 53 MC_ECM_A3 1369;
BA_ "FlexKomIsMotorola" SG_ 53 MC_ECM_A3 1;
BA_ "FlexKomComment" SG_ 53 MC_ECM_A3 "ECM_A3 message packet";
BA_ "GenSigTimeout_TBM" SG_ 657 DRV_AJAR 10500;
BA_ "GenSigTimeout_RF_HUB" SG_ 657 DRV_AJAR 10500;
BA_ "GenSigTimeout_IC" SG_ 657 DRV_AJAR 10500;
BA_ "GenSigSNA" SG_ 657 DRV_AJAR "0h";
BA_ "GenSigSendType" SG_ 657 DRV_AJAR 5;
BA_ "GenSigCycleTime" SG_ 657 DRV_AJAR 1000;
BA_ "FlexKomSigStartValue" SG_ 657 DRV_AJAR "00h";
BA_ "FlexKomSigStartPos" SG_ 657 DRV_AJAR 22;
BA_ "FlexKomSigName" SG_ 657 DRV_AJAR "DR_AJAR";
BA_ "FlexKomSigLaenge" SG_ 657 DRV_AJAR 6;
BA_ "FlexKomSID" SG_ 657 DRV_AJAR 797;
BA_ "FlexKomIsMotorola" SG_ 657 DRV_AJAR 1;
BA_ "FlexKomComment" SG_ 657 DRV_AJAR "Door ajar";
BA_ "RID" SG_ 319 VoltBattFailStatus "5083";
BA_ "GenSigSNA" SG_ 319 VoltBattFailStatus "0h";
BA_ "GenSigCycleTime" SG_ 319 VoltBattFailStatus 100;
BA_ "FlexKomSigStartValue" SG_ 319 VoltBattFailStatus "00h";
BA_ "FlexKomSigStartPos" SG_ 319 VoltBattFailStatus 36;
BA_ "FlexKomSigName" SG_ 319 VoltBattFailStatus "VoltBattFailStatus";
BA_ "FlexKomSigLaenge" SG_ 319 VoltBattFailStatus 1;
BA_ "FlexKomSID" SG_ 319 VoltBattFailStatus 2654;
BA_ "FlexKomIsMotorola" SG_ 319 VoltBattFailStatus 1;
BA_ "FlexKomComment" SG_ 319 VoltBattFailStatus "Failure Status of Voltage meas. (internal defect)";
BA_ "RID" SG_ 319 IBS3_Ibatt "5110";
BA_ "GenSigStartValue" SG_ 319 IBS3_Ibatt 65535;
BA_ "GenSigSNA" SG_ 319 IBS3_Ibatt "FFFFh";
BA_ "GenSigCycleTime" SG_ 319 IBS3_Ibatt 100;
BA_ "FlexKomSigStartValue" SG_ 319 IBS3_Ibatt "FFFFh";
BA_ "FlexKomSigStartPos" SG_ 319 IBS3_Ibatt 23;
BA_ "FlexKomSigName" SG_ 319 IBS3_Ibatt "IBS3_Ibatt";
BA_ "FlexKomSigLaenge" SG_ 319 IBS3_Ibatt 16;
BA_ "FlexKomSID" SG_ 319 IBS3_Ibatt 2650;
BA_ "FlexKomIsMotorola" SG_ 319 IBS3_Ibatt 1;
BA_ "FlexKomComment" SG_ 319 IBS3_Ibatt "Battery current";
BA_ "GenSigTimeout_IC" SG_ 607 GlobDrvMdSts 10500;
BA_ "GenSigSNA" SG_ 607 GlobDrvMdSts "1Fh";
BA_ "GenSigSendType" SG_ 607 GlobDrvMdSts 5;
BA_ "GenSigCycleTime" SG_ 607 GlobDrvMdSts 1000;
BA_ "FlexKomSigStartValue" SG_ 607 GlobDrvMdSts "00h";
BA_ "FlexKomSigStartPos" SG_ 607 GlobDrvMdSts 36;
BA_ "FlexKomSigName" SG_ 607 GlobDrvMdSts "GlobDrvMdSts";
BA_ "FlexKomSigLaenge" SG_ 607 GlobDrvMdSts 5;
BA_ "FlexKomSID" SG_ 607 GlobDrvMdSts 2392;
BA_ "FlexKomIsMotorola" SG_ 607 GlobDrvMdSts 1;
BA_ "FlexKomComment" SG_ 607 GlobDrvMdSts "Global drive mode status";
BA_ "GenSigCycleTime" SG_ 299 AirTemp_Outsd 100;
BA_ "FlexKomSigStartValue" SG_ 299 AirTemp_Outsd "FFh";
BA_ "FlexKomSigStartPos" SG_ 299 AirTemp_Outsd 7;
BA_ "FlexKomSigName" SG_ 299 AirTemp_Outsd "AirTemp_Outsd";
BA_ "FlexKomSigLaenge" SG_ 299 AirTemp_Outsd 8;
BA_ "FlexKomSID" SG_ 299 AirTemp_Outsd 773;
BA_ "FlexKomIsMotorola" SG_ 299 AirTemp_Outsd 1;
BA_ "FlexKomComment" SG_ 299 AirTemp_Outsd "Outside air temperature";
BA_ "GenSigTimeout_IC" SG_ 299 FUEL_VOLT 1050;
BA_ "GenSigSNA" SG_ 299 FUEL_VOLT "0h";
BA_ "GenSigCycleTime" SG_ 299 FUEL_VOLT 100;
BA_ "FlexKomSigStartValue" SG_ 299 FUEL_VOLT "FFh";
BA_ "GenSigStartValue" SG_ 167 SyncPos 6;
BA_ "GenSigSNA" SG_ 167 SyncPos "7h";
BA_ "GenSigCycleTime" SG_ 167 SyncPos 20;
BA_ "FlexKomSigStartValue" SG_ 167 SyncPos "04000000C00000FFh";
BA_ "FlexKomSigStartPos" SG_ 167 SyncPos 7;
BA_ "FlexKomSigName" SG_ 167 SyncPos "DST_TOC";
BA_ "FlexKomSigLaenge" SG_ 167 SyncPos 64;
BA_ "FlexKomSID" SG_ 167 SyncPos 1909;
BA_ "FlexKomIsMotorola" SG_ 167 SyncPos 1;
BA_ "FlexKomComment" SG_ 167 SyncPos "DST_TOC";
BA_ "GenSigStartValue" SG_ 462 CRC_DPDM_A2 255;
BA_ "GenSigSNA" SG_ 462 CRC_DPDM_A2 "FFh";
BA_ "GenSigCycleTime" SG_ 462 CRC_DPDM_A2 50;
BA_ "FlexKomSigStartValue" SG_ 462 CRC_DPDM_A2 "000000FFh";
BA_ "FlexKomSigStartPos" SG_ 462 CRC_DPDM_A2 7;
BA_ "FlexKomSigName" SG_ 462 CRC_DPDM_A2 "DPDM_A2_PKT";
BA_ "FlexKomSigLaenge" SG_ 462 CRC_DPDM_A2 32;
BA_ "FlexKomSID" SG_ 462 CRC_DPDM_A2 2683;
BA_ "FlexKomIsMotorola" SG_ 462 CRC_DPDM_A2 1;
BA_ "FlexKomComment" SG_ 462 CRC_DPDM_A2 "DPDM_A2_PKT";
BA_ "GenSigSNA" SG_ 53 EngRdyForESS "0h";
BA_ "GenSigCycleTime" SG_ 53 EngRdyForESS 10;
BA_ "FlexKomSigStartValue" SG_ 53 EngRdyForESS "5FFF1FFF00FF0FFFh";
BA_ "FlexKomSigStartPos" SG_ 53 EngRdyForESS 7;
BA_ "FlexKomSigName" SG_ 53 EngRdyForESS "ECM_A3_PKT";
BA_ "FlexKomSigLaenge" SG_ 53 EngRdyForESS 64;
BA_ "FlexKomSID" SG_ 53 EngRdyForESS 1369;
BA_ "FlexKomIsMotorola" SG_ 53 EngRdyForESS 1;
BA_ "FlexKomComment" SG_ 53 EngRdyForESS "ECM_A3 message packet";
BA_ "GenSigSNA" SG_ 123 EngTrq_Enbl_Rq_ESC "0h";
BA_ "GenSigCycleTime" SG_ 123 EngTrq_Enbl_Rq_ESC 20;
BA_ "FlexKomSigStartValue" SG_ 123 EngTrq_Enbl_Rq_ESC "1FFFFF1FFF00FFh";
BA_ "FlexKomSigStartPos" SG_ 123 EngTrq_Enbl_Rq_ESC 7;
BA_ "FlexKomSigName" SG_ 123 EngTrq_Enbl_Rq_ESC "ECM_A2_PKT";
BA_ "FlexKomSigLaenge" SG_ 123 EngTrq_Enbl_Rq_ESC 56;
BA_ "FlexKomSID" SG_ 123 EngTrq_Enbl_Rq_ESC 455;
BA_ "FlexKomIsMotorola" SG_ 123 EngTrq_Enbl_Rq_ESC 1;
BA_ "FlexKomComment" SG_ 123 EngTrq_Enbl_Rq_ESC "ECM_A2 Packet";
BA_ "GenSigSNA" SG_ 123 MC_ECM_A2 "0h";
BA_ "GenSigCycleTime" SG_ 123 MC_ECM_A2 20;
BA_ "FlexKomSigStartValue" SG_ 123 MC_ECM_A2 "1FFFFF1FFF00FFh";
BA_ "FlexKomSigStartPos" SG_ 123 MC_ECM_A2 7;
BA_ "FlexKomSigName" SG_ 123 MC_ECM_A2 "ECM_A2_PKT";
BA_ "FlexKomSigLaenge" SG_ 123 MC_ECM_A2 56;
BA_ "FlexKomSID" SG_ 123 MC_ECM_A2 455;
BA_ "FlexKomIsMotorola" SG_ 123 MC_ECM_A2 1;
BA_ "FlexKomComment" SG_ 123 MC_ECM_A2 "ECM_A2 Packet";
BA_ "FlexKomSigStartPos" SG_ 299 FUEL_VOLT 39;
BA_ "GenSigSNA" SG_ 157 MC_ECM_A5 "0h";
BA_ "GenSigCycleTime" SG_ 157 MC_ECM_A5 20;
BA_ "FlexKomSigStartValue" SG_ 157 MC_ECM_A5 "FFFFFFFF00000CFFh";
BA_ "FlexKomSigStartPos" SG_ 157 MC_ECM_A5 7;
BA_ "FlexKomSigName" SG_ 157 MC_ECM_A5 "ECM_A5_PKT";
BA_ "FlexKomSigLaenge" SG_ 157 MC_ECM_A5 64;
BA_ "FlexKomSID" SG_ 157 MC_ECM_A5 1821;
BA_ "FlexKomIsMotorola" SG_ 157 MC_ECM_A5 1;
BA_ "FlexKomComment" SG_ 157 MC_ECM_A5 "ECM_A5 Packet";
BA_ "GenSigStartValue" SG_ 53 EngTrqStatic_SEM 8191;
BA_ "GenSigSNA" SG_ 53 EngTrqStatic_SEM "1FFFh";
BA_ "GenSigCycleTime" SG_ 53 EngTrqStatic_SEM 10;
BA_ "FlexKomSigStartValue" SG_ 53 EngTrqStatic_SEM "5FFF1FFF00FF0FFFh";
BA_ "FlexKomSigStartPos" SG_ 53 EngTrqStatic_SEM 7;
BA_ "FlexKomSigName" SG_ 53 EngTrqStatic_SEM "ECM_A3_PKT";
BA_ "FlexKomSigLaenge" SG_ 53 EngTrqStatic_SEM 64;
BA_ "FlexKomSID" SG_ 53 EngTrqStatic_SEM 1369;
BA_ "FlexKomIsMotorola" SG_ 53 EngTrqStatic_SEM 1;
BA_ "FlexKomComment" SG_ 53 EngTrqStatic_SEM "ECM_A3 message packet";
BA_ "GenSigStartValue" SG_ 53 EngMaxRPM 255;
BA_ "GenSigSNA" SG_ 53 EngMaxRPM "FFh";
BA_ "GenSigCycleTime" SG_ 53 EngMaxRPM 10;
BA_ "FlexKomSigStartValue" SG_ 53 EngMaxRPM "5FFF1FFF00FF0FFFh";
BA_ "FlexKomSigStartPos" SG_ 53 EngMaxRPM 7;
BA_ "FlexKomSigName" SG_ 53 EngMaxRPM "ECM_A3_PKT";
BA_ "FlexKomSigLaenge" SG_ 53 EngMaxRPM 64;
BA_ "FlexKomSID" SG_ 53 EngMaxRPM 1369;
BA_ "FlexKomIsMotorola" SG_ 53 EngMaxRPM 1;
BA_ "FlexKomComment" SG_ 53 EngMaxRPM "ECM_A3 message packet";
BA_ "GenSigStartValue" SG_ 53 CRC_ECM_A3 255;
BA_ "GenSigSNA" SG_ 53 CRC_ECM_A3 "FFh";
BA_ "GenSigCycleTime" SG_ 53 CRC_ECM_A3 10;
BA_ "FlexKomSigStartValue" SG_ 53 CRC_ECM_A3 "5FFF1FFF00FF0FFFh";
BA_ "FlexKomSigStartValue" SG_ 124 CRC_ECM_A2_PHEV "FF0000001FFF00FFh";
BA_ "GenSigTimeout_RF_HUB" SG_ 906 VC_Speedometer_Tolerance 10500;
BA_ "GenSigTimeout_IC" SG_ 906 VC_Speedometer_Tolerance 10500;
BA_ "GenSigSNA" SG_ 906 VC_Speedometer_Tolerance "0h";
BA_ "GenSigSendType" SG_ 906 VC_Speedometer_Tolerance 5;
BA_ "GenSigCycleTime" SG_ 906 VC_Speedometer_Tolerance 2000;
BA_ "FlexKomSigStartValue" SG_ 906 VC_Speedometer_Tolerance "0300000000000000h";
BA_ "FlexKomSigStartPos" SG_ 906 VC_Speedometer_Tolerance 7;
BA_ "FlexKomSigName" SG_ 906 VC_Speedometer_Tolerance "VehCfg8_Pkt";
BA_ "FlexKomSigLaenge" SG_ 906 VC_Speedometer_Tolerance 64;
BA_ "FlexKomSID" SG_ 906 VC_Speedometer_Tolerance 2722;
BA_ "FlexKomIsMotorola" SG_ 906 VC_Speedometer_Tolerance 1;
BA_ "FlexKomComment" SG_ 906 VC_Speedometer_Tolerance "Vehicle Configuration 8 Packet";
BA_ "RID" SG_ 319 RsErrIBS3 "5135";
BA_ "GenSigStartValue" SG_ 967 DrvSeatDPSts 2;
BA_ "GenSigSNA" SG_ 967 DrvSeatDPSts "3h";
BA_ "GenSigSendType" SG_ 967 DrvSeatDPSts 5;
BA_ "GenSigCycleTime" SG_ 967 DrvSeatDPSts 200;
BA_ "FlexKomSigStartValue" SG_ 967 DrvSeatDPSts "020000FFh";
BA_ "FlexKomSigStartPos" SG_ 967 DrvSeatDPSts 7;
BA_ "FlexKomSigName" SG_ 967 DrvSeatDPSts "DPDM_A1_PKT";
BA_ "FlexKomSigLaenge" SG_ 967 DrvSeatDPSts 32;
BA_ "FlexKomSID" SG_ 967 DrvSeatDPSts 2682;
BA_ "FlexKomIsMotorola" SG_ 967 DrvSeatDPSts 1;
BA_ "FlexKomComment" SG_ 967 DrvSeatDPSts "DPDM_A1_PKT";
BA_ "GenSigSNA" SG_ 298 MC_12Ah "0h";
BA_ "GenSigCycleTime" SG_ 298 MC_12Ah 100;
BA_ "FlexKomSigStartValue" SG_ 298 MC_12Ah "01FF0000000000FFh";
BA_ "FlexKomSigStartPos" SG_ 298 MC_12Ah 7;
BA_ "FlexKomSigName" SG_ 298 MC_12Ah "HCP_100";
BA_ "FlexKomSigLaenge" SG_ 298 MC_12Ah 64;
BA_ "FlexKomSID" SG_ 298 MC_12Ah 2820;
BA_ "FlexKomIsMotorola" SG_ 298 MC_12Ah 1;
BA_ "FlexKomComment" SG_ 298 MC_12Ah "HCP_100 message packet";
BA_ "RID" SG_ 560 AC_SEL "1154";
BA_ "GenSigSNA" SG_ 560 AC_SEL "0h";
BA_ "GenSigSendType" SG_ 560 AC_SEL 5;
BA_ "GenSigCycleTime" SG_ 560 AC_SEL 500;
BA_ "FlexKomSigStartValue" SG_ 560 AC_SEL "00h";
BA_ "FlexKomSigStartPos" SG_ 560 AC_SEL 1;
BA_ "FlexKomSigName" SG_ 560 AC_SEL "AC_SEL";
BA_ "FlexKomSigLaenge" SG_ 560 AC_SEL 1;
BA_ "FlexKomSID" SG_ 560 AC_SEL 31;
BA_ "FlexKomIsMotorola" SG_ 560 AC_SEL 1;
BA_ "FlexKomComment" SG_ 560 AC_SEL "Customer has selected A/C; [1] = A/C selected; 0 =";
BA_ "RID" SG_ 560 EVAP_TEMP "1096";
BA_ "GenSigSNA" SG_ 560 EVAP_TEMP "FFh";
BA_ "GenSigSendType" SG_ 560 EVAP_TEMP 5;
BA_ "GenSigCycleTime" SG_ 560 EVAP_TEMP 500;
BA_ "FlexKomSigStartValue" SG_ 560 EVAP_TEMP "00h";
BA_ "FlexKomSigStartPos" SG_ 560 EVAP_TEMP 15;
BA_ "FlexKomSigName" SG_ 560 EVAP_TEMP "EVAP_TEMP";
BA_ "FlexKomSigLaenge" SG_ 560 EVAP_TEMP 8;
BA_ "FlexKomSID" SG_ 560 EVAP_TEMP 29;
BA_ "FlexKomIsMotorola" SG_ 560 EVAP_TEMP 1;
BA_ "FlexKomComment" SG_ 560 EVAP_TEMP "AC evaporator temperature";
BA_ "GenSigTimeout_SCCM" SG_ 299 BATT_VOLT 1050;
BA_ "GenSigTimeout_RF_HUB" SG_ 299 BATT_VOLT 1050;
BA_ "GenSigTimeout_ORC" SG_ 299 BATT_VOLT 350;
BA_ "GenSigTimeout_IC" SG_ 299 BATT_VOLT 1050;
BA_ "GenSigTimeout_ESM" SG_ 299 BATT_VOLT 1050;
BA_ "GenSigTimeout_EHPS" SG_ 299 BATT_VOLT 1050;
BA_ "GenSigTimeout_DTCM" SG_ 299 BATT_VOLT 1050;
BA_ "GenSigStartValue" SG_ 299 BATT_VOLT 255;
BA_ "GenSigSNA" SG_ 299 BATT_VOLT "FFh";
BA_ "GenSigCycleTime" SG_ 299 BATT_VOLT 100;
BA_ "FlexKomSigStartValue" SG_ 299 BATT_VOLT "FFh";
BA_ "FlexKomSigStartPos" SG_ 299 BATT_VOLT 55;
BA_ "FlexKomSigName" SG_ 299 BATT_VOLT "BATT_VOLT";
BA_ "FlexKomSigLaenge" SG_ 299 BATT_VOLT 8;
BA_ "FlexKomSID" SG_ 299 BATT_VOLT 839;
BA_ "FlexKomIsMotorola" SG_ 299 BATT_VOLT 1;
BA_ "FlexKomComment" SG_ 299 BATT_VOLT "System voltage";
BA_ "RID" SG_ 299 AMB_TEMP_VOLT "1805";
BA_ "GenSigTimeout_ORC" SG_ 299 AMB_TEMP_VOLT 350;
BA_ "GenSigSNA" SG_ 299 AMB_TEMP_VOLT "0h";
BA_ "GenSigCycleTime" SG_ 299 AMB_TEMP_VOLT 100;
BA_ "FlexKomSigStartValue" SG_ 299 AMB_TEMP_VOLT "FFh";
BA_ "FlexKomSigStartPos" SG_ 299 AMB_TEMP_VOLT 31;
BA_ "FlexKomSigName" SG_ 299 AMB_TEMP_VOLT "AMB_TEMP_VOLT";
BA_ "FlexKomSigLaenge" SG_ 299 AMB_TEMP_VOLT 8;
BA_ "FlexKomSID" SG_ 299 AMB_TEMP_VOLT 1201;
BA_ "FlexKomIsMotorola" SG_ 299 AMB_TEMP_VOLT 1;
BA_ "FlexKomComment" SG_ 299 AMB_TEMP_VOLT "Ambient Temp Sensor A/D Voltage";
BA_ "GenSigTimeout_TCM" SG_ 119 CmdIgnStat 210;
BA_ "GenSigTimeout_SCCM" SG_ 119 CmdIgnStat 210;
BA_ "GenSigTimeout_PTS" SG_ 119 CmdIgnStat 210;
BA_ "GenSigTimeout_ORC" SG_ 119 CmdIgnStat 70;
BA_ "GenSigTimeout_IC" SG_ 119 CmdIgnStat 210;
BA_ "GenSigTimeout_ESM" SG_ 119 CmdIgnStat 310;
BA_ "GenSigTimeout_ESL" SG_ 119 CmdIgnStat 110;
BA_ "GenSigTimeout_EHPS" SG_ 119 CmdIgnStat 210;
BA_ "GenSigTimeout_DTCM" SG_ 119 CmdIgnStat 210;
BA_ "GenSigTimeout_ASBS" SG_ 119 CmdIgnStat 410;
BA_ "GenSigTimeout_AHLM" SG_ 119 CmdIgnStat 210;
BA_ "GenSigSNA" SG_ 119 CmdIgnStat "7h";
BA_ "GenSigCycleTime" SG_ 119 CmdIgnStat 20;
BA_ "FlexKomSigStartValue" SG_ 119 CmdIgnStat "0000h";
BA_ "FlexKomSigStartPos" SG_ 119 CmdIgnStat 7;
BA_ "FlexKomSigName" SG_ 119 CmdIgnStat "VehStart_PKT";
BA_ "FlexKomSigLaenge" SG_ 119 CmdIgnStat 16;
BA_ "FlexKomSID" SG_ 119 CmdIgnStat 880;
BA_ "FlexKomIsMotorola" SG_ 119 CmdIgnStat 1;
BA_ "FlexKomComment" SG_ 119 CmdIgnStat "Vehicle start packet";
BA_ "GenSigTimeout_IC" SG_ 657 FT_FOG_RQ 10500;
BA_ "GenSigSNA" SG_ 657 FT_FOG_RQ "0h";
BA_ "GenSigSendType" SG_ 657 FT_FOG_RQ 5;
BA_ "GenSigCycleTime" SG_ 657 FT_FOG_RQ 1000;
BA_ "FlexKomSigStartValue" SG_ 657 FT_FOG_RQ "00h";
BA_ "FlexKomSigStartPos" SG_ 657 FT_FOG_RQ 2;
BA_ "FlexKomSigName" SG_ 657 FT_FOG_RQ "FT_FOG_RQ";
BA_ "FlexKomSigLaenge" SG_ 657 FT_FOG_RQ 1;
BA_ "FlexKomSID" SG_ 657 FT_FOG_RQ 758;
BA_ "FlexKomIsMotorola" SG_ 657 FT_FOG_RQ 1;
BA_ "FlexKomComment" SG_ 657 FT_FOG_RQ "Front fog request; off=[0], on=[1]";
BA_ "GenSigTimeout_TCM" SG_ 56 MotorB_Speed 105;
BA_ "GenSigTimeout_ORC" SG_ 56 MotorB_Speed 35;
BA_ "GenSigTimeout_IC" SG_ 56 MotorB_Speed 105;
BA_ "GenSigTimeout_ESM" SG_ 56 MotorB_Speed 105;
BA_ "GenSigTimeout_EHPS" SG_ 56 MotorB_Speed 105;
BA_ "GenSigTimeout_DTCM" SG_ 56 MotorB_Speed 105;
BA_ "GenSigTimeout_CBC" SG_ 56 MotorB_Speed 105;
BA_ "GenSigStartValue" SG_ 56 MotorB_Speed 65534;
BA_ "GenSigSNA" SG_ 56 MotorB_Speed "FFFFh";
BA_ "GenSigCycleTime" SG_ 56 MotorB_Speed 10;
BA_ "FlexKomSigStartValue" SG_ 56 MotorB_Speed "1FFF1FFFFFFE00FFh";
BA_ "FlexKomSigStartPos" SG_ 56 MotorB_Speed 7;
BA_ "FlexKomSigName" SG_ 56 MotorB_Speed "HCP_A3_PKT";
BA_ "FlexKomSigLaenge" SG_ 56 MotorB_Speed 64;
BA_ "FlexKomSID" SG_ 56 MotorB_Speed 2995;
BA_ "FlexKomIsMotorola" SG_ 56 MotorB_Speed 1;
BA_ "FlexKomComment" SG_ 56 MotorB_Speed "HCP_A3_PKT";
BA_ "GenSigSNA" SG_ 56 MC_HCP_A3 "0h";
BA_ "GenSigCycleTime" SG_ 56 MC_HCP_A3 10;
BA_ "FlexKomSigStartValue" SG_ 56 MC_HCP_A3 "1FFF1FFFFFFE00FFh";
BA_ "FlexKomSigStartPos" SG_ 56 MC_HCP_A3 7;
BA_ "FlexKomSigName" SG_ 56 MC_HCP_A3 "HCP_A3_PKT";
BA_ "FlexKomSigLaenge" SG_ 56 MC_HCP_A3 64;
BA_ "FlexKomSID" SG_ 56 MC_HCP_A3 2995;
BA_ "FlexKomIsMotorola" SG_ 56 MC_HCP_A3 1;
BA_ "FlexKomComment" SG_ 56 MC_HCP_A3 "HCP_A3_PKT";
BA_ "GenSigSNA" SG_ 54 MC_HCP_A2 "0h";
BA_ "GenSigCycleTime" SG_ 54 MC_HCP_A2 10;
BA_ "FlexKomSigStartValue" SG_ 54 MC_HCP_A2 "1FFF1FFF1FFF00FFh";
BA_ "FlexKomSigStartPos" SG_ 54 MC_HCP_A2 7;
BA_ "FlexKomSigName" SG_ 54 MC_HCP_A2 "HCP_A2_PKT";
BA_ "FlexKomSigLaenge" SG_ 54 MC_HCP_A2 64;
BA_ "FlexKomSID" SG_ 54 MC_HCP_A2 2994;
BA_ "FlexKomIsMotorola" SG_ 54 MC_HCP_A2 1;
BA_ "FlexKomComment" SG_ 54 MC_HCP_A2 "HCP_A2_PKT";
BA_ "GenSigStartValue" SG_ 40 CRC_HCP_A1 255;
BA_ "GenSigSNA" SG_ 40 CRC_HCP_A1 "FFh";
BA_ "GenSigCycleTime" SG_ 40 CRC_HCP_A1 10;
BA_ "FlexKomSigStartValue" SG_ 40 CRC_HCP_A1 "1FFF1FFF1FFF00FFh";
BA_ "FlexKomSigStartPos" SG_ 40 CRC_HCP_A1 7;
BA_ "FlexKomSigName" SG_ 40 CRC_HCP_A1 "HCP_A1_PKT";
BA_ "FlexKomSigLaenge" SG_ 40 CRC_HCP_A1 64;
BA_ "FlexKomSID" SG_ 40 CRC_HCP_A1 2990;
BA_ "FlexKomIsMotorola" SG_ 40 CRC_HCP_A1 1;
BA_ "FlexKomComment" SG_ 40 CRC_HCP_A1 "HCP_A1_PKT";
BA_ "GenSigStartValue" SG_ 145 DrvLnTrqRq 511;
BA_ "GenSigSNA" SG_ 145 DrvLnTrqRq "1FFh";
BA_ "GenSigCycleTime" SG_ 145 DrvLnTrqRq 20;
BA_ "FlexKomSigStartValue" SG_ 145 DrvLnTrqRq "01FF7F00000000FFh";
BA_ "FlexKomSigStartPos" SG_ 145 DrvLnTrqRq 7;
BA_ "FlexKomSigName" SG_ 145 DrvLnTrqRq "DTCM_A2_PKT";
BA_ "FlexKomSigLaenge" SG_ 145 DrvLnTrqRq 64;
BA_ "FlexKomSID" SG_ 145 DrvLnTrqRq 1520;
BA_ "FlexKomIsMotorola" SG_ 145 DrvLnTrqRq 1;
BA_ "FlexKomComment" SG_ 145 DrvLnTrqRq "DTCM_A2_PKT";
BA_ "GenSigSNA" SG_ 141 TCASERANGESTATUS "3h";
BA_ "GenSigCycleTime" SG_ 141 TCASERANGESTATUS 20;
BA_ "FlexKomSigStartValue" SG_ 141 TCASERANGESTATUS "CEC0FFFFFFFFFFFFh";
BA_ "FlexKomSigStartPos" SG_ 141 TCASERANGESTATUS 7;
BA_ "FlexKomSigName" SG_ 141 TCASERANGESTATUS "DTCM_A1_PKT";
BA_ "FlexKomSigLaenge" SG_ 141 TCASERANGESTATUS 64;
BA_ "FlexKomSID" SG_ 141 TCASERANGESTATUS 807;
BA_ "GenSigSNA" SG_ 833 GPF_T1_Status "0h";
BA_ "GenSigCycleTime" SG_ 833 GPF_T1_Status 500;
BA_ "FlexKomSigStartValue" SG_ 833 GPF_T1_Status "0019001900000000h";
BA_ "FlexKomSigStartPos" SG_ 833 GPF_T1_Status 7;
BA_ "FlexKomSigName" SG_ 833 GPF_T1_Status "GPF_DATA_1_PKT";
BA_ "FlexKomSigLaenge" SG_ 833 GPF_T1_Status 64;
BA_ "FlexKomSID" SG_ 833 GPF_T1_Status 2850;
BA_ "FlexKomIsMotorola" SG_ 833 GPF_T1_Status 1;
BA_ "FlexKomComment" SG_ 833 GPF_T1_Status "GPF_DATA_1 packet";
BA_ "GenSigSNA" SG_ 179 Trans_ESS_Inhibit "0h";
BA_ "GenSigCycleTime" SG_ 179 Trans_ESS_Inhibit 20;
BA_ "FlexKomSigStartValue" SG_ 179 Trans_ESS_Inhibit "0000FFFF000000FFh";
BA_ "FlexKomSigStartPos" SG_ 179 Trans_ESS_Inhibit 7;
BA_ "FlexKomSigName" SG_ 179 Trans_ESS_Inhibit "TCM_ENG_SPD_PKT";
BA_ "FlexKomSigLaenge" SG_ 179 Trans_ESS_Inhibit 64;
BA_ "FlexKomSID" SG_ 179 Trans_ESS_Inhibit 2772;
BA_ "FlexKomIsMotorola" SG_ 179 Trans_ESS_Inhibit 1;
BA_ "FlexKomComment" SG_ 179 Trans_ESS_Inhibit "TCM Engine Speed Packet";
BA_ "GenSigSNA" SG_ 179 GearSwitchActiveSts_2 "0h";
BA_ "GenSigCycleTime" SG_ 179 GearSwitchActiveSts_2 20;
BA_ "FlexKomSigStartValue" SG_ 179 GearSwitchActiveSts_2 "0000FFFF000000FFh";
BA_ "FlexKomSigStartPos" SG_ 179 GearSwitchActiveSts_2 7;
BA_ "FlexKomSigName" SG_ 179 GearSwitchActiveSts_2 "TCM_ENG_SPD_PKT";
BA_ "FlexKomSigLaenge" SG_ 179 GearSwitchActiveSts_2 64;
BA_ "FlexKomSID" SG_ 179 GearSwitchActiveSts_2 2772;
BA_ "FlexKomIsMotorola" SG_ 179 GearSwitchActiveSts_2 1;
BA_ "FlexKomComment" SG_ 179 GearSwitchActiveSts_2 "TCM Engine Speed Packet";
BA_ "GenSigStartValue" SG_ 179 OutputSpeed_2 65535;
BA_ "GenSigSNA" SG_ 179 OutputSpeed_2 "FFFFh";
BA_ "GenSigCycleTime" SG_ 179 OutputSpeed_2 20;
BA_ "FlexKomSigStartValue" SG_ 179 OutputSpeed_2 "0000FFFF000000FFh";
BA_ "FlexKomSigStartPos" SG_ 179 OutputSpeed_2 7;
BA_ "FlexKomSigName" SG_ 179 OutputSpeed_2 "TCM_ENG_SPD_PKT";
BA_ "FlexKomSigLaenge" SG_ 179 OutputSpeed_2 64;
BA_ "FlexKomSID" SG_ 179 OutputSpeed_2 2772;
BA_ "FlexKomIsMotorola" SG_ 179 OutputSpeed_2 1;
BA_ "FlexKomComment" SG_ 179 OutputSpeed_2 "TCM Engine Speed Packet";
BA_ "FlexKomIsMotorola" SG_ 157 Analog_Clutch 1;
BA_ "FlexKomComment" SG_ 157 Analog_Clutch "ECM_A5 Packet";
BA_ "GenSigTimeout_ORC" SG_ 153 DAS_ACCEL_Rq 70;
BA_ "GenSigStartValue" SG_ 153 DAS_ACCEL_Rq 3275;
BA_ "GenSigSNA" SG_ 153 DAS_ACCEL_Rq "FFFh";
BA_ "GenSigCycleTime" SG_ 153 DAS_ACCEL_Rq 20;
BA_ "FlexKomSigStartValue" SG_ 153 DAS_ACCEL_Rq "1FFF0CCB000000FFh";
BA_ "FlexKomSigStartPos" SG_ 153 DAS_ACCEL_Rq 7;
BA_ "FlexKomSigName" SG_ 153 DAS_ACCEL_Rq "DAS_A3_PKT";
BA_ "FlexKomSigLaenge" SG_ 153 DAS_ACCEL_Rq 64;
BA_ "FlexKomSID" SG_ 153 DAS_ACCEL_Rq 1043;
BA_ "FlexKomIsMotorola" SG_ 153 DAS_ACCEL_Rq 1;
BA_ "FlexKomComment" SG_ 153 DAS_ACCEL_Rq "DAS_A3_PKT";
BA_ "FlexKomSigName" SG_ 145 MC_DTCM_A2 "DTCM_A2_PKT";
BA_ "FlexKomSigLaenge" SG_ 145 MC_DTCM_A2 64;
BA_ "FlexKomSID" SG_ 145 MC_DTCM_A2 1520;
BA_ "FlexKomIsMotorola" SG_ 145 MC_DTCM_A2 1;
BA_ "FlexKomComment" SG_ 145 MC_DTCM_A2 "DTCM_A2_PKT";
BA_ "GenSigSNA" SG_ 167 BrkPrss_Two "0h";
BA_ "GenSigCycleTime" SG_ 167 BrkPrss_Two 20;
BA_ "FlexKomSigStartValue" SG_ 167 BrkPrss_Two "04000000C00000FFh";
BA_ "FlexKomSigStartPos" SG_ 167 BrkPrss_Two 7;
BA_ "FlexKomSigName" SG_ 167 BrkPrss_Two "DST_TOC";
BA_ "FlexKomSigLaenge" SG_ 167 BrkPrss_Two 64;
BA_ "FlexKomSID" SG_ 167 BrkPrss_Two 1909;
BA_ "FlexKomIsMotorola" SG_ 167 BrkPrss_Two 1;
BA_ "FlexKomComment" SG_ 167 BrkPrss_Two "DST_TOC";
BA_ "GenSigSNA" SG_ 123 EngTrq_Enbl_Rq_AS "0h";
BA_ "GenSigCycleTime" SG_ 123 EngTrq_Enbl_Rq_AS 20;
BA_ "FlexKomSigStartValue" SG_ 123 EngTrq_Enbl_Rq_AS "1FFFFF1FFF00FFh";
BA_ "FlexKomSigStartPos" SG_ 123 EngTrq_Enbl_Rq_AS 7;
BA_ "FlexKomSigName" SG_ 123 EngTrq_Enbl_Rq_AS "ECM_A2_PKT";
BA_ "FlexKomSigLaenge" SG_ 123 EngTrq_Enbl_Rq_AS 56;
BA_ "FlexKomSID" SG_ 123 EngTrq_Enbl_Rq_AS 455;
BA_ "FlexKomIsMotorola" SG_ 123 EngTrq_Enbl_Rq_AS 1;
BA_ "FlexKomComment" SG_ 123 EngTrq_Enbl_Rq_AS "ECM_A2 Packet";
BA_ "RID" SG_ 123 AccelPdlPosn "5036";
BA_ "GenSigTimeout_TCM" SG_ 123 AccelPdlPosn 210;
BA_ "GenSigTimeout_ETM" SG_ 123 AccelPdlPosn 210;
BA_ "GenSigTimeout_DTCM" SG_ 123 AccelPdlPosn 210;
BA_ "GenSigStartValue" SG_ 123 AccelPdlPosn 255;
BA_ "GenSigSNA" SG_ 123 AccelPdlPosn "FFh";
BA_ "GenSigCycleTime" SG_ 123 AccelPdlPosn 20;
BA_ "FlexKomSigStartValue" SG_ 123 AccelPdlPosn "1FFFFF1FFF00FFh";
BA_ "FlexKomSigStartPos" SG_ 123 AccelPdlPosn 7;
BA_ "FlexKomSigName" SG_ 123 AccelPdlPosn "ECM_A2_PKT";
BA_ "FlexKomSigLaenge" SG_ 123 AccelPdlPosn 56;
BA_ "FlexKomSID" SG_ 123 AccelPdlPosn 455;
BA_ "FlexKomIsMotorola" SG_ 123 AccelPdlPosn 1;
BA_ "FlexKomComment" SG_ 123 AccelPdlPosn "ECM_A2 Packet";
BA_ "GenSigStartValue" SG_ 123 CRC_ECM_A2 255;
BA_ "GenSigSNA" SG_ 123 CRC_ECM_A2 "FFh";
BA_ "GenSigCycleTime" SG_ 123 CRC_ECM_A2 20;
BA_ "FlexKomSigStartValue" SG_ 123 CRC_ECM_A2 "1FFFFF1FFF00FFh";
BA_ "FlexKomSigStartPos" SG_ 123 CRC_ECM_A2 7;
BA_ "FlexKomSigName" SG_ 123 CRC_ECM_A2 "ECM_A2_PKT";
BA_ "FlexKomSigLaenge" SG_ 123 CRC_ECM_A2 56;
BA_ "FlexKomSID" SG_ 123 CRC_ECM_A2 455;
BA_ "FlexKomIsMotorola" SG_ 123 CRC_ECM_A2 1;
BA_ "FlexKomComment" SG_ 123 CRC_ECM_A2 "ECM_A2 Packet";
BA_ "GenSigTimeout_TCM" SG_ 123 CRUISE_OVERRIDE 210;
BA_ "GenSigTimeout_IC" SG_ 123 CRUISE_OVERRIDE 210;
BA_ "GenSigSNA" SG_ 123 CRUISE_OVERRIDE "0h";
BA_ "GenSigCycleTime" SG_ 123 CRUISE_OVERRIDE 20;
BA_ "FlexKomSigStartValue" SG_ 123 CRUISE_OVERRIDE "1FFFFF1FFF00FFh";
BA_ "FlexKomSigStartPos" SG_ 123 CRUISE_OVERRIDE 7;
BA_ "FlexKomSigName" SG_ 123 CRUISE_OVERRIDE "ECM_A2_PKT";
BA_ "FlexKomSigLaenge" SG_ 123 CRUISE_OVERRIDE 56;
BA_ "FlexKomSID" SG_ 123 CRUISE_OVERRIDE 455;
BA_ "FlexKomIsMotorola" SG_ 123 CRUISE_OVERRIDE 1;
BA_ "FlexKomComment" SG_ 123 CRUISE_OVERRIDE "ECM_A2 Packet";
BA_ "RID" SG_ 37 EngTrqStatic "2184";
BA_ "GenSigTimeout_TCM" SG_ 37 EngTrqStatic 105;
BA_ "GenSigTimeout_IC" SG_ 37 EngTrqStatic 105;
BA_ "GenSigTimeout_DTCM" SG_ 37 EngTrqStatic 105;
BA_ "GenSigTimeout_CBC" SG_ 37 EngTrqStatic 105;
BA_ "GenSigStartValue" SG_ 37 EngTrqStatic 8191;
BA_ "GenSigSNA" SG_ 37 EngTrqStatic "1FFFh";
BA_ "GenSigCycleTime" SG_ 37 EngTrqStatic 10;
BA_ "FlexKomSigStartValue" SG_ 37 EngTrqStatic "FFFF1FFF1FFF00FFh";
BA_ "FlexKomSigStartPos" SG_ 37 EngTrqStatic 7;
BA_ "FlexKomSigName" SG_ 37 EngTrqStatic "ECM_A1_PKT";
BA_ "FlexKomSigLaenge" SG_ 37 EngTrqStatic 64;
BA_ "FlexKomSID" SG_ 37 EngTrqStatic 446;
BA_ "FlexKomIsMotorola" SG_ 37 EngTrqStatic 1;
BA_ "FlexKomComment" SG_ 37 EngTrqStatic "ECM_A1 Packet";
BA_ "GenSigStartValue" SG_ 37 CRC_ECM_A1 255;
BA_ "GenSigSNA" SG_ 37 CRC_ECM_A1 "FFh";
BA_ "FlexKomSigStartPos" SG_ 181 EngineStaticTorque 7;
BA_ "FlexKomSigName" SG_ 181 EngineStaticTorque "ECM_ENG_TRQ2_PKT";
BA_ "FlexKomSigLaenge" SG_ 181 EngineStaticTorque 64;
BA_ "FlexKomSID" SG_ 181 EngineStaticTorque 2773;
BA_ "FlexKomIsMotorola" SG_ 181 EngineStaticTorque 1;
BA_ "FlexKomComment" SG_ 181 EngineStaticTorque "ECM_ENG_TRQ2_PKT";
BA_ "GenSigSNA" SG_ 179 MC_TCM_ENG_SPD "0h";
BA_ "GenSigCycleTime" SG_ 179 MC_TCM_ENG_SPD 20;
BA_ "FlexKomSigStartValue" SG_ 179 MC_TCM_ENG_SPD "0000FFFF000000FFh";
BA_ "FlexKomSigStartPos" SG_ 179 MC_TCM_ENG_SPD 7;
BA_ "FlexKomSigName" SG_ 179 MC_TCM_ENG_SPD "TCM_ENG_SPD_PKT";
BA_ "FlexKomSigLaenge" SG_ 179 MC_TCM_ENG_SPD 64;
BA_ "FlexKomSID" SG_ 179 MC_TCM_ENG_SPD 2772;
BA_ "FlexKomIsMotorola" SG_ 179 MC_TCM_ENG_SPD 1;
BA_ "FlexKomComment" SG_ 179 MC_TCM_ENG_SPD "TCM Engine Speed Packet";
BA_ "GenSigTimeout_IC" SG_ 657 R_FOG_RQ 10500;
BA_ "GenSigSNA" SG_ 657 R_FOG_RQ "0h";
BA_ "GenSigSendType" SG_ 657 R_FOG_RQ 5;
BA_ "GenSigCycleTime" SG_ 657 R_FOG_RQ 1000;
BA_ "FlexKomSigStartValue" SG_ 657 R_FOG_RQ "00h";
BA_ "FlexKomSigStartPos" SG_ 657 R_FOG_RQ 3;
BA_ "FlexKomSigName" SG_ 657 R_FOG_RQ "R_FOG_RQ";
BA_ "FlexKomSigLaenge" SG_ 657 R_FOG_RQ 1;
BA_ "FlexKomSID" SG_ 657 R_FOG_RQ 427;
BA_ "FlexKomIsMotorola" SG_ 657 R_FOG_RQ 1;
BA_ "FlexKomComment" SG_ 657 R_FOG_RQ "Rear fog request; [0] = off, [1] = on";
BA_ "GenSigTimeout_IC" SG_ 657 HIBEAM_ON 10500;
BA_ "GenSigSNA" SG_ 657 HIBEAM_ON "0h";
BA_ "GenSigSendType" SG_ 657 HIBEAM_ON 5;
BA_ "GenSigCycleTime" SG_ 657 HIBEAM_ON 1000;
BA_ "FlexKomSigStartValue" SG_ 657 HIBEAM_ON "00h";
BA_ "FlexKomSigStartPos" SG_ 657 HIBEAM_ON 58;
BA_ "FlexKomSigName" SG_ 657 HIBEAM_ON "HIBEAM_ON";
BA_ "FlexKomSigLaenge" SG_ 657 HIBEAM_ON 1;
BA_ "FlexKomSID" SG_ 657 HIBEAM_ON 884;
BA_ "FlexKomIsMotorola" SG_ 657 HIBEAM_ON 1;
BA_ "FlexKomComment" SG_ 657 HIBEAM_ON "High beam is on; off=[0], on=[1]";
BA_ "FlexKomIsMotorola" SG_ 834 N_PDU_342 1;
BA_ "FlexKomComment" SG_ 834 N_PDU_342 "GLIWA_T1_TX";
BA_ "GenSigSNA" SG_ 34 CRUISE_OVERRIDE_PT "0h";
BA_ "GenSigCycleTime" SG_ 34 CRUISE_OVERRIDE_PT 10;
BA_ "FlexKomSigStartValue" SG_ 34 CRUISE_OVERRIDE_PT "FFFFFF01F40000FFh";
BA_ "FlexKomSigStartPos" SG_ 34 CRUISE_OVERRIDE_PT 7;
BA_ "FlexKomSigName" SG_ 34 CRUISE_OVERRIDE_PT "PT_SYSTEM_1_PKT";
BA_ "FlexKomSigLaenge" SG_ 34 CRUISE_OVERRIDE_PT 64;
BA_ "FlexKomSID" SG_ 34 CRUISE_OVERRIDE_PT 3370;
BA_ "FlexKomIsMotorola" SG_ 34 CRUISE_OVERRIDE_PT 1;
BA_ "FlexKomComment" SG_ 34 CRUISE_OVERRIDE_PT "PT_SYSTEM_1_PKT Packet";
BA_ "GenSigSNA" SG_ 124 LV12PwrFreeRq_PHEV "0h";
BA_ "GenSigCycleTime" SG_ 124 LV12PwrFreeRq_PHEV 20;
BA_ "FlexKomSigStartValue" SG_ 124 LV12PwrFreeRq_PHEV "FF0000001FFF00FFh";
BA_ "FlexKomSigStartPos" SG_ 124 LV12PwrFreeRq_PHEV 7;
BA_ "FlexKomSigName" SG_ 124 LV12PwrFreeRq_PHEV "ECM_A2_PHEV_PKT";
BA_ "FlexKomSigLaenge" SG_ 124 LV12PwrFreeRq_PHEV 64;
BA_ "FlexKomSID" SG_ 124 LV12PwrFreeRq_PHEV 2991;
BA_ "FlexKomIsMotorola" SG_ 124 LV12PwrFreeRq_PHEV 1;
BA_ "FlexKomComment" SG_ 124 LV12PwrFreeRq_PHEV "ECM_A2_PHEV_PKT";
BA_ "GenSigSNA" SG_ 124 EngTrq_Enbl_Rq_ESC_PHEV "0h";
BA_ "GenSigCycleTime" SG_ 124 EngTrq_Enbl_Rq_ESC_PHEV 20;
BA_ "FlexKomSigStartValue" SG_ 124 EngTrq_Enbl_Rq_ESC_PHEV "FF0000001FFF00FFh";
BA_ "FlexKomSigStartPos" SG_ 124 EngTrq_Enbl_Rq_ESC_PHEV 7;
BA_ "FlexKomSigName" SG_ 124 EngTrq_Enbl_Rq_ESC_PHEV "ECM_A2_PHEV_PKT";
BA_ "FlexKomSigLaenge" SG_ 124 EngTrq_Enbl_Rq_ESC_PHEV 64;
BA_ "FlexKomSID" SG_ 124 EngTrq_Enbl_Rq_ESC_PHEV 2991;
BA_ "FlexKomIsMotorola" SG_ 124 EngTrq_Enbl_Rq_ESC_PHEV 1;
BA_ "FlexKomComment" SG_ 124 EngTrq_Enbl_Rq_ESC_PHEV "ECM_A2_PHEV_PKT";
BA_ "GenSigTimeout_TCM" SG_ 124 ECM_LHOM_PHEV 210;
BA_ "GenSigSNA" SG_ 124 ECM_LHOM_PHEV "0h";
BA_ "GenSigCycleTime" SG_ 124 ECM_LHOM_PHEV 20;
BA_ "FlexKomSigStartValue" SG_ 124 ECM_LHOM_PHEV "FF0000001FFF00FFh";
BA_ "FlexKomSigStartPos" SG_ 124 ECM_LHOM_PHEV 7;
BA_ "FlexKomSigName" SG_ 124 ECM_LHOM_PHEV "ECM_A2_PHEV_PKT";
BA_ "FlexKomSigLaenge" SG_ 124 ECM_LHOM_PHEV 64;
BA_ "FlexKomSID" SG_ 124 ECM_LHOM_PHEV 2991;
BA_ "FlexKomIsMotorola" SG_ 124 ECM_LHOM_PHEV 1;
BA_ "FlexKomComment" SG_ 124 ECM_LHOM_PHEV "ECM_A2_PHEV_PKT";
BA_ "GenSigSNA" SG_ 38 MC_ECM_A1_PHEV "0h";
BA_ "GenSigCycleTime" SG_ 38 MC_ECM_A1_PHEV 10;
BA_ "FlexKomSigStartValue" SG_ 38 MC_ECM_A1_PHEV "FFFFFF00201E00FFh";
BA_ "FlexKomSigStartPos" SG_ 38 MC_ECM_A1_PHEV 7;
BA_ "FlexKomSigName" SG_ 38 MC_ECM_A1_PHEV "ECM_A1_PHEV_PKT";
BA_ "FlexKomSigLaenge" SG_ 38 MC_ECM_A1_PHEV 64;
BA_ "FlexKomSID" SG_ 38 MC_ECM_A1_PHEV 2992;
BA_ "FlexKomIsMotorola" SG_ 38 MC_ECM_A1_PHEV 1;
BA_ "FlexKomComment" SG_ 38 MC_ECM_A1_PHEV "ECM_A1_PHEV_PKT";
BA_ "GenSigStartValue" SG_ 38 EngMaxRPM_PHEV 255;
BA_ "GenSigSNA" SG_ 38 EngMaxRPM_PHEV "FFh";
BA_ "GenSigCycleTime" SG_ 38 EngMaxRPM_PHEV 10;
BA_ "FlexKomSigStartValue" SG_ 38 EngMaxRPM_PHEV "FFFFFF00201E00FFh";
BA_ "FlexKomSigStartPos" SG_ 38 EngMaxRPM_PHEV 7;
BA_ "FlexKomSigName" SG_ 38 EngMaxRPM_PHEV "ECM_A1_PHEV_PKT";
BA_ "FlexKomSigLaenge" SG_ 38 EngMaxRPM_PHEV 64;
BA_ "FlexKomSID" SG_ 38 EngMaxRPM_PHEV 2992;
BA_ "FlexKomIsMotorola" SG_ 38 EngMaxRPM_PHEV 1;
BA_ "FlexKomComment" SG_ 38 EngMaxRPM_PHEV "ECM_A1_PHEV_PKT";
BA_ "GenSigSNA" SG_ 819 EngActiveTimer_OBD "FFFFh";
BA_ "GenSigSendType" SG_ 819 EngActiveTimer_OBD 5;
BA_ "GenSigCycleTime" SG_ 819 EngActiveTimer_OBD 1000;
BA_ "FlexKomSigStartValue" SG_ 819 EngActiveTimer_OBD "00000000000000FFh";
BA_ "FlexKomSigStartPos" SG_ 819 EngActiveTimer_OBD 7;
BA_ "FlexKomSigName" SG_ 819 EngActiveTimer_OBD "ECM_A6_PKT1";
BA_ "FlexKomSigLaenge" SG_ 819 EngActiveTimer_OBD 64;
BA_ "FlexKomSID" SG_ 819 EngActiveTimer_OBD 3093;
BA_ "FlexKomIsMotorola" SG_ 819 EngActiveTimer_OBD 1;
BA_ "FlexKomComment" SG_ 819 EngActiveTimer_OBD "ECM_A6 Packet";
BA_ "GenSigSNA" SG_ 119 StartRelayBCMSts "0h";
BA_ "GenSigCycleTime" SG_ 119 StartRelayBCMSts 20;
BA_ "FlexKomSigStartValue" SG_ 119 StartRelayBCMSts "00h";
BA_ "FlexKomSigStartPos" SG_ 119 StartRelayBCMSts 13;
BA_ "FlexKomSigName" SG_ 119 StartRelayBCMSts "StartRelayBCMSts";
BA_ "FlexKomSigLaenge" SG_ 119 StartRelayBCMSts 1;
BA_ "FlexKomSID" SG_ 119 StartRelayBCMSts 1526;
BA_ "FlexKomIsMotorola" SG_ 119 StartRelayBCMSts 1;
BA_ "FlexKomComment" SG_ 119 StartRelayBCMSts "CBC starter relay status; [1] = ON";
BA_ "GenSigStartValue" SG_ 54 SumTrqTgt_SEM 8191;
BA_ "GenSigSNA" SG_ 54 SumTrqTgt_SEM "1FFFh";
BA_ "GenSigCycleTime" SG_ 54 SumTrqTgt_SEM 10;
BA_ "FlexKomSigStartValue" SG_ 54 SumTrqTgt_SEM "1FFF1FFF1FFF00FFh";
BA_ "FlexKomSigStartPos" SG_ 54 SumTrqTgt_SEM 7;
BA_ "FlexKomSigName" SG_ 54 SumTrqTgt_SEM "HCP_A2_PKT";
BA_ "FlexKomSigLaenge" SG_ 54 SumTrqTgt_SEM 64;
BA_ "FlexKomSID" SG_ 54 SumTrqTgt_SEM 2994;
BA_ "FlexKomIsMotorola" SG_ 54 SumTrqTgt_SEM 1;
BA_ "FlexKomComment" SG_ 54 SumTrqTgt_SEM "HCP_A2_PKT";
BA_ "FlexKomSigLaenge" SG_ 117 MC_10Eh 64;
BA_ "GenSigSNA" SG_ 967 MC_DPDM_A1 "0h";
BA_ "GenSigSendType" SG_ 967 MC_DPDM_A1 5;
BA_ "GenSigCycleTime" SG_ 967 MC_DPDM_A1 200;
BA_ "FlexKomSigStartValue" SG_ 967 MC_DPDM_A1 "020000FFh";
BA_ "FlexKomSigStartPos" SG_ 967 MC_DPDM_A1 7;
BA_ "FlexKomSigName" SG_ 967 MC_DPDM_A1 "DPDM_A1_PKT";
BA_ "FlexKomSigLaenge" SG_ 967 MC_DPDM_A1 32;
BA_ "FlexKomSID" SG_ 967 MC_DPDM_A1 2682;
BA_ "FlexKomIsMotorola" SG_ 967 MC_DPDM_A1 1;
BA_ "FlexKomComment" SG_ 967 MC_DPDM_A1 "DPDM_A1_PKT";
BA_ "GenSigStartValue" SG_ 967 CRC_DPDM_A1 255;
BA_ "GenSigSNA" SG_ 967 CRC_DPDM_A1 "FFh";
BA_ "GenSigSendType" SG_ 967 CRC_DPDM_A1 5;
BA_ "GenSigCycleTime" SG_ 967 CRC_DPDM_A1 200;
BA_ "FlexKomSigStartValue" SG_ 967 CRC_DPDM_A1 "020000FFh";
BA_ "FlexKomSigStartPos" SG_ 967 CRC_DPDM_A1 7;
BA_ "FlexKomSigName" SG_ 967 CRC_DPDM_A1 "DPDM_A1_PKT";
BA_ "FlexKomSigLaenge" SG_ 967 CRC_DPDM_A1 32;
BA_ "FlexKomSID" SG_ 967 CRC_DPDM_A1 2682;
BA_ "FlexKomIsMotorola" SG_ 967 CRC_DPDM_A1 1;
BA_ "FlexKomComment" SG_ 967 CRC_DPDM_A1 "DPDM_A1_PKT";
BA_ "FlexKomSigLaenge" SG_ 657 PTC_REL1_STAT 6;
BA_ "FlexKomSID" SG_ 657 PTC_REL1_STAT 859;
BA_ "FlexKomIsMotorola" SG_ 657 PTC_REL1_STAT 1;
BA_ "FlexKomComment" SG_ 657 PTC_REL1_STAT "PTC relays status";
BA_ "GenSigStartValue" SG_ 155 DriverDoorAjarXtionSts 3;
BA_ "GenSigSNA" SG_ 155 DriverDoorAjarXtionSts "3h";
BA_ "GenSigCycleTime" SG_ 155 DriverDoorAjarXtionSts 20;
BA_ "FlexKomSigStartValue" SG_ 155 DriverDoorAjarXtionSts "3FFF0C00000000FFh";
BA_ "FlexKomSigStartPos" SG_ 155 DriverDoorAjarXtionSts 7;
BA_ "FlexKomSigName" SG_ 155 DriverDoorAjarXtionSts "CBC_PT6_Pkt";
BA_ "FlexKomSigLaenge" SG_ 155 DriverDoorAjarXtionSts 64;
BA_ "FlexKomSID" SG_ 155 DriverDoorAjarXtionSts 1943;
BA_ "FlexKomIsMotorola" SG_ 155 DriverDoorAjarXtionSts 1;
BA_ "FlexKomComment" SG_ 155 DriverDoorAjarXtionSts "CBC_PT6 message packet";
BA_ "GenSigSNA" SG_ 155 DriverDoor2AjarRawValSts "Fh";
BA_ "GenSigCycleTime" SG_ 155 DriverDoor2AjarRawValSts 20;
BA_ "FlexKomSigStartValue" SG_ 155 DriverDoor2AjarRawValSts "3FFF0C00000000FFh";
BA_ "FlexKomSigStartPos" SG_ 155 DriverDoor2AjarRawValSts 7;
BA_ "FlexKomSigName" SG_ 155 DriverDoor2AjarRawValSts "CBC_PT6_Pkt";
BA_ "FlexKomSigLaenge" SG_ 155 DriverDoor2AjarRawValSts 64;
BA_ "FlexKomSID" SG_ 155 DriverDoor2AjarRawValSts 1943;
BA_ "FlexKomIsMotorola" SG_ 155 DriverDoor2AjarRawValSts 1;
BA_ "FlexKomComment" SG_ 155 DriverDoor2AjarRawValSts "CBC_PT6 message packet";
BA_ "GenSigSNA" SG_ 155 RefuelRequest "3h";
BA_ "GenSigCycleTime" SG_ 155 RefuelRequest 20;
BA_ "FlexKomSigStartValue" SG_ 155 RefuelRequest "3FFF0C00000000FFh";
BA_ "FlexKomSigStartPos" SG_ 155 RefuelRequest 7;
BA_ "FlexKomSigName" SG_ 155 RefuelRequest "CBC_PT6_Pkt";
BA_ "FlexKomSigLaenge" SG_ 155 RefuelRequest 64;
BA_ "FlexKomSID" SG_ 155 RefuelRequest 1943;
BA_ "FlexKomIsMotorola" SG_ 155 RefuelRequest 1;
BA_ "FlexKomComment" SG_ 155 RefuelRequest "CBC_PT6 message packet";
BA_ "GenSigStartValue" SG_ 155 CRC_CBC_PT6 255;
BA_ "GenSigSNA" SG_ 155 CRC_CBC_PT6 "FFh";
BA_ "GenSigCycleTime" SG_ 155 CRC_CBC_PT6 20;
BA_ "FlexKomSigStartValue" SG_ 155 CRC_CBC_PT6 "3FFF0C00000000FFh";
BA_ "FlexKomSigStartPos" SG_ 155 CRC_CBC_PT6 7;
BA_ "FlexKomSigName" SG_ 155 CRC_CBC_PT6 "CBC_PT6_Pkt";
BA_ "FlexKomSigLaenge" SG_ 155 CRC_CBC_PT6 64;
BA_ "FlexKomSID" SG_ 155 CRC_CBC_PT6 1943;
BA_ "FlexKomIsMotorola" SG_ 155 CRC_CBC_PT6 1;
BA_ "FlexKomComment" SG_ 155 CRC_CBC_PT6 "CBC_PT6 message packet";
BA_ "GenSigSNA" SG_ 319 RsErrIBS3 "0h";
BA_ "GenSigCycleTime" SG_ 319 RsErrIBS3 100;
BA_ "FlexKomSigStartValue" SG_ 319 RsErrIBS3 "00h";
BA_ "FlexKomSigStartPos" SG_ 319 RsErrIBS3 38;
BA_ "FlexKomSigName" SG_ 319 RsErrIBS3 "RsErrIBS3";
BA_ "FlexKomSigLaenge" SG_ 319 RsErrIBS3 1;
BA_ "FlexKomSID" SG_ 319 RsErrIBS3 2652;
BA_ "FlexKomIsMotorola" SG_ 319 RsErrIBS3 1;
BA_ "FlexKomComment" SG_ 319 RsErrIBS3 "Response Error IBS; Error=[1]";
BA_ "RID" SG_ 319 IBS3_Error_Internal "5130";
BA_ "GenSigSNA" SG_ 319 IBS3_Error_Internal "0h";
BA_ "GenSigCycleTime" SG_ 319 IBS3_Error_Internal 100;
BA_ "FlexKomSigStartValue" SG_ 319 IBS3_Error_Internal "00h";
BA_ "FlexKomSigStartPos" SG_ 319 IBS3_Error_Internal 37;
BA_ "FlexKomSigName" SG_ 319 IBS3_Error_Internal "IBS3_Error_Internal";
BA_ "FlexKomSigLaenge" SG_ 319 IBS3_Error_Internal 1;
BA_ "FlexKomSID" SG_ 319 IBS3_Error_Internal 2653;
BA_ "FlexKomIsMotorola" SG_ 319 IBS3_Error_Internal 1;
BA_ "FlexKomComment" SG_ 319 IBS3_Error_Internal "Error in IBS calibration data; No Error = [0], Err";
BA_ "GenSigStartValue" SG_ 657 PTC_REL1_STAT 3;
BA_ "GenSigSNA" SG_ 657 PTC_REL1_STAT "3h";
BA_ "GenSigSendType" SG_ 657 PTC_REL1_STAT 5;
BA_ "GenSigCycleTime" SG_ 657 PTC_REL1_STAT 1000;
BA_ "FlexKomSigStartValue" SG_ 657 PTC_REL1_STAT "3Fh";
BA_ "FlexKomSigStartPos" SG_ 657 PTC_REL1_STAT 47;
BA_ "FlexKomSigName" SG_ 657 PTC_REL1_STAT "PTC_REL_STAT";
BA_ "FlexKomSigName" SG_ 299 FUEL_VOLT "FUEL_VOLT";
BA_ "FlexKomSigLaenge" SG_ 299 FUEL_VOLT 8;
BA_ "FlexKomSID" SG_ 299 FUEL_VOLT 881;
BA_ "FlexKomIsMotorola" SG_ 299 FUEL_VOLT 1;
BA_ "FlexKomComment" SG_ 299 FUEL_VOLT "Fuel level A/D Voltage (Single tank OR Primary on ";
BA_ "GenSigStartValue" SG_ 56 CRC_HCP_A3 255;
BA_ "GenSigSNA" SG_ 56 CRC_HCP_A3 "FFh";
BA_ "GenSigCycleTime" SG_ 56 CRC_HCP_A3 10;
BA_ "FlexKomSigStartValue" SG_ 56 CRC_HCP_A3 "1FFF1FFFFFFE00FFh";
BA_ "FlexKomSigStartPos" SG_ 56 CRC_HCP_A3 7;
BA_ "FlexKomSigName" SG_ 56 CRC_HCP_A3 "HCP_A3_PKT";
BA_ "FlexKomSigLaenge" SG_ 56 CRC_HCP_A3 64;
BA_ "FlexKomSID" SG_ 56 CRC_HCP_A3 2995;
BA_ "FlexKomIsMotorola" SG_ 56 CRC_HCP_A3 1;
BA_ "FlexKomComment" SG_ 56 CRC_HCP_A3 "HCP_A3_PKT";
BA_ "GenSigStartValue" SG_ 54 SumTrqStatic_SEM 8191;
BA_ "GenSigSNA" SG_ 54 SumTrqStatic_SEM "1FFFh";
BA_ "GenSigCycleTime" SG_ 54 SumTrqStatic_SEM 10;
BA_ "FlexKomSigStartValue" SG_ 54 SumTrqStatic_SEM "1FFF1FFF1FFF00FFh";
BA_ "FlexKomSigStartPos" SG_ 54 SumTrqStatic_SEM 7;
BA_ "FlexKomSigName" SG_ 54 SumTrqStatic_SEM "HCP_A2_PKT";
BA_ "FlexKomSigLaenge" SG_ 54 SumTrqStatic_SEM 64;
BA_ "FlexKomSID" SG_ 54 SumTrqStatic_SEM 2994;
BA_ "FlexKomIsMotorola" SG_ 54 SumTrqStatic_SEM 1;
BA_ "FlexKomComment" SG_ 54 SumTrqStatic_SEM "HCP_A2_PKT";
BA_ "GenSigSNA" SG_ 40 MC_HCP_A1 "0h";
BA_ "GenSigCycleTime" SG_ 40 MC_HCP_A1 10;
BA_ "FlexKomSigStartValue" SG_ 40 MC_HCP_A1 "1FFF1FFF1FFF00FFh";
BA_ "FlexKomSigStartPos" SG_ 40 MC_HCP_A1 7;
BA_ "FlexKomSigName" SG_ 40 MC_HCP_A1 "HCP_A1_PKT";
BA_ "FlexKomSigLaenge" SG_ 40 MC_HCP_A1 64;
BA_ "FlexKomSID" SG_ 40 MC_HCP_A1 2990;
BA_ "FlexKomIsMotorola" SG_ 40 MC_HCP_A1 1;
BA_ "FlexKomComment" SG_ 40 MC_HCP_A1 "HCP_A1_PKT";
BA_ "GenSigSNA" SG_ 560 EvapTempTar "FFh";
BA_ "GenSigSendType" SG_ 560 EvapTempTar 5;
BA_ "GenSigCycleTime" SG_ 560 EvapTempTar 500;
BA_ "FlexKomSigStartValue" SG_ 560 EvapTempTar "00h";
BA_ "FlexKomSigStartPos" SG_ 560 EvapTempTar 23;
BA_ "FlexKomSigName" SG_ 560 EvapTempTar "EvapTempTar";
BA_ "FlexKomSigLaenge" SG_ 560 EvapTempTar 8;
BA_ "FlexKomSID" SG_ 560 EvapTempTar 30;
BA_ "FlexKomIsMotorola" SG_ 560 EvapTempTar 1;
BA_ "FlexKomComment" SG_ 560 EvapTempTar "Evaporator temperature target";
BA_ "RID" SG_ 560 PTC_Enbl "1098";
BA_ "GenSigStartValue" SG_ 560 PTC_Enbl 1;
BA_ "GenSigSNA" SG_ 560 PTC_Enbl "1h";
BA_ "GenSigSendType" SG_ 560 PTC_Enbl 5;
BA_ "GenSigCycleTime" SG_ 560 PTC_Enbl 500;
BA_ "FlexKomSigStartValue" SG_ 560 PTC_Enbl "01h";
BA_ "FlexKomSigStartPos" SG_ 560 PTC_Enbl 3;
BA_ "FlexKomSigName" SG_ 560 PTC_Enbl "PTC_Enbl";
BA_ "FlexKomSigLaenge" SG_ 560 PTC_Enbl 1;
BA_ "FlexKomSID" SG_ 560 PTC_Enbl 33;
BA_ "FlexKomIsMotorola" SG_ 560 PTC_Enbl 1;
BA_ "FlexKomComment" SG_ 560 PTC_Enbl "PTC heater enable; [1] = enable";
BA_ "GenSigSNA" SG_ 818 Blower_Speed "1FFh";
BA_ "GenSigSendType" SG_ 818 Blower_Speed 5;
BA_ "GenSigCycleTime" SG_ 818 Blower_Speed 1000;
BA_ "FlexKomSigStartValue" SG_ 818 Blower_Speed "0000h";
BA_ "FlexKomSigStartPos" SG_ 818 Blower_Speed 39;
BA_ "FlexKomSigName" SG_ 818 Blower_Speed "Blower_Frequency";
BA_ "FlexKomSigLaenge" SG_ 818 Blower_Speed 16;
BA_ "FlexKomSID" SG_ 818 Blower_Speed 2801;
BA_ "FlexKomIsMotorola" SG_ 818 Blower_Speed 1;
BA_ "FlexKomComment" SG_ 818 Blower_Speed "Frequency Feedback received from the Blower";
BA_ "FlexKomSigStartPos" SG_ 124 CRC_ECM_A2_PHEV 7;
BA_ "FlexKomSigName" SG_ 124 CRC_ECM_A2_PHEV "ECM_A2_PHEV_PKT";
BA_ "FlexKomSigLaenge" SG_ 124 CRC_ECM_A2_PHEV 64;
BA_ "FlexKomSID" SG_ 124 CRC_ECM_A2_PHEV 2991;
BA_ "FlexKomIsMotorola" SG_ 124 CRC_ECM_A2_PHEV 1;
BA_ "FlexKomComment" SG_ 124 CRC_ECM_A2_PHEV "ECM_A2_PHEV_PKT";
BA_ "RID" SG_ 38 ESS_ENG_ST_PHEV "1653";
BA_ "GenSigTimeout_RF_HUB" SG_ 38 ESS_ENG_ST_PHEV 105;
BA_ "GenSigTimeout_ORC" SG_ 38 ESS_ENG_ST_PHEV 35;
BA_ "GenSigTimeout_CBC" SG_ 38 ESS_ENG_ST_PHEV 105;
BA_ "GenSigStartValue" SG_ 38 ESS_ENG_ST_PHEV 15;
BA_ "GenSigSNA" SG_ 38 ESS_ENG_ST_PHEV "Fh";
BA_ "GenSigCycleTime" SG_ 38 ESS_ENG_ST_PHEV 10;
BA_ "FlexKomSigStartValue" SG_ 38 ESS_ENG_ST_PHEV "FFFFFF00201E00FFh";
BA_ "FlexKomSigStartPos" SG_ 38 ESS_ENG_ST_PHEV 7;
BA_ "FlexKomSigName" SG_ 38 ESS_ENG_ST_PHEV "ECM_A1_PHEV_PKT";
BA_ "FlexKomSigLaenge" SG_ 38 ESS_ENG_ST_PHEV 64;
BA_ "FlexKomSID" SG_ 38 ESS_ENG_ST_PHEV 2992;
BA_ "FlexKomIsMotorola" SG_ 38 ESS_ENG_ST_PHEV 1;
BA_ "FlexKomComment" SG_ 38 ESS_ENG_ST_PHEV "ECM_A1_PHEV_PKT";
BA_ "GenSigStartValue" SG_ 38 CRC_ECM_A1_PHEV 255;
BA_ "GenSigSNA" SG_ 38 CRC_ECM_A1_PHEV "FFh";
BA_ "GenSigCycleTime" SG_ 38 CRC_ECM_A1_PHEV 10;
BA_ "FlexKomSigStartValue" SG_ 38 CRC_ECM_A1_PHEV "FFFFFF00201E00FFh";
BA_ "FlexKomSigStartPos" SG_ 38 CRC_ECM_A1_PHEV 7;
BA_ "FlexKomSigName" SG_ 38 CRC_ECM_A1_PHEV "ECM_A1_PHEV_PKT";
BA_ "FlexKomSigLaenge" SG_ 38 CRC_ECM_A1_PHEV 64;
BA_ "FlexKomSID" SG_ 38 CRC_ECM_A1_PHEV 2992;
BA_ "FlexKomIsMotorola" SG_ 38 CRC_ECM_A1_PHEV 1;
BA_ "FlexKomComment" SG_ 38 CRC_ECM_A1_PHEV "ECM_A1_PHEV_PKT";
BA_ "GenSigSNA" SG_ 819 ExhaustVlvStat "0h";
BA_ "GenSigSendType" SG_ 819 ExhaustVlvStat 5;
BA_ "GenSigCycleTime" SG_ 819 ExhaustVlvStat 1000;
BA_ "FlexKomSigStartValue" SG_ 819 ExhaustVlvStat "00000000000000FFh";
BA_ "FlexKomSigStartPos" SG_ 819 ExhaustVlvStat 7;
BA_ "FlexKomSigName" SG_ 819 ExhaustVlvStat "ECM_A6_PKT1";
BA_ "FlexKomSigLaenge" SG_ 819 ExhaustVlvStat 64;
BA_ "FlexKomSID" SG_ 819 ExhaustVlvStat 3093;
BA_ "FlexKomIsMotorola" SG_ 819 ExhaustVlvStat 1;
BA_ "FlexKomComment" SG_ 819 ExhaustVlvStat "ECM_A6 Packet";
BA_ "GenSigTimeout_IC" SG_ 657 LOBEAM_ON 10500;
BA_ "GenSigSNA" SG_ 657 LOBEAM_ON "0h";
BA_ "GenSigSendType" SG_ 657 LOBEAM_ON 5;
BA_ "GenSigCycleTime" SG_ 657 LOBEAM_ON 1000;
BA_ "FlexKomSigStartValue" SG_ 657 LOBEAM_ON "00h";
BA_ "FlexKomSigStartPos" SG_ 657 LOBEAM_ON 57;
BA_ "FlexKomSigName" SG_ 657 LOBEAM_ON "LOBEAM_ON";
BA_ "FlexKomSigLaenge" SG_ 657 LOBEAM_ON 1;
BA_ "FlexKomSID" SG_ 657 LOBEAM_ON 883;
BA_ "FlexKomIsMotorola" SG_ 657 LOBEAM_ON 1;
BA_ "FlexKomComment" SG_ 657 LOBEAM_ON "Low beam is on; off=[0], on=[1]";
BA_ "GenSigSNA" SG_ 34 AccPosV_PT "0h";
BA_ "GenSigCycleTime" SG_ 34 AccPosV_PT 10;
BA_ "FlexKomSigStartValue" SG_ 34 AccPosV_PT "FFFFFF01F40000FFh";
BA_ "FlexKomSigStartPos" SG_ 34 AccPosV_PT 7;
BA_ "FlexKomSigName" SG_ 34 AccPosV_PT "PT_SYSTEM_1_PKT";
BA_ "FlexKomSigLaenge" SG_ 34 AccPosV_PT 64;
BA_ "FlexKomSID" SG_ 34 AccPosV_PT 3370;
BA_ "FlexKomIsMotorola" SG_ 34 AccPosV_PT 1;
BA_ "FlexKomComment" SG_ 34 AccPosV_PT "PT_SYSTEM_1_PKT Packet";
BA_ "GenSigSNA" SG_ 34 MC_PT_SYSTEM_1 "0h";
BA_ "GenSigCycleTime" SG_ 34 MC_PT_SYSTEM_1 10;
BA_ "FlexKomSigStartValue" SG_ 34 MC_PT_SYSTEM_1 "FFFFFF01F40000FFh";
BA_ "FlexKomSigStartPos" SG_ 34 MC_PT_SYSTEM_1 7;
BA_ "FlexKomSigName" SG_ 34 MC_PT_SYSTEM_1 "PT_SYSTEM_1_PKT";
BA_ "FlexKomSigLaenge" SG_ 34 MC_PT_SYSTEM_1 64;
BA_ "FlexKomSID" SG_ 34 MC_PT_SYSTEM_1 3370;
BA_ "FlexKomSigStartPos" SG_ 53 CRC_ECM_A3 7;
BA_ "FlexKomSigName" SG_ 53 CRC_ECM_A3 "ECM_A3_PKT";
BA_ "FlexKomSigLaenge" SG_ 53 CRC_ECM_A3 64;
BA_ "FlexKomSID" SG_ 53 CRC_ECM_A3 1369;
BA_ "FlexKomIsMotorola" SG_ 53 CRC_ECM_A3 1;
BA_ "FlexKomComment" SG_ 53 CRC_ECM_A3 "ECM_A3 message packet";
BA_ "GenSigTimeout_DTCM" SG_ 123 EngTrq_DrvReqMod 210;
BA_ "GenSigStartValue" SG_ 123 EngTrq_DrvReqMod 8191;
BA_ "GenSigSNA" SG_ 123 EngTrq_DrvReqMod "1FFFh";
BA_ "GenSigCycleTime" SG_ 123 EngTrq_DrvReqMod 20;
BA_ "FlexKomSigStartValue" SG_ 123 EngTrq_DrvReqMod "1FFFFF1FFF00FFh";
BA_ "FlexKomSigStartPos" SG_ 123 EngTrq_DrvReqMod 7;
BA_ "FlexKomSigName" SG_ 123 EngTrq_DrvReqMod "ECM_A2_PKT";
BA_ "FlexKomSigLaenge" SG_ 123 EngTrq_DrvReqMod 56;
BA_ "FlexKomSID" SG_ 123 EngTrq_DrvReqMod 455;
BA_ "FlexKomIsMotorola" SG_ 123 EngTrq_DrvReqMod 1;
BA_ "FlexKomComment" SG_ 123 EngTrq_DrvReqMod "ECM_A2 Packet";
BA_ "GenSigTimeout_TCM" SG_ 123 ECM_LHOM 210;
BA_ "GenSigSNA" SG_ 123 ECM_LHOM "0h";
BA_ "GenSigCycleTime" SG_ 123 ECM_LHOM 20;
BA_ "FlexKomSigStartValue" SG_ 123 ECM_LHOM "1FFFFF1FFF00FFh";
BA_ "FlexKomSigStartPos" SG_ 123 ECM_LHOM 7;
BA_ "FlexKomSigName" SG_ 123 ECM_LHOM "ECM_A2_PKT";
BA_ "FlexKomSigLaenge" SG_ 123 ECM_LHOM 56;
BA_ "FlexKomSID" SG_ 123 ECM_LHOM 455;
BA_ "FlexKomIsMotorola" SG_ 123 ECM_LHOM 1;
BA_ "FlexKomComment" SG_ 123 ECM_LHOM "ECM_A2 Packet";
BA_ "GenSigSNA" SG_ 123 RPMOverRev "0h";
BA_ "GenSigCycleTime" SG_ 123 RPMOverRev 20;
BA_ "FlexKomSigStartValue" SG_ 123 RPMOverRev "1FFFFF1FFF00FFh";
BA_ "FlexKomSigStartPos" SG_ 123 RPMOverRev 7;
BA_ "FlexKomSigName" SG_ 123 RPMOverRev "ECM_A2_PKT";
BA_ "FlexKomSigLaenge" SG_ 123 RPMOverRev 56;
BA_ "FlexKomSID" SG_ 123 RPMOverRev 455;
BA_ "FlexKomIsMotorola" SG_ 123 RPMOverRev 1;
BA_ "FlexKomComment" SG_ 123 RPMOverRev "ECM_A2 Packet";
BA_ "GenSigTimeout_DTCM" SG_ 37 ExpEngTrq 105;
BA_ "GenSigStartValue" SG_ 37 ExpEngTrq 8191;
BA_ "GenSigSNA" SG_ 37 ExpEngTrq "1FFFh";
BA_ "GenSigCycleTime" SG_ 37 ExpEngTrq 10;
BA_ "FlexKomSigStartValue" SG_ 37 ExpEngTrq "FFFF1FFF1FFF00FFh";
BA_ "FlexKomSigStartPos" SG_ 37 ExpEngTrq 7;
BA_ "FlexKomSigName" SG_ 37 ExpEngTrq "ECM_A1_PKT";
BA_ "FlexKomSigLaenge" SG_ 37 ExpEngTrq 64;
BA_ "FlexKomSID" SG_ 37 ExpEngTrq 446;
BA_ "FlexKomIsMotorola" SG_ 37 ExpEngTrq 1;
BA_ "FlexKomComment" SG_ 37 ExpEngTrq "ECM_A1 Packet";
BA_ "GenSigSNA" SG_ 37 ECM_LHOM_Trans "0h";
BA_ "GenSigCycleTime" SG_ 37 ECM_LHOM_Trans 10;
BA_ "FlexKomSigStartValue" SG_ 37 ECM_LHOM_Trans "FFFF1FFF1FFF00FFh";
BA_ "FlexKomSigStartPos" SG_ 37 ECM_LHOM_Trans 7;
BA_ "FlexKomSigName" SG_ 37 ECM_LHOM_Trans "ECM_A1_PKT";
BA_ "FlexKomSigLaenge" SG_ 37 ECM_LHOM_Trans 64;
BA_ "FlexKomSID" SG_ 37 ECM_LHOM_Trans 446;
BA_ "FlexKomIsMotorola" SG_ 37 ECM_LHOM_Trans 1;
BA_ "FlexKomComment" SG_ 37 ECM_LHOM_Trans "ECM_A1 Packet";
BA_ "GenSigSNA" SG_ 145 DrvLnMinTrqMd "0h";
BA_ "GenSigCycleTime" SG_ 145 DrvLnMinTrqMd 20;
BA_ "FlexKomSigStartValue" SG_ 145 DrvLnMinTrqMd "01FF7F00000000FFh";
BA_ "FlexKomSigStartPos" SG_ 145 DrvLnMinTrqMd 7;
BA_ "FlexKomSigName" SG_ 145 DrvLnMinTrqMd "DTCM_A2_PKT";
BA_ "FlexKomSigLaenge" SG_ 145 DrvLnMinTrqMd 64;
BA_ "FlexKomSID" SG_ 145 DrvLnMinTrqMd 1520;
BA_ "FlexKomIsMotorola" SG_ 145 DrvLnMinTrqMd 1;
BA_ "FlexKomComment" SG_ 145 DrvLnMinTrqMd "DTCM_A2_PKT";
BA_ "RID" SG_ 141 TCASE_STAT "1238";
BA_ "GenSigTimeout_TCM" SG_ 141 TCASE_STAT 210;
BA_ "GenSigTimeout_RF_HUB" SG_ 141 TCASE_STAT 210;
BA_ "GenSigTimeout_PTS" SG_ 141 TCASE_STAT 210;
BA_ "GenSigTimeout_ORC" SG_ 141 TCASE_STAT 70;
BA_ "GenSigTimeout_IC" SG_ 141 TCASE_STAT 210;
BA_ "GenSigTimeout_ETM" SG_ 141 TCASE_STAT 210;
BA_ "GenSigTimeout_CBC" SG_ 141 TCASE_STAT 210;
BA_ "GenSigStartValue" SG_ 141 TCASE_STAT 7;
BA_ "GenSigSNA" SG_ 141 TCASE_STAT "7h";
BA_ "GenSigCycleTime" SG_ 141 TCASE_STAT 20;
BA_ "FlexKomSigStartValue" SG_ 141 TCASE_STAT "CEC0FFFFFFFFFFFFh";
BA_ "FlexKomSigStartPos" SG_ 141 TCASE_STAT 7;
BA_ "FlexKomSigName" SG_ 141 TCASE_STAT "DTCM_A1_PKT";
BA_ "FlexKomSigLaenge" SG_ 141 TCASE_STAT 64;
BA_ "FlexKomSID" SG_ 141 TCASE_STAT 807;
BA_ "FlexKomIsMotorola" SG_ 141 TCASE_STAT 1;
BA_ "FlexKomComment" SG_ 141 TCASE_STAT "DTCM_A1_PKT";
BA_ "GenSigSNA" SG_ 167 BrkPrss_One "0h";
BA_ "GenSigCycleTime" SG_ 167 BrkPrss_One 20;
BA_ "FlexKomSigStartValue" SG_ 167 BrkPrss_One "04000000C00000FFh";
BA_ "FlexKomSigStartPos" SG_ 167 BrkPrss_One 7;
BA_ "FlexKomSigName" SG_ 167 BrkPrss_One "DST_TOC";
BA_ "FlexKomSigLaenge" SG_ 167 BrkPrss_One 64;
BA_ "FlexKomSID" SG_ 167 BrkPrss_One 1909;
BA_ "FlexKomIsMotorola" SG_ 167 BrkPrss_One 1;
BA_ "FlexKomComment" SG_ 167 BrkPrss_One "DST_TOC";
BA_ "GenSigSNA" SG_ 462 DrvPrsnSensorRawValSts "0h";
BA_ "GenSigCycleTime" SG_ 462 DrvPrsnSensorRawValSts 50;
BA_ "FlexKomSigStartValue" SG_ 462 DrvPrsnSensorRawValSts "000000FFh";
BA_ "FlexKomSigStartPos" SG_ 462 DrvPrsnSensorRawValSts 7;
BA_ "FlexKomSigName" SG_ 462 DrvPrsnSensorRawValSts "DPDM_A2_PKT";
BA_ "FlexKomSigLaenge" SG_ 462 DrvPrsnSensorRawValSts 32;
BA_ "FlexKomSID" SG_ 462 DrvPrsnSensorRawValSts 2683;
BA_ "FlexKomIsMotorola" SG_ 462 DrvPrsnSensorRawValSts 1;
BA_ "FlexKomComment" SG_ 462 DrvPrsnSensorRawValSts "DPDM_A2_PKT";
BA_ "GenSigSNA" SG_ 607 CBC_Reset_Flag "3h";
BA_ "GenSigSendType" SG_ 607 CBC_Reset_Flag 5;
BA_ "GenSigCycleTime" SG_ 607 CBC_Reset_Flag 1000;
BA_ "FlexKomSigStartValue" SG_ 607 CBC_Reset_Flag "00h";
BA_ "FlexKomSigStartPos" SG_ 607 CBC_Reset_Flag 17;
BA_ "FlexKomSigName" SG_ 607 CBC_Reset_Flag "CBC_Reset_Flag";
BA_ "FlexKomSigLaenge" SG_ 607 CBC_Reset_Flag 2;
BA_ "FlexKomSID" SG_ 607 CBC_Reset_Flag 2530;
BA_ "FlexKomIsMotorola" SG_ 607 CBC_Reset_Flag 1;
BA_ "FlexKomComment" SG_ 607 CBC_Reset_Flag "CBC reset flag";
BA_ "GenSigStartValue" SG_ 155 PsngrDoorAjarXtionSts 3;
BA_ "GenSigSNA" SG_ 155 PsngrDoorAjarXtionSts "3h";
BA_ "GenSigCycleTime" SG_ 155 PsngrDoorAjarXtionSts 20;
BA_ "FlexKomSigStartValue" SG_ 155 PsngrDoorAjarXtionSts "3FFF0C00000000FFh";
BA_ "FlexKomSigStartPos" SG_ 155 PsngrDoorAjarXtionSts 7;
BA_ "FlexKomSigName" SG_ 155 PsngrDoorAjarXtionSts "CBC_PT6_Pkt";
BA_ "FlexKomSigLaenge" SG_ 155 PsngrDoorAjarXtionSts 64;
BA_ "FlexKomSID" SG_ 155 PsngrDoorAjarXtionSts 1943;
BA_ "FlexKomIsMotorola" SG_ 155 PsngrDoorAjarXtionSts 1;
BA_ "FlexKomComment" SG_ 155 PsngrDoorAjarXtionSts "CBC_PT6 message packet";
BA_ "GenSigTimeout_ORC" SG_ 155 DriverDoorAjarRawValSts 70;
BA_ "GenSigSNA" SG_ 155 DriverDoorAjarRawValSts "Fh";
BA_ "GenSigCycleTime" SG_ 155 DriverDoorAjarRawValSts 20;
BA_ "FlexKomSigStartValue" SG_ 155 DriverDoorAjarRawValSts "3FFF0C00000000FFh";
BA_ "FlexKomSigStartPos" SG_ 155 DriverDoorAjarRawValSts 7;
BA_ "FlexKomSigName" SG_ 155 DriverDoorAjarRawValSts "CBC_PT6_Pkt";
BA_ "FlexKomSigLaenge" SG_ 155 DriverDoorAjarRawValSts 64;
BA_ "FlexKomSID" SG_ 155 DriverDoorAjarRawValSts 1943;
BA_ "FlexKomIsMotorola" SG_ 155 DriverDoorAjarRawValSts 1;
BA_ "FlexKomComment" SG_ 155 DriverDoorAjarRawValSts "CBC_PT6 message packet";
BA_ "GenSigStartValue" SG_ 155 DriverDoor2AjarXtionSts 3;
BA_ "GenSigSNA" SG_ 155 DriverDoor2AjarXtionSts "3h";
BA_ "GenSigCycleTime" SG_ 155 DriverDoor2AjarXtionSts 20;
BA_ "FlexKomSigStartValue" SG_ 155 DriverDoor2AjarXtionSts "3FFF0C00000000FFh";
BA_ "FlexKomSigStartPos" SG_ 155 DriverDoor2AjarXtionSts 7;
BA_ "FlexKomSigName" SG_ 155 DriverDoor2AjarXtionSts "CBC_PT6_Pkt";
BA_ "FlexKomSigLaenge" SG_ 155 DriverDoor2AjarXtionSts 64;
BA_ "FlexKomSID" SG_ 155 DriverDoor2AjarXtionSts 1943;
BA_ "FlexKomIsMotorola" SG_ 155 DriverDoor2AjarXtionSts 1;
BA_ "FlexKomComment" SG_ 155 DriverDoor2AjarXtionSts "CBC_PT6 message packet";
BA_ "GenSigStartValue" SG_ 34 ActlAccelPdlPosn_PT 255;
BA_ "GenSigSNA" SG_ 34 ActlAccelPdlPosn_PT "FFh";
BA_ "GenSigCycleTime" SG_ 34 ActlAccelPdlPosn_PT 10;
BA_ "FlexKomSigStartValue" SG_ 34 ActlAccelPdlPosn_PT "FFFFFF01F40000FFh";
BA_ "FlexKomSigStartPos" SG_ 34 ActlAccelPdlPosn_PT 7;
BA_ "FlexKomSigName" SG_ 34 ActlAccelPdlPosn_PT "PT_SYSTEM_1_PKT";
BA_ "FlexKomSigLaenge" SG_ 34 ActlAccelPdlPosn_PT 64;
BA_ "FlexKomSID" SG_ 34 ActlAccelPdlPosn_PT 3370;
BA_ "FlexKomIsMotorola" SG_ 34 ActlAccelPdlPosn_PT 1;
BA_ "FlexKomComment" SG_ 34 ActlAccelPdlPosn_PT "PT_SYSTEM_1_PKT Packet";
BA_ "GenSigSNA" SG_ 906 VC_OFFRoadModePrsnt "0h";
BA_ "GenSigSendType" SG_ 906 VC_OFFRoadModePrsnt 5;
BA_ "GenSigCycleTime" SG_ 906 VC_OFFRoadModePrsnt 2000;
BA_ "FlexKomSigStartValue" SG_ 906 VC_OFFRoadModePrsnt "0300000000000000h";
BA_ "FlexKomSigStartPos" SG_ 906 VC_OFFRoadModePrsnt 7;
BA_ "FlexKomSigName" SG_ 906 VC_OFFRoadModePrsnt "VehCfg8_Pkt";
BA_ "FlexKomSigLaenge" SG_ 906 VC_OFFRoadModePrsnt 64;
BA_ "FlexKomSID" SG_ 906 VC_OFFRoadModePrsnt 2722;
BA_ "FlexKomIsMotorola" SG_ 906 VC_OFFRoadModePrsnt 1;
BA_ "FlexKomComment" SG_ 906 VC_OFFRoadModePrsnt "Vehicle Configuration 8 Packet";
BA_ "GenSigTimeout_RF_HUB" SG_ 906 VC_Increasing_Speed_Constant 10500;
BA_ "GenSigTimeout_IC" SG_ 906 VC_Increasing_Speed_Constant 10500;
BA_ "GenSigSNA" SG_ 906 VC_Increasing_Speed_Constant "0h";
BA_ "GenSigSendType" SG_ 906 VC_Increasing_Speed_Constant 5;
BA_ "GenSigCycleTime" SG_ 906 VC_Increasing_Speed_Constant 2000;
BA_ "FlexKomSigStartValue" SG_ 906 VC_Increasing_Speed_Constant "0300000000000000h";
BA_ "FlexKomSigStartPos" SG_ 906 VC_Increasing_Speed_Constant 7;
BA_ "FlexKomSigName" SG_ 906 VC_Increasing_Speed_Constant "VehCfg8_Pkt";
BA_ "FlexKomSigLaenge" SG_ 906 VC_Increasing_Speed_Constant 64;
BA_ "FlexKomSID" SG_ 906 VC_Increasing_Speed_Constant 2722;
BA_ "FlexKomIsMotorola" SG_ 906 VC_Increasing_Speed_Constant 1;
BA_ "FlexKomComment" SG_ 906 VC_Increasing_Speed_Constant "Vehicle Configuration 8 Packet";
BA_ "RID" SG_ 818 A2D_DRV_TEMP_DR_POS "6333";
BA_ "GenSigStartValue" SG_ 818 A2D_DRV_TEMP_DR_POS 1023;
BA_ "GenSigSNA" SG_ 818 A2D_DRV_TEMP_DR_POS "3FFh";
BA_ "GenSigSendType" SG_ 818 A2D_DRV_TEMP_DR_POS 5;
BA_ "GenSigCycleTime" SG_ 818 A2D_DRV_TEMP_DR_POS 1000;
BA_ "FlexKomSigStartValue" SG_ 818 A2D_DRV_TEMP_DR_POS "03FFh";
BA_ "FlexKomSigStartPos" SG_ 818 A2D_DRV_TEMP_DR_POS 7;
BA_ "RID" SG_ 53 TRANS_CLU_SLIP_MODE "2105";
BA_ "GenSigTimeout_CBC" SG_ 53 TRANS_CLU_SLIP_MODE 105;
BA_ "GenSigSNA" SG_ 53 TRANS_CLU_SLIP_MODE "7h";
BA_ "GenSigCycleTime" SG_ 53 TRANS_CLU_SLIP_MODE 10;
BA_ "FlexKomSigStartValue" SG_ 53 TRANS_CLU_SLIP_MODE "5FFF1FFF00FF0FFFh";
BA_ "FlexKomSigStartPos" SG_ 53 TRANS_CLU_SLIP_MODE 7;
BA_ "FlexKomSigName" SG_ 53 TRANS_CLU_SLIP_MODE "ECM_A3_PKT";
BA_ "FlexKomSigLaenge" SG_ 53 TRANS_CLU_SLIP_MODE 64;
BA_ "FlexKomSID" SG_ 53 TRANS_CLU_SLIP_MODE 1369;
BA_ "FlexKomIsMotorola" SG_ 53 TRANS_CLU_SLIP_MODE 1;
BA_ "FlexKomComment" SG_ 53 TRANS_CLU_SLIP_MODE "ECM_A3 message packet";
BA_ "RID" SG_ 53 ESS_ENG_ST "1653";
BA_ "RID" SG_ 155 AC_OutptCurrStat "3055";
BA_ "GenSigStartValue" SG_ 155 AC_OutptCurrStat 255;
BA_ "GenSigSNA" SG_ 155 AC_OutptCurrStat "FFh";
BA_ "GenSigCycleTime" SG_ 155 AC_OutptCurrStat 20;
BA_ "FlexKomSigStartValue" SG_ 155 AC_OutptCurrStat "3FFF0C00000000FFh";
BA_ "FlexKomSigStartPos" SG_ 155 AC_OutptCurrStat 7;
BA_ "FlexKomSigName" SG_ 155 AC_OutptCurrStat "CBC_PT6_Pkt";
BA_ "FlexKomSigLaenge" SG_ 155 AC_OutptCurrStat 64;
BA_ "FlexKomSID" SG_ 155 AC_OutptCurrStat 1943;
BA_ "FlexKomIsMotorola" SG_ 155 AC_OutptCurrStat 1;
BA_ "FlexKomComment" SG_ 155 AC_OutptCurrStat "CBC_PT6 message packet";
BA_ "GenSigSNA" SG_ 155 FuelDrRelSwRawSt "FFh";
BA_ "GenSigCycleTime" SG_ 155 FuelDrRelSwRawSt 20;
BA_ "FlexKomSigStartValue" SG_ 155 FuelDrRelSwRawSt "3FFF0C00000000FFh";
BA_ "FlexKomSigStartPos" SG_ 155 FuelDrRelSwRawSt 7;
BA_ "FlexKomSigName" SG_ 155 FuelDrRelSwRawSt "CBC_PT6_Pkt";
BA_ "FlexKomSigLaenge" SG_ 155 FuelDrRelSwRawSt 64;
BA_ "FlexKomSID" SG_ 155 FuelDrRelSwRawSt 1943;
BA_ "FlexKomIsMotorola" SG_ 155 FuelDrRelSwRawSt 1;
BA_ "FlexKomComment" SG_ 155 FuelDrRelSwRawSt "CBC_PT6 message packet";
BA_ "GenSigSNA" SG_ 155 MC_CBC_PT6 "0h";
BA_ "GenSigCycleTime" SG_ 155 MC_CBC_PT6 20;
BA_ "FlexKomSigStartValue" SG_ 155 MC_CBC_PT6 "3FFF0C00000000FFh";
BA_ "FlexKomSigStartPos" SG_ 155 MC_CBC_PT6 7;
BA_ "FlexKomSigName" SG_ 155 MC_CBC_PT6 "CBC_PT6_Pkt";
BA_ "FlexKomSigLaenge" SG_ 155 MC_CBC_PT6 64;
BA_ "FlexKomSID" SG_ 155 MC_CBC_PT6 1943;
BA_ "FlexKomIsMotorola" SG_ 155 MC_CBC_PT6 1;
BA_ "FlexKomComment" SG_ 155 MC_CBC_PT6 "CBC_PT6 message packet";
BA_ "FlexKomSigStartValue" SG_ 906 VC_TACHO_TYPE "0300000000000000h";
BA_ "FlexKomSigStartPos" SG_ 906 VC_TACHO_TYPE 7;
BA_ "FlexKomSigName" SG_ 906 VC_TACHO_TYPE "VehCfg8_Pkt";
BA_ "FlexKomSigLaenge" SG_ 906 VC_TACHO_TYPE 64;
BA_ "FlexKomSID" SG_ 906 VC_TACHO_TYPE 2722;
BA_ "FlexKomIsMotorola" SG_ 906 VC_TACHO_TYPE 1;
BA_ "FlexKomComment" SG_ 906 VC_TACHO_TYPE "Vehicle Configuration 8 Packet";
BA_ "GenSigSNA" SG_ 738 REPRGD_PFC_CLR_ESC "0h";
BA_ "GenSigCycleTime" SG_ 738 REPRGD_PFC_CLR_ESC 100;
BA_ "FlexKomSigStartValue" SG_ 738 REPRGD_PFC_CLR_ESC "00000000000000FFh";
BA_ "FlexKomSigStartPos" SG_ 738 REPRGD_PFC_CLR_ESC 7;
BA_ "FlexKomSigName" SG_ 738 REPRGD_PFC_CLR_ESC "ESP_B4_PKT";
BA_ "FlexKomSigLaenge" SG_ 738 REPRGD_PFC_CLR_ESC 64;
BA_ "FlexKomSID" SG_ 738 REPRGD_PFC_CLR_ESC 2689;
BA_ "FlexKomIsMotorola" SG_ 738 REPRGD_PFC_CLR_ESC 1;
BA_ "FlexKomComment" SG_ 738 REPRGD_PFC_CLR_ESC "ESP_B4 Packet";
BA_ "GenSigSNA" SG_ 818 Blower_Diagnostics "3FFh";
BA_ "GenSigSendType" SG_ 818 Blower_Diagnostics 5;
BA_ "GenSigCycleTime" SG_ 818 Blower_Diagnostics 1000;
BA_ "FlexKomSigStartValue" SG_ 818 Blower_Diagnostics "0000h";
BA_ "FlexKomSigStartPos" SG_ 818 Blower_Diagnostics 55;
BA_ "FlexKomSigName" SG_ 818 Blower_Diagnostics "Blower_Dutycycle";
BA_ "FlexKomSigLaenge" SG_ 818 Blower_Diagnostics 16;
BA_ "FlexKomSID" SG_ 818 Blower_Diagnostics 2802;
BA_ "FlexKomIsMotorola" SG_ 818 Blower_Diagnostics 1;
BA_ "FlexKomComment" SG_ 818 Blower_Diagnostics "Duty cycle Feedback received from the Blower";
BA_ "GenSigStartValue" SG_ 181 EngineStaticTorque 938;
BA_ "GenSigSNA" SG_ 181 EngineStaticTorque "FFFh";
BA_ "GenSigCycleTime" SG_ 181 EngineStaticTorque 20;
BA_ "FlexKomSigStartValue" SG_ 181 EngineStaticTorque "0000FFFF03AA00FFh";
BA_ "GenSigTimeout_IC" SG_ 323 DrvAway_Inhibit 1050;
BA_ "GenSigSNA" SG_ 323 DrvAway_Inhibit "0h";
BA_ "GenSigCycleTime" SG_ 323 DrvAway_Inhibit 100;
BA_ "FlexKomSigStartValue" SG_ 323 DrvAway_Inhibit "00h";
BA_ "FlexKomSigStartPos" SG_ 323 DrvAway_Inhibit 15;
BA_ "FlexKomSigName" SG_ 323 DrvAway_Inhibit "DrvAway_Inhibit";
BA_ "FlexKomSigLaenge" SG_ 323 DrvAway_Inhibit 1;
BA_ "FlexKomSID" SG_ 323 DrvAway_Inhibit 2391;
BA_ "FlexKomIsMotorola" SG_ 323 DrvAway_Inhibit 1;
BA_ "FlexKomComment" SG_ 323 DrvAway_Inhibit "Drive Away Inhibit; True = [1]";
BA_ "RID" SG_ 560 DEFROST_SEL "1103";
BA_ "GenSigSNA" SG_ 560 DEFROST_SEL "0h";
BA_ "GenSigSendType" SG_ 560 DEFROST_SEL 5;
BA_ "GenSigCycleTime" SG_ 560 DEFROST_SEL 500;
BA_ "FlexKomSigStartValue" SG_ 560 DEFROST_SEL "00h";
BA_ "FlexKomSigStartPos" SG_ 560 DEFROST_SEL 2;
BA_ "FlexKomSigName" SG_ 560 DEFROST_SEL "DEFROST_SEL";
BA_ "FlexKomSigLaenge" SG_ 560 DEFROST_SEL 1;
BA_ "FlexKomSID" SG_ 560 DEFROST_SEL 28;
BA_ "FlexKomIsMotorola" SG_ 560 DEFROST_SEL 1;
BA_ "FlexKomComment" SG_ 560 DEFROST_SEL "Defrost select switch";
BA_ "RID" SG_ 560 EvapTempTar "1247";
BA_ "GenSigCycleTime" SG_ 124 EngTrq_Enbl_Rq_TCM_PHEV 20;
BA_ "FlexKomSigStartValue" SG_ 124 EngTrq_Enbl_Rq_TCM_PHEV "FF0000001FFF00FFh";
BA_ "FlexKomSigStartPos" SG_ 124 EngTrq_Enbl_Rq_TCM_PHEV 7;
BA_ "FlexKomSigName" SG_ 124 EngTrq_Enbl_Rq_TCM_PHEV "ECM_A2_PHEV_PKT";
BA_ "FlexKomSigLaenge" SG_ 124 EngTrq_Enbl_Rq_TCM_PHEV 64;
BA_ "FlexKomSID" SG_ 124 EngTrq_Enbl_Rq_TCM_PHEV 2991;
BA_ "FlexKomIsMotorola" SG_ 124 EngTrq_Enbl_Rq_TCM_PHEV 1;
BA_ "FlexKomComment" SG_ 124 EngTrq_Enbl_Rq_TCM_PHEV "ECM_A2_PHEV_PKT";
BA_ "GenSigSNA" SG_ 124 EngTrq_Enbl_Rq_AS_PHEV "0h";
BA_ "GenSigCycleTime" SG_ 124 EngTrq_Enbl_Rq_AS_PHEV 20;
BA_ "FlexKomSigStartValue" SG_ 124 EngTrq_Enbl_Rq_AS_PHEV "FF0000001FFF00FFh";
BA_ "FlexKomSigStartPos" SG_ 124 EngTrq_Enbl_Rq_AS_PHEV 7;
BA_ "FlexKomSigName" SG_ 124 EngTrq_Enbl_Rq_AS_PHEV "ECM_A2_PHEV_PKT";
BA_ "FlexKomSigLaenge" SG_ 124 EngTrq_Enbl_Rq_AS_PHEV 64;
BA_ "FlexKomSID" SG_ 124 EngTrq_Enbl_Rq_AS_PHEV 2991;
BA_ "FlexKomIsMotorola" SG_ 124 EngTrq_Enbl_Rq_AS_PHEV 1;
BA_ "FlexKomComment" SG_ 124 EngTrq_Enbl_Rq_AS_PHEV "ECM_A2_PHEV_PKT";
BA_ "GenSigTimeout_TCM" SG_ 124 CRUISE_OVERRIDE_PHEV 210;
BA_ "GenSigTimeout_IC" SG_ 124 CRUISE_OVERRIDE_PHEV 210;
BA_ "GenSigSNA" SG_ 124 CRUISE_OVERRIDE_PHEV "0h";
BA_ "GenSigCycleTime" SG_ 124 CRUISE_OVERRIDE_PHEV 20;
BA_ "FlexKomSigStartValue" SG_ 124 CRUISE_OVERRIDE_PHEV "FF0000001FFF00FFh";
BA_ "FlexKomSigStartPos" SG_ 124 CRUISE_OVERRIDE_PHEV 7;
BA_ "FlexKomSigName" SG_ 124 CRUISE_OVERRIDE_PHEV "ECM_A2_PHEV_PKT";
BA_ "FlexKomSigLaenge" SG_ 124 CRUISE_OVERRIDE_PHEV 64;
BA_ "FlexKomSID" SG_ 124 CRUISE_OVERRIDE_PHEV 2991;
BA_ "FlexKomIsMotorola" SG_ 124 CRUISE_OVERRIDE_PHEV 1;
BA_ "FlexKomComment" SG_ 124 CRUISE_OVERRIDE_PHEV "ECM_A2_PHEV_PKT";
BA_ "GenSigSNA" SG_ 38 ECM_LHOM_Trans_PHEV "0h";
BA_ "GenSigCycleTime" SG_ 38 ECM_LHOM_Trans_PHEV 10;
BA_ "FlexKomSigStartValue" SG_ 38 ECM_LHOM_Trans_PHEV "FFFFFF00201E00FFh";
BA_ "FlexKomSigStartPos" SG_ 38 ECM_LHOM_Trans_PHEV 7;
BA_ "FlexKomSigName" SG_ 38 ECM_LHOM_Trans_PHEV "ECM_A1_PHEV_PKT";
BA_ "FlexKomSigLaenge" SG_ 38 ECM_LHOM_Trans_PHEV 64;
BA_ "FlexKomSID" SG_ 38 ECM_LHOM_Trans_PHEV 2992;
BA_ "FlexKomIsMotorola" SG_ 38 ECM_LHOM_Trans_PHEV 1;
BA_ "FlexKomComment" SG_ 38 ECM_LHOM_Trans_PHEV "ECM_A1_PHEV_PKT";
BA_ "GenSigTimeout_CBC" SG_ 38 ANL_LFT_PHEV 105;
BA_ "GenSigSNA" SG_ 38 ANL_LFT_PHEV "0h";
BA_ "GenSigCycleTime" SG_ 38 ANL_LFT_PHEV 10;
BA_ "FlexKomSigStartValue" SG_ 38 ANL_LFT_PHEV "FFFFFF00201E00FFh";
BA_ "FlexKomSigStartPos" SG_ 38 ANL_LFT_PHEV 7;
BA_ "FlexKomSigName" SG_ 38 ANL_LFT_PHEV "ECM_A1_PHEV_PKT";
BA_ "FlexKomSigLaenge" SG_ 38 ANL_LFT_PHEV 64;
BA_ "FlexKomSID" SG_ 38 ANL_LFT_PHEV 2992;
BA_ "FlexKomIsMotorola" SG_ 38 ANL_LFT_PHEV 1;
BA_ "FlexKomComment" SG_ 38 ANL_LFT_PHEV "ECM_A1_PHEV_PKT";
BA_ "RID" SG_ 38 FullOFC_Actv_PHEV "1822";
BA_ "GenSigSNA" SG_ 38 FullOFC_Actv_PHEV "0h";
BA_ "GenSigCycleTime" SG_ 38 FullOFC_Actv_PHEV 10;
BA_ "FlexKomSigStartValue" SG_ 38 FullOFC_Actv_PHEV "FFFFFF00201E00FFh";
BA_ "FlexKomSigStartPos" SG_ 38 FullOFC_Actv_PHEV 7;
BA_ "FlexKomSigName" SG_ 38 FullOFC_Actv_PHEV "ECM_A1_PHEV_PKT";
BA_ "FlexKomSigLaenge" SG_ 38 FullOFC_Actv_PHEV 64;
BA_ "FlexKomSID" SG_ 38 FullOFC_Actv_PHEV 2992;
BA_ "FlexKomIsMotorola" SG_ 38 FullOFC_Actv_PHEV 1;
BA_ "FlexKomComment" SG_ 38 FullOFC_Actv_PHEV "ECM_A1_PHEV_PKT";
BA_ "GenSigSNA" SG_ 38 ESS_ReqShiftPark_PHEV "0h";
BA_ "GenSigCycleTime" SG_ 38 ESS_ReqShiftPark_PHEV 10;
BA_ "FlexKomSigStartValue" SG_ 38 ESS_ReqShiftPark_PHEV "FFFFFF00201E00FFh";
BA_ "FlexKomSigStartPos" SG_ 38 ESS_ReqShiftPark_PHEV 7;
BA_ "FlexKomSigName" SG_ 38 ESS_ReqShiftPark_PHEV "ECM_A1_PHEV_PKT";
BA_ "FlexKomSigLaenge" SG_ 38 ESS_ReqShiftPark_PHEV 64;
BA_ "FlexKomSID" SG_ 38 ESS_ReqShiftPark_PHEV 2992;
BA_ "FlexKomIsMotorola" SG_ 38 ESS_ReqShiftPark_PHEV 1;
BA_ "FlexKomComment" SG_ 38 ESS_ReqShiftPark_PHEV "ECM_A1_PHEV_PKT";
BA_ "GenSigSNA" SG_ 819 ExhaustSwStat "3h";
BA_ "GenSigSendType" SG_ 819 ExhaustSwStat 5;
BA_ "GenSigCycleTime" SG_ 819 ExhaustSwStat 1000;
BA_ "FlexKomSigStartValue" SG_ 819 ExhaustSwStat "00000000000000FFh";
BA_ "FlexKomSigStartPos" SG_ 819 ExhaustSwStat 7;
BA_ "FlexKomSigName" SG_ 819 ExhaustSwStat "ECM_A6_PKT1";
BA_ "FlexKomSigLaenge" SG_ 819 ExhaustSwStat 64;
BA_ "FlexKomSID" SG_ 819 ExhaustSwStat 3093;
BA_ "FlexKomIsMotorola" SG_ 819 ExhaustSwStat 1;
BA_ "FlexKomComment" SG_ 819 ExhaustSwStat "ECM_A6 Packet";
BA_ "GenSigTimeout_RF_HUB" SG_ 299 AirTemp_Outsd 1050;
BA_ "GenSigTimeout_ORC" SG_ 299 AirTemp_Outsd 350;
BA_ "GenSigTimeout_IC" SG_ 299 AirTemp_Outsd 1050;
BA_ "GenSigTimeout_DTCM" SG_ 299 AirTemp_Outsd 1050;
BA_ "GenSigStartValue" SG_ 299 AirTemp_Outsd 255;
BA_ "GenSigSNA" SG_ 299 AirTemp_Outsd "FFh";
BA_ "GenSigSNA" SG_ 835 N_PDU_343 "0h";
BA_ "GenSigSendType" SG_ 835 N_PDU_343 9;
BA_ "FlexKomSigStartValue" SG_ 835 N_PDU_343 "0000000000000000h";
BA_ "FlexKomSigStartPos" SG_ 835 N_PDU_343 7;
BA_ "FlexKomSigName" SG_ 835 N_PDU_343 "GLIWA_T1_TX";
BA_ "FlexKomSigLaenge" SG_ 835 N_PDU_343 64;
BA_ "FlexKomSID" SG_ 835 N_PDU_343 3166;
BA_ "FlexKomIsMotorola" SG_ 835 N_PDU_343 1;
BA_ "FlexKomComment" SG_ 835 N_PDU_343 "GLIWA_T1_TX";
BA_ "GenSigSNA" SG_ 34 AccPos_PT "FFh";
BA_ "GenSigCycleTime" SG_ 34 AccPos_PT 10;
BA_ "FlexKomSigStartValue" SG_ 34 AccPos_PT "FFFFFF01F40000FFh";
BA_ "FlexKomSigStartPos" SG_ 34 AccPos_PT 7;
BA_ "FlexKomSigName" SG_ 34 AccPos_PT "PT_SYSTEM_1_PKT";
BA_ "FlexKomSigLaenge" SG_ 34 AccPos_PT 64;
BA_ "FlexKomSID" SG_ 34 AccPos_PT 3370;
BA_ "FlexKomIsMotorola" SG_ 34 AccPos_PT 1;
BA_ "FlexKomComment" SG_ 34 AccPos_PT "PT_SYSTEM_1_PKT Packet";
BA_ "GenSigStartValue" SG_ 120 CRC_ESP_A10 255;
BA_ "GenSigSNA" SG_ 120 CRC_ESP_A10 "FFh";
BA_ "GenSigCycleTime" SG_ 120 CRC_ESP_A10 20;
BA_ "FlexKomSigStartValue" SG_ 120 CRC_ESP_A10 "00000000000000FFh";
BA_ "FlexKomSigStartPos" SG_ 120 CRC_ESP_A10 7;
BA_ "FlexKomSigName" SG_ 120 CRC_ESP_A10 "ESP_A10_Pkt";
BA_ "FlexKomSigLaenge" SG_ 120 CRC_ESP_A10 64;
BA_ "FlexKomSID" SG_ 120 CRC_ESP_A10 2964;
BA_ "FlexKomIsMotorola" SG_ 120 CRC_ESP_A10 1;
BA_ "FlexKomComment" SG_ 120 CRC_ESP_A10 "ESP_A10_Pkt";
BA_ "GenSigSNA" SG_ 124 ECM_AllwEV_PHEV "0h";
BA_ "GenSigCycleTime" SG_ 124 ECM_AllwEV_PHEV 20;
BA_ "FlexKomSigStartValue" SG_ 124 ECM_AllwEV_PHEV "FF0000001FFF00FFh";
BA_ "FlexKomSigStartPos" SG_ 124 ECM_AllwEV_PHEV 7;
BA_ "FlexKomSigName" SG_ 124 ECM_AllwEV_PHEV "ECM_A2_PHEV_PKT";
BA_ "FlexKomSigLaenge" SG_ 124 ECM_AllwEV_PHEV 64;
BA_ "FlexKomSID" SG_ 124 ECM_AllwEV_PHEV 2991;
BA_ "FlexKomIsMotorola" SG_ 124 ECM_AllwEV_PHEV 1;
BA_ "FlexKomComment" SG_ 124 ECM_AllwEV_PHEV "ECM_A2_PHEV_PKT";
BA_ "GenSigSNA" SG_ 124 ESS_RqShftPark_PHEV "0h";
BA_ "GenSigCycleTime" SG_ 124 ESS_RqShftPark_PHEV 20;
BA_ "FlexKomSigStartValue" SG_ 124 ESS_RqShftPark_PHEV "FF0000001FFF00FFh";
BA_ "FlexKomSigStartPos" SG_ 124 ESS_RqShftPark_PHEV 7;
BA_ "FlexKomSigName" SG_ 124 ESS_RqShftPark_PHEV "ECM_A2_PHEV_PKT";
BA_ "FlexKomSigLaenge" SG_ 124 ESS_RqShftPark_PHEV 64;
BA_ "FlexKomSID" SG_ 124 ESS_RqShftPark_PHEV 2991;
BA_ "FlexKomIsMotorola" SG_ 124 ESS_RqShftPark_PHEV 1;
BA_ "FlexKomComment" SG_ 124 ESS_RqShftPark_PHEV "ECM_A2_PHEV_PKT";
BA_ "GenSigStartValue" SG_ 124 CRC_ECM_A2_PHEV 255;
BA_ "GenSigSNA" SG_ 124 CRC_ECM_A2_PHEV "FFh";
BA_ "GenSigCycleTime" SG_ 124 CRC_ECM_A2_PHEV 20;
BA_ "FlexKomIsMotorola" SG_ 141 TCASERANGESTATUS 1;
BA_ "FlexKomComment" SG_ 141 TCASERANGESTATUS "DTCM_A1_PKT";
BA_ "GenSigSNA" SG_ 462 MC_DPDM_A2 "0h";
BA_ "GenSigCycleTime" SG_ 462 MC_DPDM_A2 50;
BA_ "FlexKomSigStartValue" SG_ 462 MC_DPDM_A2 "000000FFh";
BA_ "FlexKomSigStartPos" SG_ 462 MC_DPDM_A2 7;
BA_ "FlexKomSigName" SG_ 462 MC_DPDM_A2 "DPDM_A2_PKT";
BA_ "FlexKomSigLaenge" SG_ 462 MC_DPDM_A2 32;
BA_ "FlexKomSID" SG_ 462 MC_DPDM_A2 2683;
BA_ "FlexKomIsMotorola" SG_ 462 MC_DPDM_A2 1;
BA_ "FlexKomComment" SG_ 462 MC_DPDM_A2 "DPDM_A2_PKT";
BA_ "GenSigSNA" SG_ 53 EngStallSts "3h";
BA_ "GenSigCycleTime" SG_ 53 EngStallSts 10;
BA_ "FlexKomSigStartValue" SG_ 53 EngStallSts "5FFF1FFF00FF0FFFh";
BA_ "GenSigStartValue" SG_ 145 CRC_DTCM_A2 255;
BA_ "GenSigSNA" SG_ 145 CRC_DTCM_A2 "FFh";
BA_ "GenSigCycleTime" SG_ 145 CRC_DTCM_A2 20;
BA_ "FlexKomSigStartValue" SG_ 145 CRC_DTCM_A2 "01FF7F00000000FFh";
BA_ "FlexKomSigStartPos" SG_ 145 CRC_DTCM_A2 7;
BA_ "FlexKomSigName" SG_ 145 CRC_DTCM_A2 "DTCM_A2_PKT";
BA_ "FlexKomSigLaenge" SG_ 145 CRC_DTCM_A2 64;
BA_ "FlexKomSID" SG_ 145 CRC_DTCM_A2 1520;
BA_ "FlexKomIsMotorola" SG_ 145 CRC_DTCM_A2 1;
BA_ "FlexKomComment" SG_ 145 CRC_DTCM_A2 "DTCM_A2_PKT";
BA_ "GenSigSNA" SG_ 145 MC_DTCM_A2 "0h";
BA_ "GenSigCycleTime" SG_ 145 MC_DTCM_A2 20;
BA_ "FlexKomSigStartValue" SG_ 145 MC_DTCM_A2 "01FF7F00000000FFh";
BA_ "FlexKomSigStartPos" SG_ 145 MC_DTCM_A2 7;
BA_ "GenSigSNA" SG_ 967 DrvSeatDPFaultSts "0h";
BA_ "GenSigSendType" SG_ 967 DrvSeatDPFaultSts 5;
BA_ "GenSigCycleTime" SG_ 967 DrvSeatDPFaultSts 200;
BA_ "FlexKomSigStartValue" SG_ 967 DrvSeatDPFaultSts "020000FFh";
BA_ "FlexKomSigStartPos" SG_ 967 DrvSeatDPFaultSts 7;
BA_ "FlexKomSigName" SG_ 967 DrvSeatDPFaultSts "DPDM_A1_PKT";
BA_ "FlexKomSigLaenge" SG_ 967 DrvSeatDPFaultSts 32;
BA_ "FlexKomSID" SG_ 967 DrvSeatDPFaultSts 2682;
BA_ "FlexKomIsMotorola" SG_ 967 DrvSeatDPFaultSts 1;
BA_ "FlexKomComment" SG_ 967 DrvSeatDPFaultSts "DPDM_A1_PKT";
BA_ "GenSigTimeout_IC" SG_ 163 DsrSpeed_KPH 210;
BA_ "GenSigStartValue" SG_ 163 DsrSpeed_KPH 255;
BA_ "GenSigSNA" SG_ 163 DsrSpeed_KPH "FFh";
BA_ "GenSigCycleTime" SG_ 163 DsrSpeed_KPH 20;
BA_ "FlexKomSigStartValue" SG_ 163 DsrSpeed_KPH "000000FF000000FFh";
BA_ "FlexKomSigStartPos" SG_ 163 DsrSpeed_KPH 7;
BA_ "FlexKomSigName" SG_ 163 DsrSpeed_KPH "DAS_A5_PKT";
BA_ "FlexKomSigLaenge" SG_ 163 DsrSpeed_KPH 64;
BA_ "FlexKomSID" SG_ 163 DsrSpeed_KPH 2333;
BA_ "FlexKomIsMotorola" SG_ 163 DsrSpeed_KPH 1;
BA_ "FlexKomComment" SG_ 163 DsrSpeed_KPH "DAS_A5 Packet";
BA_ "GenSigSNA" SG_ 834 N_PDU_342 "0h";
BA_ "GenSigSendType" SG_ 834 N_PDU_342 9;
BA_ "FlexKomSigStartValue" SG_ 834 N_PDU_342 "0000000000000000h";
BA_ "FlexKomSigStartPos" SG_ 834 N_PDU_342 7;
BA_ "FlexKomSigName" SG_ 834 N_PDU_342 "GLIWA_T1_TX";
BA_ "FlexKomSigLaenge" SG_ 834 N_PDU_342 64;
BA_ "FlexKomSID" SG_ 834 N_PDU_342 3165;
BA_ "GenSigSNA" SG_ 298 HCP_Comm_Fail_ePT "0h";
BA_ "GenSigSendType" SG_ 298 HCP_Comm_Fail_ePT 5;
BA_ "GenSigCycleTime" SG_ 298 HCP_Comm_Fail_ePT 100;
BA_ "FlexKomSigStartValue" SG_ 298 HCP_Comm_Fail_ePT "01FF0000000000FFh";
BA_ "FlexKomSigStartPos" SG_ 298 HCP_Comm_Fail_ePT 7;
BA_ "FlexKomSigName" SG_ 298 HCP_Comm_Fail_ePT "HCP_100";
BA_ "FlexKomSigLaenge" SG_ 298 HCP_Comm_Fail_ePT 64;
BA_ "FlexKomSID" SG_ 298 HCP_Comm_Fail_ePT 2820;
BA_ "FlexKomIsMotorola" SG_ 298 HCP_Comm_Fail_ePT 1;
BA_ "FlexKomComment" SG_ 298 HCP_Comm_Fail_ePT "HCP_100 message packet";
BA_ "GenSigSNA" SG_ 307 AM_ECM_Trace "3h";
BA_ "GenSigCycleTime" SG_ 307 AM_ECM_Trace 100;
BA_ "FlexKomSigStartValue" SG_ 307 AM_ECM_Trace "00h";
BA_ "FlexKomSigStartPos" SG_ 307 AM_ECM_Trace 23;
BA_ "FlexKomSigName" SG_ 307 AM_ECM_Trace "AM_ECM_Trace";
BA_ "FlexKomSigLaenge" SG_ 307 AM_ECM_Trace 2;
BA_ "FlexKomSID" SG_ 307 AM_ECM_Trace 1942;
BA_ "FlexKomIsMotorola" SG_ 307 AM_ECM_Trace 1;
BA_ "FlexKomComment" SG_ 307 AM_ECM_Trace "Aftermarket ECM trace";
BA_ "GenSigSNA" SG_ 298 Hybrid_Immobilizer_Status "3h";
BA_ "GenSigSendType" SG_ 298 Hybrid_Immobilizer_Status 5;
BA_ "GenSigCycleTime" SG_ 298 Hybrid_Immobilizer_Status 100;
BA_ "FlexKomSigStartValue" SG_ 298 Hybrid_Immobilizer_Status "01FF0000000000FFh";
BA_ "FlexKomSigStartPos" SG_ 298 Hybrid_Immobilizer_Status 7;
BA_ "FlexKomSigName" SG_ 298 Hybrid_Immobilizer_Status "HCP_100";
BA_ "FlexKomSigLaenge" SG_ 298 Hybrid_Immobilizer_Status 64;
BA_ "FlexKomSID" SG_ 298 Hybrid_Immobilizer_Status 2820;
BA_ "FlexKomIsMotorola" SG_ 298 Hybrid_Immobilizer_Status 1;
BA_ "FlexKomComment" SG_ 298 Hybrid_Immobilizer_Status "HCP_100 message packet";
BA_ "GenSigStartValue" SG_ 298 CRC_12Ah 255;
BA_ "GenSigSNA" SG_ 298 CRC_12Ah "FFh";
BA_ "GenSigCycleTime" SG_ 298 CRC_12Ah 100;
BA_ "FlexKomSigStartValue" SG_ 298 CRC_12Ah "01FF0000000000FFh";
BA_ "FlexKomSigStartPos" SG_ 298 CRC_12Ah 7;
BA_ "GenSigTimeout_RF_HUB" SG_ 657 IGN_OFF_TIME_LNG 10500;
BA_ "GenSigTimeout_IC" SG_ 657 IGN_OFF_TIME_LNG 10500;
BA_ "GenSigTimeout_DTCM" SG_ 657 IGN_OFF_TIME_LNG 10500;
BA_ "GenSigStartValue" SG_ 657 IGN_OFF_TIME_LNG 4095;
BA_ "GenSigSNA" SG_ 657 IGN_OFF_TIME_LNG "FFFh";
BA_ "GenSigSendType" SG_ 657 IGN_OFF_TIME_LNG 5;
BA_ "GenSigCycleTime" SG_ 657 IGN_OFF_TIME_LNG 1000;
BA_ "FlexKomSigStartValue" SG_ 657 IGN_OFF_TIME_LNG "0FFFh";
BA_ "FlexKomSigStartPos" SG_ 657 IGN_OFF_TIME_LNG 31;
BA_ "FlexKomSigName" SG_ 657 IGN_OFF_TIME_LNG "IGN_OFF_TIME_LNG";
BA_ "FlexKomSigLaenge" SG_ 657 IGN_OFF_TIME_LNG 16;
BA_ "FlexKomSID" SG_ 657 IGN_OFF_TIME_LNG 998;
BA_ "FlexKomIsMotorola" SG_ 657 IGN_OFF_TIME_LNG 1;
BA_ "FlexKomComment" SG_ 657 IGN_OFF_TIME_LNG "Time since last ignition on (long)";
BA_ "GenSigStartValue" SG_ 657 PTC_REL3_STAT 3;
BA_ "GenSigSNA" SG_ 657 PTC_REL3_STAT "3h";
BA_ "GenSigSendType" SG_ 657 PTC_REL3_STAT 5;
BA_ "GenSigCycleTime" SG_ 657 PTC_REL3_STAT 1000;
BA_ "FlexKomSigStartValue" SG_ 657 PTC_REL3_STAT "3Fh";
BA_ "FlexKomSigStartPos" SG_ 657 PTC_REL3_STAT 47;
BA_ "FlexKomSigName" SG_ 657 PTC_REL3_STAT "PTC_REL_STAT";
BA_ "FlexKomSigLaenge" SG_ 657 PTC_REL3_STAT 6;
BA_ "FlexKomSID" SG_ 657 PTC_REL3_STAT 859;
BA_ "FlexKomIsMotorola" SG_ 657 PTC_REL3_STAT 1;
BA_ "FlexKomComment" SG_ 657 PTC_REL3_STAT "PTC relays status";
BA_ "GenSigSNA" SG_ 53 ThrmlMngActv "0h";
BA_ "GenSigCycleTime" SG_ 53 ThrmlMngActv 10;
BA_ "FlexKomSigStartValue" SG_ 53 ThrmlMngActv "5FFF1FFF00FF0FFFh";
BA_ "FlexKomSigStartPos" SG_ 53 ThrmlMngActv 7;
BA_ "FlexKomSigName" SG_ 53 ThrmlMngActv "ECM_A3_PKT";
BA_ "FlexKomSigLaenge" SG_ 53 ThrmlMngActv 64;
BA_ "FlexKomSID" SG_ 53 ThrmlMngActv 1369;
BA_ "FlexKomIsMotorola" SG_ 53 ThrmlMngActv 1;
BA_ "FlexKomComment" SG_ 53 ThrmlMngActv "ECM_A3 message packet";
VAL_ 37 EngRPM 65535 "SNA";
VAL_ 37 EngTrqStatic 8191 "SNA";
VAL_ 37 ExpEngTrq 8191 "SNA";
VAL_ 119 CmdIgnStat 0 "IGN_LK" 3 "IGN_OFF_ACC" 4 "IGN_RUN" 5 "IGN_START" 7 "SNA";
VAL_ 123 EngTrqSel_D_TTC 8191 "SNA";
VAL_ 123 AccelPdlPosn 255 "SNA";
VAL_ 123 EngTrq_DrvReqMod 8191 "SNA";
VAL_ 141 TCASE_STAT 0 "SH_IPG" 1 "4LO" 2 "4HI" 3 "2WD" 4 "N" 5 "AUTO" 6 "PT" 7 "SNA";
VAL_ 153 DAS_ACCEL_Rq 4095 "SNA";
VAL_ 232 SetSpeed_KPH 255 "SNA";
VAL_ 232 ACCOnOff 0 "OFF" 1 "NCC" 2 "NCC_SET" 3 "ACC_ON" 4 "ACC_SET" 7 "SNA";
VAL_ 299 AirTemp_Outsd 255 "SNA";
VAL_ 299 AMB_TEMP_AVG 65535 "SNA";
VAL_ 299 AMB_TEMP_VOLT 255 "SNA";
VAL_ 299 FUEL_VOLT 255 "SNA";
VAL_ 299 BATT_VOLT 255 "SNA";
VAL_ 155 DriverDoorAjarXtionSts 1 "NONE" 2 "TRNS" 3 "SNA";
VAL_ 155 PsngrDoorAjarXtionSts 1 "NONE" 2 "TRNS" 3 "SNA";
VAL_ 155 AC_OutptCurrStat 255 "SNA";
VAL_ 155 DriverDoorAjarRawValSts 0 "LVL0" 1 "LVL1" 2 "LVL2" 3 "LVL3" 4 "LVL4" 5 "LVL5" 6 "LVL6" 7 "LVL7" 8 "LVL8" 9 "LVL9" 10 "LVL10" 11 "LVL11" 12 "LVL12" 13 "LVL13" 14 "LVL14" 15 "LVL15";
VAL_ 155 PsngrDoorAjarRawValSts 0 "LVL0" 1 "LVL1" 2 "LVL2" 3 "LVL3" 4 "LVL4" 5 "LVL5" 6 "LVL6" 7 "LVL7" 8 "LVL8" 9 "LVL9" 10 "LVL10" 11 "LVL11" 12 "LVL12" 13 "LVL13" 14 "LVL14" 15 "LVL15";
VAL_ 155 BonnetAjarRawValSts 0 "LVL0" 1 "LVL1" 2 "LVL2" 3 "LVL3" 4 "LVL4" 5 "LVL5" 6 "LVL6" 7 "LVL7" 8 "LVL8" 9 "LVL9" 10 "LVL10" 11 "LVL11" 12 "LVL12" 13 "LVL13" 14 "LVL14" 15 "LVL15";
VAL_ 157 ActlAccelPdlPosn 255 "SNA";
VAL_ 560 EVAP_TEMP 255 "SNA";
VAL_ 560 EvapTempTar 255 "SNA";
VAL_ 307 AM_ECM_Trace 0 "DEFAULT" 2 "AM_ECM_TRACE" 3 "SNA";
VAL_ 607 EngineOffTimer 4095 "SNA";
VAL_ 53 EngTrqTgt_SEM 8191 "SNA";
VAL_ 53 EngTrqStatic_SEM 8191 "SNA";
VAL_ 53 TRANS_CLU_SLIP_MODE 0 "NORMAL" 1 "MDS_RQ" 2 "IDFSO_RQ" 3 "AC_EN_DIS_RQ" 4 "IDFSO_ACTIVE" 5 "MDS_IDFSO_ACT" 7 "SNA";
VAL_ 53 EngMaxRPM 255 "SNA";
VAL_ 53 ESS_ENG_ST 1 "ENS_STOPPED" 2 "ENS_RQ_ST" 3 "ENS_RUN" 4 "ENS_STOP_PEND" 5 "ENS_ST_PRTCT" 6 "ENS_ST_INH" 7 "ENS_DSBL" 8 "ENS_IHB_LATCH" 9 "ENS_STARTING" 10 "KEY_START" 11 "ENS_CHANGE_MIND" 15 "SNA";
VAL_ 657 IGN_OFF_TIME_LNG 4095 "SNA";
VAL_ 145 DrvLnTrqRq 511 "SNA";
VAL_ 155 DriverDoor2AjarRawValSts 0 "LVL0" 1 "LVL1" 2 "LVL2" 3 "LVL3" 4 "LVL4" 5 "LVL5" 6 "LVL6" 7 "LVL7" 8 "LVL8" 9 "LVL9" 10 "LVL10" 11 "LVL11" 12 "LVL12" 13 "LVL13" 14 "LVL14" 15 "LVL15";
VAL_ 155 DriverDoor2AjarXtionSts 1 "NONE" 2 "TRNS" 3 "SNA";
VAL_ 560 PTC_Enbl 1 "SNA";
VAL_ 560 SpSt_DsblHVAC 0 "SPST_ON" 1 "CABIN_HI" 2 "CABIN_LO" 3 "MAX_AC" 4 "FT_DEFROST" 5 "EBL" 7 "SNA";
VAL_ 607 GlobDrvMdSts 0 "NONE" 1 "AUTO" 2 "SPORT" 3 "TRACK" 4 "SNOW" 5 "VALET" 6 "ROCK" 7 "TOW" 8 "ECO" 9 "LAUNCH" 10 "ALL" 11 "CUSTOM" 12 "MUD" 13 "SAND" 14 "PLUS" 15 "ICE" 16 "DYNAMIC" 17 "OFFROAD" 31 "SNA";
VAL_ 163 DsrSpeed_KPH 255 "SNA";
VAL_ 167 SyncPos 0 "LOW" 1 "HIGH" 2 "PRESS" 3 "TEMP" 4 "NS" 7 "SNA";
VAL_ 53 EngRdyForESS 0 "SNA";
VAL_ 657 PTC_REL1_STAT 0 "OFF" 1 "ON" 2 "FLT" 3 "SNA";
VAL_ 657 PTC_REL2_STAT 0 "OFF" 1 "ON" 2 "FLT" 3 "SNA";
VAL_ 657 PTC_REL3_STAT 0 "OFF" 1 "ON" 2 "FLT" 3 "SNA";
VAL_ 155 LeakCheckTimerExpired 0 "NOT" 1 "ELAPSED" 3 "SNA";
VAL_ 155 RefuelRequest 0 "NO" 1 "REFUEL" 3 "SNA";
VAL_ 155 FuelDrRelSwRawSt 255 "SNA";
VAL_ 157 Analog_Clutch 255 "SNA";
VAL_ 319 VoltBattFailStatus 0 "Fail_not_present" 1 "Fail_present";
VAL_ 319 RsErrIBS3 0 "NO_ERROR" 1 "ERROR";
VAL_ 319 IBS3_Vbatt 511 "SNA";
VAL_ 319 IBS3_Ibatt 65535 "SNA";
VAL_ 319 IBS3_Error_Internal 0 "NO_ERROR" 1 "ERROR";
VAL_ 319 CurrBattFailStatus 0 "Fail_not_present" 1 "Fail_present";
VAL_ 319 CBCSAMFailSts 0 "Fail_not_present" 1 "Fail_present";
VAL_ 37 ECM_LHOM_Trans 0 "LH_NOT_ACTIVE" 1 "RM_UNAVAILABLE" 2 "PRECISE_TRQ" 3 "IMPRECISE_TRQ";
VAL_ 967 DrvSeatDPSts 0 "Unoccupied" 1 "Occupied" 2 "Undetermined" 3 "SNA";
VAL_ 967 DrvSeatDPFaultSts 0 "NO_FAULT" 1 "FAULTED";
VAL_ 906 VC_VehCfg8_Stat 0 "NA" 1 "PROGAMMED" 2 "REQUEST_DATA" 3 "SNA";
VAL_ 906 VC_Speedometer_Tolerance 0 "Tolerance_0" 1 "Tolerance_1" 2 "Tolerance_2" 3 "Tolerance_3" 4 "Tolerance_4" 5 "Tolerance_5" 6 "Tolerance_6" 7 "Tolerance_7" 8 "Tolerance_8" 9 "Tolerance_9" 10 "Tolerance_10" 11 "Tolerance_Neg1" 12 "Tolerance_Neg2" 13 "Tolerance_Neg3" 14 "Tolerance_Neg4" 15 "Tolerance_Neg5";
VAL_ 906 VC_Increasing_Speed_Constant 0 "Increasing_0" 1 "Increasing_1" 2 "Increasing_2" 3 "Increasing_3" 4 "Increasing_4" 5 "Increasing_5" 6 "Increasing_6" 7 "Increasing_7";
VAL_ 818 A2D_DRV_TEMP_DR_POS 1023 "SNA";
VAL_ 53 EngStallSts 0 "NOT_STALL" 1 "STALL" 3 "SNA";
VAL_ 818 Blower_Speed 511 "SNA";
VAL_ 818 Blower_Diagnostics 1023 "SNA";
VAL_ 181 EngRPM_Tach 65535 "SNA";
VAL_ 833 GPF_T1_Status 0 "PASS" 1 "SHORT_TO_VBAT" 2 "SHORT_TO_GND" 5 "OPEN_CKT" 6 "TC_ASIC" 11 "TC_CJ" 13 "TC_ECU" 16 "NOT_COMPLETE";
VAL_ 906 VC_TACHO_TYPE 0 "DISABLED" 1 "TYP_1" 2 "TYP_2" 3 "TYP_3";
VAL_ 141 TCASERANGESTATUS 0 "HIGH" 1 "NTRL" 2 "LOW" 3 "SNA";
VAL_ 607 CBC_Reset_Flag 0 "DEFAULT" 2 "CBC_RESET_STATUS" 3 "SNA";
VAL_ 54 SumTrqTgt_SEM 8191 "SNA";
VAL_ 54 SumTrqStatic_SEM 8191 "SNA";
VAL_ 120 BrakePedalPressure 2047 "SNA";
VAL_ 120 BrakePdlPosn 255 "SNA";
VAL_ 120 BrakeBoostPressure 2047 "SNA";
VAL_ 38 EngRPM_PHEV 65535 "SNA";
VAL_ 38 EngMaxRPM_PHEV 255 "SNA";
VAL_ 38 ESS_ENG_ST_PHEV 1 "ENS_STOPPED" 2 "ENS_RQ_ST" 3 "ENS_RUN" 4 "ENS_STOP_PEND" 5 "ENS_ST_PRTCT" 6 "ENS_ST_INH" 7 "ENS_DSBL" 8 "ENS_IHB_LATCH" 9 "ENS_STARTING" 10 "KEY_START" 11 "ENS_CHANGE_MIND" 15 "SNA";
VAL_ 38 ECM_LHOM_Trans_PHEV 0 "LH_NOT_ACTIVE" 1 "RM_UNAVAILABLE" 2 "PRECISE_TRQ" 3 "IMPRECISE_TRQ";
VAL_ 38 ECM_IMMO_STAT_CANC_PHEV 0 "IS" 1 "KILL" 2 "RUN" 3 "SNA";
VAL_ 298 Hybrid_Immobilizer_Status 0 "HCPIS" 1 "HCPKILL" 2 "HCPRUN" 3 "SNA";
VAL_ 181 EngineStaticTorqueV 0 "Valid" 1 "Not_Valid";
VAL_ 181 EngineStaticTorque 4095 "SNA";
VAL_ 179 TCM_Comm_Fail_ePT 0 "No_Fault" 1 "TCM_LoC_ePT_ECM" 2 "TCM_LoC_ePT_HCP" 3 "TCM_LoC_ePT_HCP_ECM" 7 "TCM_Bus_Failure_ePT";
VAL_ 56 MotorB_Speed 65535 "SNA";
VAL_ 298 HCP_Comm_Fail_ePT 0 "No_Fault" 1 "HCP_LoC_ePT_TCM" 2 "HCP_LoC_ePT_ECM" 3 "HCP_LoC_ePT_TCM_ECM" 7 "HCP_Bus_Failure_ePT";
VAL_ 124 ECM_Comm_Fail_ePT 0 "No_Fault" 1 "ECM_LoC_ePT_TCM" 2 "ECM_LoC_ePT_HCP" 3 "ECM_LoC_ePT_HCP_TCM" 7 "ECM_Bus_Failure_ePT";
VAL_ 819 ExhaustSwStat 0 "OFF" 1 "CONT" 2 "BLINK" 3 "SNA";
VAL_ 179 OutputSpdPolarity_2 0 "DND" 1 "DF" 2 "DB" 3 "SNA";
VAL_ 34 EngTrq_Enbl_Rq_AS_PT 0 "Not_Valid" 1 "Valid";
VAL_ 34 EngTrq_Enbl_Rq_ESC_PT 0 "Not_Valid" 1 "Valid";
VAL_ 34 CRUISE_OVERRIDE_PT 0 "Not_Valid" 1 "Valid";
VAL_ 34 ActlAccelPdlPosn_PT 255 "SNA";
VAL_ 34 AccPosV_PT 0 "Valid" 1 "Invalid";
VAL_ 34 AccPos_PT 255 "SNA";
VAL_ 323 PCPM_PumpSpeedAct 127 "SNA";
SIG_GROUP_ 157 ECM_A5_Pkt 1 : ActlAccelPdlPosn MC_ECM_A5 CRC_ECM_A5 Analog_Clutch ECM_WARN_BTO;
SIG_GROUP_ 53 ECM_A3_Pkt 1 : EngTrqTgt_SEM EngTrqStatic_SEM TRANS_CLU_SLIP_MODE ThrmlMngActv EngMaxRPM ESS_ENG_ST MC_ECM_A3 CRC_ECM_A3 EngRdyForESS EngStallSts;
SIG_GROUP_ 123 ECM_A2_Pkt 1 : EngTrqSel_D_TTC EngTrq_Enbl_Rq_AS EngTrq_Enbl_Rq_ESC EngTrq_Enbl_Rq_TCM AccelPdlPosn EngTrq_DrvReqMod ECM_LHOM AccelPdlPosnSens_Flt CRUISE_OVERRIDE RPMOverRev LV12PwrFreeRq MC_ECM_A2 CRC_ECM_A2 ESS_RqShftPark;
SIG_GROUP_ 37 ECM_A1_Pkt 1 : EngRPM EngTrqStatic ExpEngTrq MC_ECM_A1 CRC_ECM_A1 ECM_LHOM_Trans;
SIG_GROUP_ 631 DTCM_B1_Pkt 1 : TCASE_FAIL;
SIG_GROUP_ 145 DTCM_A2_Pkt 1 : CRC_DTCM_A2 DrvLnMinTrqMd DrvLnTrqRq MC_DTCM_A2;
SIG_GROUP_ 141 DTCM_A1_Pkt 1 : TCASE_STAT TCASERANGESTATUS;
SIG_GROUP_ 462 DPDM_A2_Pkt 1 : MC_DPDM_A2 CRC_DPDM_A2 DrvPrsnSensorRawValSts;
SIG_GROUP_ 967 DPDM_A1_Pkt 1 : MC_DPDM_A1 DrvSeatDPSts DrvSeatDPFaultSts CRC_DPDM_A1;
SIG_GROUP_ 155 CBC_PT6_Pkt 1 : DriverDoorAjarXtionSts PsngrDoorAjarXtionSts AC_OutptCurrStat DriverDoorAjarRawValSts PsngrDoorAjarRawValSts BonnetAjarRawValSts DriverDoor2AjarRawValSts DriverDoor2AjarXtionSts LeakCheckTimerExpired RefuelRequest FuelDrRelSwRawSt CRC_CBC_PT6 MC_CBC_PT6;
SIG_GROUP_ 179 TCM_ENG_SPD_Pkt 1 : MC_TCM_ENG_SPD CRC_TCM_ENG_SPD OutputSpeed_2 Trans_ESS_Inhibit TCM_Comm_Fail_ePT GearSwitchActiveSts_2 OutputSpdPolarity_2;
SIG_GROUP_ 298 HCP_100_Pkt 1 : Hybrid_Immobilizer_Status MC_12Ah HCP_Comm_Fail_ePT CRC_12Ah;
SIG_GROUP_ 56 HCP_A3_Pkt 1 : MC_HCP_A3 CRC_HCP_A3 MotorB_Speed;
SIG_GROUP_ 54 HCP_A2_Pkt 1 : SumTrqTgt_SEM SumTrqStatic_SEM MC_HCP_A2 CRC_HCP_A2;
SIG_GROUP_ 120 ESP_A10_Pkt 1 : MC_ESP_A10 CRC_ESP_A10 BrakePedalPressure BrakePdlPosn BrakeBoostPressure;
SIG_GROUP_ 124 ECM_A2_PHEV_Pkt 1 : RPMOverRev_PHEV MC_ECM_A2_PHEV LV12PwrFreeRq_PHEV EngTrq_Enbl_Rq_TCM_PHEV EngTrq_Enbl_Rq_ESC_PHEV EngTrq_Enbl_Rq_AS_PHEV ESS_RqShftPark_PHEV ECM_LHOM_PHEV CRUISE_OVERRIDE_PHEV CRC_ECM_A2_PHEV AccelPdlPosnSens_Flt_PHEV ECM_Comm_Fail_ePT ECM_AllwEV_PHEV;
SIG_GROUP_ 38 ECM_A1_PHEV_Pkt 1 : ThrmlMngActv_PHEV MC_ECM_A1_PHEV FullOFC_Actv_PHEV EngRPM_PHEV EngMaxRPM_PHEV ESS_ReqShiftPark_PHEV ESS_ENG_ST_PHEV ECM_LHOM_Trans_PHEV ECM_IMMO_STAT_CANC_PHEV CRC_ECM_A1_PHEV ANL_LFT_PHEV;
SIG_GROUP_ 34 PT_SYSTEM_1_Pkt 1 : EngTrq_Enbl_Rq_AS_PT EngTrq_Enbl_Rq_ESC_PT CRUISE_OVERRIDE_PT ActlAccelPdlPosn_PT AccPosV_PT CRC_PT_SYSTEM_1 MC_PT_SYSTEM_1 AccPos_PT;
